VERSION ""

NS_ :

BS_:

BU_: DAS

BO_ 283 ASD_A2: 5 Vector__XXX
 SG_ CurrentLevel : 16|3@1+ (1,0) [0|7] ""  DAS

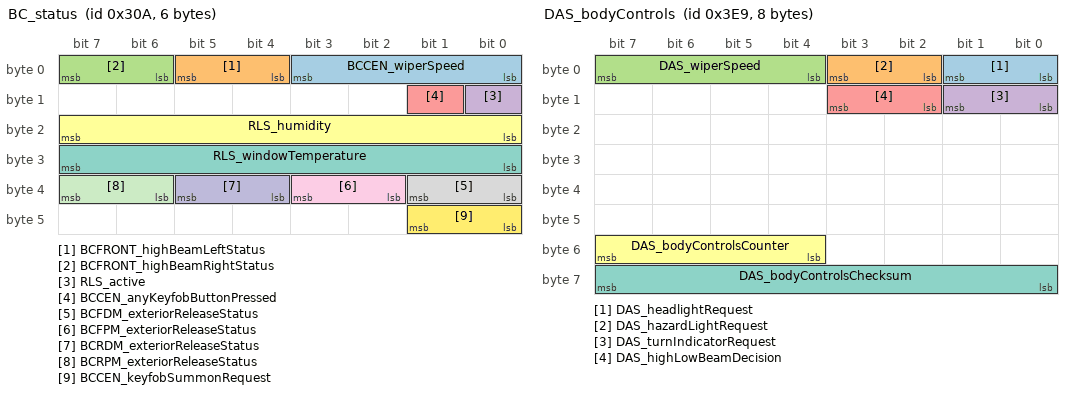
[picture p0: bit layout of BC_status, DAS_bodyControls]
BO_ 778 BC_status: 6 Vector__XXX
 SG_ BCCEN_wiperSpeed : 3|4@0+ (1,0) [0|15] ""  DAS
 SG_ BCFRONT_highBeamLeftStatus : 4|2@1+ (1,0) [0|3] ""  DAS
 SG_ BCFRONT_highBeamRightStatus : 6|2@1+ (1,0) [0|3] ""  DAS
 SG_ RLS_active : 8|1@0+ (1,0) [0|1] ""  DAS
 SG_ BCCEN_anyKeyfobButtonPressed : 9|1@0+ (1,0) [0|1] ""  DAS
 SG_ RLS_humidity : 23|8@0+ (0.5,0) [0|100] "%"  DAS
 SG_ RLS_windowTemperature : 31|8@0+ (0.5,-40) [-40|85] "C"  DAS
 SG_ BCFDM_exteriorReleaseStatus : 32|2@1+ (1,0) [0|3] ""  DAS
 SG_ BCFPM_exteriorReleaseStatus : 34|2@1+ (1,0) [0|3] ""  DAS
 SG_ BCRDM_exteriorReleaseStatus : 36|2@1+ (1,0) [0|3] ""  DAS
 SG_ BCRPM_exteriorReleaseStatus : 38|2@1+ (1,0) [0|3] ""  DAS
 SG_ BCCEN_keyfobSummonRequest : 40|2@1+ (1,0) [0|3] ""  DAS

BO_ 1465 DAS_alertLog: 8 DAS
 SG_ DAS_alertID M : 0|15@1+ (1,0) [0|0] "" Vector__XXX
 SG_ DAS_alertType : 15|1@1+ (1,0) [0|0] "" Vector__XXX
 SG_ DAS_alertDataW0 m0 : 16|16@1+ (1,0) [0|0] "" Vector__XXX
 SG_ DAS_alertDataW1 m0 : 32|16@1+ (1,0) [0|0] "" Vector__XXX
 SG_ DAS_alertDataW2 m0 : 48|16@1+ (1,0) [0|0] "" Vector__XXX
 SG_ DAS_sw004_radHWFailure m4 : 17|1@1+ (1,0) [0|0] "" Vector__XXX
 SG_ DAS_sw004_radSensorBlind m4 : 18|1@1+ (1,0) [0|0] "" Vector__XXX
 SG_ DAS_sw004_radSGUFailure m4 : 19|1@1+ (1,0) [0|0] "" Vector__XXX
 SG_ DAS_sw004_radMia m4 : 20|1@1+ (1,0) [0|0] "" Vector__XXX
 SG_ DAS_sw004_espMIA m4 : 23|1@1+ (1,0) [0|0] "" Vector__XXX
 SG_ DAS_sw004_accState m4 : 24|4@1+ (1,0) [0|0] "" Vector__XXX
 SG_ DAS_sw004_appMobileyeStatus m4 : 28|5@1+ (1,0) [0|0] "" Vector__XXX
 SG_ DAS_sw004_diCruiseStateFault m4 : 33|1@1+ (1,0) [0|0] "" Vector__XXX
 SG_ DAS_sw004_diMIA m4 : 34|1@1+ (1,0) [0|0] "" Vector__XXX
 SG_ DAS_sw004_accelPedalInvalid m4 : 35|1@1+ (1,0) [0|0] "" Vector__XXX
 SG_ DAS_sw004_stwAngleInvalid m4 : 36|1@1+ (1,0) [0|0] "" Vector__XXX
 SG_ DAS_sw004_accelerationInvalid m4 : 37|1@1+ (1,0) [0|0] "" Vector__XXX
 SG_ DAS_sw004_diSpeedInvalid m4 : 38|1@1+ (1,0) [0|0] "" Vector__XXX
 SG_ DAS_sw004_DASFeaturesDisabled m4 : 40|1@1+ (1,0) [0|0] "" Vector__XXX
 SG_ DAS_sw004_appMobileyeNotInVision m4 : 41|1@1+ (1,0) [0|0] "" Vector__XXX
 SG_ DAS_sw004_CamCommonMIA m4 : 42|1@1+ (1,0) [0|0] "" Vector__XXX
 SG_ DAS_sw004_CamObjectsMIA m4 : 43|1@1+ (1,0) [0|0] "" Vector__XXX
 SG_ DAS_sw004_CamWatchdog m4 : 44|1@1+ (1,0) [0|0] "" Vector__XXX
 SG_ DAS_sw004_RadarLowVisibility m4 : 45|1@1+ (1,0) [0|0] "" Vector__XXX
 SG_ DAS_sw004_RadarMisalignment m4 : 46|1@1+ (1,0) [0|0] "" Vector__XXX
 SG_ DAS_sw004_OutOfFocusImage m4 : 47|1@1+ (1,0) [0|0] "" Vector__XXX
 SG_ DAS_sw004_ImpairedVD m4 : 48|1@1+ (1,0) [0|0] "" Vector__XXX
 SG_ DAS_sw004_SunRay m4 : 49|1@1+ (1,0) [0|0] "" Vector__XXX
 SG_ DAS_sw004_Splashes m4 : 50|1@1+ (1,0) [0|0] "" Vector__XXX
 SG_ DAS_sw004_BlurredImage m4 : 51|1@1+ (1,0) [0|0] "" Vector__XXX
 SG_ DAS_sw004_LowSun m4 : 52|1@1+ (1,0) [0|0] "" Vector__XXX
 SG_ DAS_sw004_SmearedSpots m4 : 53|1@1+ (1,0) [0|0] "" Vector__XXX
 SG_ DAS_sw004_PartialBlockage m4 : 54|1@1+ (1,0) [0|0] "" Vector__XXX
 SG_ DAS_sw004_AutofixOutOfCalib m4 : 55|1@1+ (1,0) [0|0] "" Vector__XXX
 SG_ DAS_sw004_AutofixOutOfCalibHorzn m4 : 56|1@1+ (1,0) [0|0] "" Vector__XXX
 SG_ DAS_sw004_AutofixOutOfCalibYaw m4 : 57|1@1+ (1,0) [0|0] "" Vector__XXX
 SG_ DAS_sw004_FullBlockage m4 : 58|1@1+ (1,0) [0|0] "" Vector__XXX
 SG_ DAS_sw004_SmearedHalos m4 : 59|1@1+ (1,0) [0|0] "" Vector__XXX
 SG_ DAS_sw004_FoggyLights m4 : 60|1@1+ (1,0) [0|0] "" Vector__XXX
 SG_ DAS_sw004_SelfGlare m4 : 61|1@1+ (1,0) [0|0] "" Vector__XXX
 SG_ DAS_sw005_AutofixOutOfCalib m5 : 16|1@1+ (1,0) [0|0] "" Vector__XXX
 SG_ DAS_sw005_AutofixOutOfCalibYaw m5 : 17|1@1+ (1,0) [0|0] "" Vector__XXX
 SG_ DAS_sw005_RadarMisalignment m5 : 18|1@1+ (1,0) [0|0] "" Vector__XXX
 SG_ DAS_sw005_partialBlockage m5 : 20|1@1+ (1,0) [0|0] "" Vector__XXX
 SG_ DAS_sw005_fullBlockage m5 : 21|1@1+ (1,0) [0|0] "" Vector__XXX
 SG_ DAS_sw005_camObjHeader m5 : 22|1@1+ (1,0) [0|0] "" Vector__XXX
 SG_ DAS_sw005_camCommonMsg m5 : 23|1@1+ (1,0) [0|0] "" Vector__XXX
 SG_ DAS_sw005_camFcwPcwMsg m5 : 24|1@1+ (1,0) [0|0] "" Vector__XXX
 SG_ DAS_sw005_radHWFailure m5 : 25|1@1+ (1,0) [0|0] "" Vector__XXX
 SG_ DAS_sw005_radSensorBlind m5 : 26|1@1+ (1,0) [0|0] "" Vector__XXX
 SG_ DAS_sw005_radSGUFailure m5 : 27|1@1+ (1,0) [0|0] "" Vector__XXX
 SG_ DAS_sw005_radMia m5 : 28|1@1+ (1,0) [0|0] "" Vector__XXX
 SG_ DAS_sw005_brakePedal m5 : 29|1@1+ (1,0) [0|0] "" Vector__XXX
 SG_ DAS_sw005_steeringAngle m5 : 30|1@1+ (1,0) [0|0] "" Vector__XXX
 SG_ DAS_sw005_steeringAngleRate m5 : 31|1@1+ (1,0) [0|0] "" Vector__XXX
 SG_ DAS_sw005_speed m5 : 32|1@1+ (1,0) [0|0] "" Vector__XXX
 SG_ DAS_sw005_gear m5 : 33|1@1+ (1,0) [0|0] "" Vector__XXX
 SG_ DAS_sw005_espState m5 : 34|1@1+ (1,0) [0|0] "" Vector__XXX
 SG_ DAS_sw005_blinkers m5 : 35|1@1+ (1,0) [0|0] "" Vector__XXX
 SG_ DAS_sw005_yaw m5 : 36|1@1+ (1,0) [0|0] "" Vector__XXX
 SG_ DAS_sw005_longAccel m5 : 37|1@1+ (1,0) [0|0] "" Vector__XXX
 SG_ DAS_sw005_accelPedal m5 : 38|1@1+ (1,0) [0|0] "" Vector__XXX
 SG_ DAS_sw005_torqueDriver m5 : 40|1@1+ (1,0) [0|0] "" Vector__XXX
 SG_ DAS_sw005_fcmSensitivity m5 : 41|1@1+ (1,0) [0|0] "" Vector__XXX
 SG_ DAS_sw005_dasDisabled m5 : 42|1@1+ (1,0) [0|0] "" Vector__XXX
 SG_ DAS_sw005_speedDerivative m5 : 43|1@1+ (1,0) [0|0] "" Vector__XXX
 SG_ DAS_sw005_camWatchdog m5 : 44|1@1+ (1,0) [0|0] "" Vector__XXX
 SG_ DAS_sw005_AutofixOutOfCalibHorzn m5 : 45|1@1+ (1,0) [0|0] "" Vector__XXX
 SG_ DAS_sw005_RadarLowVisibility m5 : 46|1@1+ (1,0) [0|0] "" Vector__XXX
 SG_ DAS_sw006_RadarLowVisibility m6 : 16|1@1+ (1,0) [0|0] "" Vector__XXX
 SG_ DAS_sw006_RadarMisaligned m6 : 17|1@1+ (1,0) [0|0] "" Vector__XXX
 SG_ DAS_sw006_OutOfFocusImage m6 : 18|1@1+ (1,0) [0|0] "" Vector__XXX
 SG_ DAS_sw006_SunRay m6 : 19|1@1+ (1,0) [0|0] "" Vector__XXX
 SG_ DAS_sw006_Splashes m6 : 20|1@1+ (1,0) [0|0] "" Vector__XXX
 SG_ DAS_sw006_BlurredImage m6 : 21|1@1+ (1,0) [0|0] "" Vector__XXX
 SG_ DAS_sw006_LowSun m6 : 22|1@1+ (1,0) [0|0] "" Vector__XXX
 SG_ DAS_sw006_SmearedSpots m6 : 23|1@1+ (1,0) [0|0] "" Vector__XXX
 SG_ DAS_sw006_PartialBlockage m6 : 24|1@1+ (1,0) [0|0] "" Vector__XXX
 SG_ DAS_sw006_AutofixOutOfCalib m6 : 25|1@1+ (1,0) [0|0] "" Vector__XXX
 SG_ DAS_sw006_AutofixOutOfCalibHorzn m6 : 26|1@1+ (1,0) [0|0] "" Vector__XXX
 SG_ DAS_sw006_AutofixOutOfCalibYaw m6 : 27|1@1+ (1,0) [0|0] "" Vector__XXX
 SG_ DAS_sw006_FullBlockage m6 : 28|1@1+ (1,0) [0|0] "" Vector__XXX
 SG_ DAS_sw006_SmearedHalos m6 : 29|1@1+ (1,0) [0|0] "" Vector__XXX
 SG_ DAS_sw006_FoggyLights m6 : 30|1@1+ (1,0) [0|0] "" Vector__XXX
 SG_ DAS_sw006_SelfGlare m6 : 31|1@1+ (1,0) [0|0] "" Vector__XXX
 SG_ DAS_sw006_blinkers m6 : 32|1@1+ (1,0) [0|0] "" Vector__XXX
 SG_ DAS_sw006_seatbelt m6 : 33|1@1+ (1,0) [0|0] "" Vector__XXX
 SG_ DAS_sw006_accelPedal m6 : 34|1@1+ (1,0) [0|0] "" Vector__XXX
 SG_ DAS_sw006_radMia m6 : 35|1@1+ (1,0) [0|0] "" Vector__XXX
 SG_ DAS_sw006_radHWFailure m6 : 37|1@1+ (1,0) [0|0] "" Vector__XXX
 SG_ DAS_sw006_radSensorBlind m6 : 38|1@1+ (1,0) [0|0] "" Vector__XXX
 SG_ DAS_sw006_radSGUFailure m6 : 39|1@1+ (1,0) [0|0] "" Vector__XXX
 SG_ DAS_sw006_brakePedal m6 : 40|1@1+ (1,0) [0|0] "" Vector__XXX
 SG_ DAS_sw006_steeringAngle m6 : 41|1@1+ (1,0) [0|0] "" Vector__XXX
 SG_ DAS_sw006_steeringAngleRate m6 : 42|1@1+ (1,0) [0|0] "" Vector__XXX
 SG_ DAS_sw006_speed m6 : 43|1@1+ (1,0) [0|0] "" Vector__XXX
 SG_ DAS_sw006_gear m6 : 44|1@1+ (1,0) [0|0] "" Vector__XXX
 SG_ DAS_sw006_espState m6 : 45|1@1+ (1,0) [0|0] "" Vector__XXX
 SG_ DAS_sw006_torqueDriver m6 : 46|1@1+ (1,0) [0|0] "" Vector__XXX
 SG_ DAS_sw006_dasDisabled m6 : 47|1@1+ (1,0) [0|0] "" Vector__XXX
 SG_ DAS_sw006_speedDerivative m6 : 48|1@1+ (1,0) [0|0] "" Vector__XXX
 SG_ DAS_sw006_camWatchdog m6 : 49|1@1+ (1,0) [0|0] "" Vector__XXX
 SG_ DAS_sw006_camObjHeader m6 : 50|1@1+ (1,0) [0|0] "" Vector__XXX
 SG_ DAS_sw006_camCommonMsg m6 : 51|1@1+ (1,0) [0|0] "" Vector__XXX
 SG_ DAS_sw006_camFcwPcwMsg m6 : 52|1@1+ (1,0) [0|0] "" Vector__XXX
 SG_ DAS_sw006_longAccel m6 : 53|1@1+ (1,0) [0|0] "" Vector__XXX
 SG_ DAS_sw006_yawRate m6 : 54|1@1+ (1,0) [0|0] "" Vector__XXX
 SG_ DAS_sw006_DIaebState_SNA m6 : 55|1@1+ (1,0) [0|0] "" Vector__XXX
 SG_ DAS_sw006_DIaebStateUnavailable m6 : 56|1@1+ (1,0) [0|0] "" Vector__XXX
 SG_ DAS_sw006_brakeLights m6 : 57|1@1+ (1,0) [0|0] "" Vector__XXX
 SG_ DAS_sw006_trailerMode m6 : 58|1@1+ (1,0) [0|0] "" Vector__XXX
 SG_ DAS_sw006_timeOfDay m6 : 59|2@1+ (1,0) [0|0] "" Vector__XXX
 SG_ DAS_sw009_DIaebState_fault m9 : 16|1@1+ (1,0) [0|0] "" Vector__XXX
 SG_ DAS_sw009_DI_aeb_unresponsive m9 : 17|1@1+ (1,0) [0|0] "" Vector__XXX
 SG_ DAS_sw009_DI_MIA m9 : 18|1@1+ (1,0) [0|0] "" Vector__XXX
 SG_ DAS_sw010_a04calibNotDone m10 : 16|1@1+ (1,0) [0|0] "" Vector__XXX
 SG_ DAS_sw010_a05calibReqd m10 : 17|1@1+ (1,0) [0|0] "" Vector__XXX
 SG_ DAS_sw010_a06calibNotOK m10 : 18|1@1+ (1,0) [0|0] "" Vector__XXX
 SG_ DAS_sw010_a08PlantMode m10 : 19|1@1+ (1,0) [0|0] "" Vector__XXX
 SG_ DAS_sw010_HorizontalMisalignment m10 : 20|16@1+ (0.00137332,-45) [-45|45.0005262] "deg" Vector__XXX
 SG_ DAS_sw010_VerticalMisalignment m10 : 36|10@1+ (0.087977,-45) [-45|45.000471] "deg" Vector__XXX
 SG_ DAS_sw010_unusedBits m10 : 46|2@1+ (1,0) [0|0] "" Vector__XXX
 SG_ DAS_sw010_VmaPlausibility m10 : 48|16@1+ (1.52587890625005E-005,0) [0|0.99998474121097] "" Vector__XXX
 SG_ DAS_sw011_scaState m11 : 16|3@1+ (1,0) [0|7] "" Vector__XXX
 SG_ DAS_sw011_scaLeft m11 : 19|1@1+ (1,0) [0|1] "" Vector__XXX
 SG_ DAS_sw011_scaRight m11 : 20|1@1+ (1,0) [0|1] "" Vector__XXX
 SG_ DAS_sw011_scaBlinker m11 : 21|2@1+ (1,0) [0|3] "" Vector__XXX
 SG_ DAS_sw011_scaThreshold m11 : 23|1@1+ (1,0) [0|1] "" Vector__XXX
 SG_ DAS_sw011_scaSpeed m11 : 24|7@1+ (1,0) [0|127] "MPH" Vector__XXX
 SG_ DAS_sw011_scaSonicDist m11 : 31|5@1+ (0.05,0) [0|1.5] "m" Vector__XXX
 SG_ DAS_sw011_scaSteerAngle m11 : 38|10@1+ (0.1,-51.2) [-51.2|51.1] "deg" Vector__XXX
 SG_ DAS_sw011_egoRightOfCenter m11 : 48|1@1+ (1,0) [0|1] "" Vector__XXX
 SG_ DAS_sw011_egoMovingRight m11 : 49|1@1+ (1,0) [0|1] "" Vector__XXX
 SG_ DAS_sw011_egoLeftOfCenter m11 : 50|1@1+ (1,0) [0|1] "" Vector__XXX
 SG_ DAS_sw011_egoMovingLeft m11 : 51|1@1+ (1,0) [0|1] "" Vector__XXX
 SG_ DAS_sw011_polyValid m11 : 52|1@1+ (1,0) [0|1] "" Vector__XXX
 SG_ DAS_sw011_egoCentered m11 : 53|1@1+ (1,0) [0|1] "" Vector__XXX
 SG_ DAS_sw011_scaReasonEldw m11 : 54|1@1+ (1,0) [0|1] "" Vector__XXX
 SG_ DAS_sw011_laneWidth m11 : 56|8@1+ (0.025,0) [0|6.375] "m" Vector__XXX
 SG_ DAS_sw012_bootTestResults m12 : 16|16@1+ (1,0) [0|65535] "" Vector__XXX
 SG_ DAS_sw012_bootDDRTempStatus m12 : 32|2@1+ (1,0) [0|3] "" Vector__XXX
 SG_ DAS_sw012_mespFatalErrCode m12 : 34|8@1+ (1,0) [0|255] "" Vector__XXX
 SG_ DAS_sw012_mespFatalErrDetails m12 : 42|8@1+ (1,0) [0|255] "" Vector__XXX
 SG_ DAS_sw012_mespDDRTempStatus m12 : 50|3@1+ (1,0) [0|7] "" Vector__XXX
 SG_ DAS_sw012_freescaleTemp m12 : 56|8@1- (1,0) [-128|127] "degC" Vector__XXX
 SG_ DAS_sw013_stateBeforeWatchdog m13 : 16|5@1+ (1,0) [0|0] "" Vector__XXX
 SG_ DAS_sw013_numEyeqResets m13 : 21|3@1+ (1,0) [0|0] "" Vector__XXX
 SG_ DAS_sw013_numCrcErrors m13 : 24|8@1+ (1,0) [0|0] "" Vector__XXX
 SG_ DAS_sw013_numSeqErrors m13 : 32|8@1+ (1,0) [0|0] "" Vector__XXX
 SG_ DAS_sw013_numNaksReceived m13 : 40|8@1+ (1,0) [0|0] "" Vector__XXX
 SG_ DAS_sw013_highestSeqRecd m13 : 48|12@1+ (1,0) [0|0] "" Vector__XXX
 SG_ DAS_sw013_numTransportErrors m13 : 60|4@1+ (1,0) [0|0] "" Vector__XXX
 SG_ DAS_sw014_fileNameHash m14 : 16|16@1+ (1,0) [0|0] "" Vector__XXX
 SG_ DAS_sw014_lineNumberInCode m14 : 32|16@1+ (1,0) [0|0] "" Vector__XXX
 SG_ DAS_sw014_assertData m14 : 48|16@1+ (1,0) [0|0] "" Vector__XXX
 SG_ DAS_sw015_RadarLowVisibility m15 : 16|2@1+ (1,0) [0|1] "" Vector__XXX
 SG_ DAS_sw015_RadarMisalignment m15 : 18|2@1+ (1,0) [0|1] "" Vector__XXX
 SG_ DAS_sw015_LowSun m15 : 20|2@1+ (1,0) [0|1] "" Vector__XXX
 SG_ DAS_sw015_BlurredImage m15 : 22|2@1+ (1,0) [0|1] "" Vector__XXX
 SG_ DAS_sw015_FullBlockage m15 : 24|2@1+ (1,0) [0|1] "" Vector__XXX
 SG_ DAS_sw015_PartialBlockage m15 : 26|2@1+ (1,0) [0|1] "" Vector__XXX
 SG_ DAS_sw015_AutofixOutOfCalib m15 : 28|2@1+ (1,0) [0|1] "" Vector__XXX
 SG_ DAS_sw015_AutofixOutOfCalibYaw m15 : 30|2@1+ (1,0) [0|1] "" Vector__XXX
 SG_ DAS_sw015_AutofixOOfCalibHorizon m15 : 32|2@1+ (1,0) [0|1] "" Vector__XXX
 SG_ DAS_sw015_Splashes m15 : 34|2@1+ (1,0) [0|1] "" Vector__XXX
 SG_ DAS_sw015_SmearedSpots m15 : 36|2@1+ (1,0) [0|1] "" Vector__XXX
 SG_ DAS_sw015_SmearedHalos m15 : 38|2@1+ (1,0) [0|1] "" Vector__XXX
 SG_ DAS_sw015_FoggyLights m15 : 40|2@1+ (1,0) [0|1] "" Vector__XXX
 SG_ DAS_sw015_SunRay m15 : 42|2@1+ (1,0) [0|1] "" Vector__XXX
 SG_ DAS_sw015_ImpairedVD m15 : 44|2@1+ (1,0) [0|1] "" Vector__XXX
 SG_ DAS_sw015_SelfGlare m15 : 46|2@1+ (1,0) [0|1] "" Vector__XXX
 SG_ DAS_sw015_OutOfFocusImage m15 : 48|2@1+ (1,0) [0|1] "" Vector__XXX
 SG_ DAS_sw015_MainCameraLowLight m15 : 50|2@1+ (1,0) [0|1] "" Vector__XXX
 SG_ DAS_sw015_NarrowCameraLowLight m15 : 52|2@1+ (1,0) [0|1] "" Vector__XXX
 SG_ DAS_sw015_MainCameraBadAssoc m15 : 54|2@1+ (1,0) [0|1] "" Vector__XXX
 SG_ DAS_sw015_NarrowCameraBadAssoc m15 : 56|2@1+ (1,0) [0|1] "" Vector__XXX
 SG_ DAS_sw016_targetDist m16 : 16|9@1+ (0.2,0) [0|102.2] "m" Vector__XXX
 SG_ DAS_sw016_targetRelSpeed m16 : 25|9@1+ (0.0625,-31) [-31|0.9375] "m/s" Vector__XXX
 SG_ DAS_sw016_targetOverlap m16 : 34|6@1+ (0.1,0) [0|6.3] "m" Vector__XXX
 SG_ DAS_sw016_hostSpeed m16 : 40|8@1+ (1,0) [0|255] "kph" Vector__XXX
 SG_ DAS_sw016_hostLongAccel m16 : 48|7@1+ (0.15625,-10) [-10|10] "m/s^2" Vector__XXX
 SG_ DAS_sw016_driverPressedAccelPed m16 : 55|1@1+ (1,0) [0|1] "" Vector__XXX
 SG_ DAS_sw016_driverPressedBrakePed m16 : 56|1@1+ (1,0) [0|1] "" Vector__XXX
 SG_ DAS_sw016_aebEnable m16 : 57|1@1+ (1,0) [0|1] "" Vector__XXX
 SG_ DAS_sw016_overrideBlinker m16 : 58|1@1+ (1,0) [0|1] "" Vector__XXX
 SG_ DAS_sw016_overrideBrake m16 : 59|1@1+ (1,0) [0|1] "" Vector__XXX
 SG_ DAS_sw016_overrideSteer m16 : 60|1@1+ (1,0) [0|1] "" Vector__XXX
 SG_ DAS_sw016_fcmModeAtEvent m16 : 61|2@1+ (1,0) [0|3] "" Vector__XXX
 SG_ DAS_sw016_accActive m16 : 63|1@1+ (1,0) [0|1] "" Vector__XXX
 SG_ DAS_sw017_Camera_Msg_Lanes_MIA m17 : 16|1@1+ (1,0) [0|1] "" Vector__XXX
 SG_ DAS_sw017_Camera_Msg_Objects_MIA m17 : 17|1@1+ (1,0) [0|1] "" Vector__XXX
 SG_ DAS_sw017_Camera_Msg_Tsr_MIA m17 : 18|1@1+ (1,0) [0|1] "" Vector__XXX
 SG_ DAS_sw017_Camera_Msg_Hlb_MIA m17 : 19|1@1+ (1,0) [0|1] "" Vector__XXX
 SG_ DAS_sw017_Camera_Msg_Common_MIA m17 : 20|1@1+ (1,0) [0|1] "" Vector__XXX
 SG_ DAS_sw017_Camera_Msg_FCW_PCW_MIA m17 : 21|1@1+ (1,0) [0|1] "" Vector__XXX
 SG_ DAS_sw017_Camera_Msg_TFL_MIA m17 : 22|1@1+ (1,0) [0|1] "" Vector__XXX
 SG_ DAS_sw017_Any_Lanes_Msg_Recd m17 : 23|1@1+ (1,0) [0|1] "" Vector__XXX
 SG_ DAS_sw017_Any_Objects_Msg_Recd m17 : 24|1@1+ (1,0) [0|1] "" Vector__XXX
 SG_ DAS_sw017_Any_TFL_Msg_Recd m17 : 25|1@1+ (1,0) [0|1] "" Vector__XXX
 SG_ DAS_sw017_numCrcErrors m17 : 26|6@1+ (1,0) [0|63] "" Vector__XXX
 SG_ DAS_sw017_numSeqErrors m17 : 32|8@1+ (1,0) [0|255] "" Vector__XXX
 SG_ DAS_sw017_numTransportErrors m17 : 40|8@1+ (1,0) [0|0] "" Vector__XXX
 SG_ DAS_sw017_highestSeqRecd m17 : 48|12@1+ (1,0) [0|0] "" Vector__XXX
 SG_ DAS_sw017_Any_Tsr_Msg_Recd m17 : 60|1@1+ (1,0) [0|1] "" Vector__XXX
 SG_ DAS_sw017_Any_Hlb_Msg_Recd m17 : 61|1@1+ (1,0) [0|1] "" Vector__XXX
 SG_ DAS_sw017_Any_Common_Msg_Recd m17 : 62|1@1+ (1,0) [0|1] "" Vector__XXX
 SG_ DAS_sw017_Any_FCW_PCW_Msg_Recd m17 : 63|1@1+ (1,0) [0|1] "" Vector__XXX
 SG_ DAS_sw018_minThreshold m18 : 16|13@1+ (1,0) [0|4500] "mV" Vector__XXX
 SG_ DAS_sw018_railID m18 : 29|2@1+ (1,0) [0|3] "" Vector__XXX
 SG_ DAS_sw018_powerSequnceError m18 : 31|1@1+ (1,0) [0|3] "" Vector__XXX
 SG_ DAS_sw018_maxThreshold m18 : 32|15@1+ (1,0) [50|5500] "mV" Vector__XXX
 SG_ DAS_sw018_railControl m18 : 47|1@1+ (1,0) [0|1] "" Vector__XXX
 SG_ DAS_sw018_currentVoltage m18 : 48|16@1+ (1,0) [0|6600] "mV" Vector__XXX
 SG_ DAS_sw019_taskId m19 : 16|8@1+ (1,0) [0|0] "" Vector__XXX
 SG_ DAS_sw019_numFreeBytes m19 : 24|8@1+ (1,-191) [-191|64] "# of bytes" Vector__XXX
 SG_ DAS_sw019_timeStamp m19 : 32|32@1+ (1,0) [0|4294967295] "ms" Vector__XXX
 SG_ DAS_sw020_unusedW0 m20 : 16|16@1+ (1,0) [0|0] "" Vector__XXX
 SG_ DAS_sw020_unusedW1 m20 : 32|16@1+ (1,0) [0|0] "" Vector__XXX
 SG_ DAS_sw020_unusedW2 m20 : 48|16@1+ (1,0) [0|0] "" Vector__XXX
 SG_ DAS_sw021_tempSensorId m21 : 16|8@1+ (1,0) [0|4] "" Vector__XXX
 SG_ DAS_sw021_minThreshold m21 : 24|8@1- (1,0) [-128|127] "degC" Vector__XXX
 SG_ DAS_sw021_maxThreshold m21 : 32|8@1- (1,0) [-128|127] "degC" Vector__XXX
 SG_ DAS_sw021_currentTemperature m21 : 40|8@1- (1,0) [-128|127] "degC" Vector__XXX
 SG_ DAS_sw021_unusedWord m21 : 48|16@1+ (1,0) [0|0] "" Vector__XXX
 SG_ DAS_sw022_operation m22 : 16|4@1+ (1,0) [0|0] "" Vector__XXX
 SG_ DAS_sw022_recordId m22 : 20|12@1+ (1,0) [0|0] "" Vector__XXX
 SG_ DAS_sw022_errorCode m22 : 32|32@1+ (1,0) [0|0] "" Vector__XXX
 SG_ DAS_sw024_Task_ID m24 : 16|4@1+ (1,0) [0|0] "" Vector__XXX
 SG_ DAS_sw024_numVirtualLaneVeh m24 : 20|4@1+ (1,0) [0|0] "" Vector__XXX
 SG_ DAS_sw024_currentVehicleApp m24 : 24|8@1+ (1,0) [0|0] "" Vector__XXX
 SG_ DAS_sw024_taskProgramCounter m24 : 32|32@1+ (1,0) [0|0] "" Vector__XXX
 SG_ DAS_sw025_state_before_override m25 : 16|4@1+ (1,0) [0|15] "" Vector__XXX
 SG_ DAS_sw025_road_class m25 : 20|3@1+ (1,0) [0|0] "" Vector__XXX
 SG_ DAS_sw025_road_match m25 : 23|1@1+ (1,0) [0|0] "" Vector__XXX
 SG_ DAS_sw025_controlled_access m25 : 24|1@1+ (1,0) [0|0] "" Vector__XXX
 SG_ DAS_sw025_leftLaneUsage m25 : 25|2@1+ (1,0) [0|3] "" Vector__XXX
 SG_ DAS_sw025_rightLaneUsage m25 : 27|2@1+ (1,0) [0|3] "" Vector__XXX
 SG_ DAS_sw025_vehiclesUsage m25 : 29|2@1+ (1,0) [0|3] "" Vector__XXX
 SG_ DAS_sw025_hppUsage m25 : 31|2@1+ (1,0) [0|3] "" Vector__XXX
 SG_ DAS_sw025_navigationUsage m25 : 33|2@1+ (1,0) [0|3] "" Vector__XXX
 SG_ DAS_sw025_modelUsage m25 : 35|2@1+ (1,0) [0|3] "" Vector__XXX
 SG_ DAS_sw025_bottsDotsUsage m25 : 37|2@1+ (1,0) [0|3] "" Vector__XXX
 SG_ DAS_sw025_offsetSide m25 : 39|2@1+ (1,0) [0|3] "" Vector__XXX
 SG_ DAS_sw026_task_id m26 : 16|2@1+ (1,0) [0|3] "" Vector__XXX
 SG_ DAS_sw026_tardiness m26 : 18|9@1+ (0.25,0) [0|127.75] "ms" Vector__XXX
 SG_ DAS_sw026_execution_time m26 : 27|9@1+ (0.125,0) [0|65.411] "ms" Vector__XXX
 SG_ DAS_sw026_can_mean_utilization m26 : 36|7@1+ (1,0) [0|127] "percent" Vector__XXX
 SG_ DAS_sw026_uds_mean_utilization m26 : 43|7@1+ (1,0) [0|127] "percent" Vector__XXX
 SG_ DAS_sw026_mob_mean_utilization m26 : 50|7@1+ (1,0) [0|127] "percent" Vector__XXX
 SG_ DAS_sw026_veh_mean_utilization m26 : 57|7@1+ (1,0) [0|127] "percent" Vector__XXX
 SG_ DAS_sw027_JTAG_Reset m27 : 16|1@1+ (1,0) [0|0] "" Vector__XXX
 SG_ DAS_sw027_Core_Reset m27 : 17|1@1+ (1,0) [0|0] "" Vector__XXX
 SG_ DAS_sw027_Unused_Bit_0 m27 : 18|1@1+ (1,0) [0|0] "" Vector__XXX
 SG_ DAS_sw027_CPU_Checkstop_Error m27 : 19|1@1+ (1,0) [0|0] "" Vector__XXX
 SG_ DAS_sw027_PLL_0_Failure m27 : 20|1@1+ (1,0) [0|0] "" Vector__XXX
 SG_ DAS_sw027_Clock_Monitor_0_Low m27 : 21|1@1+ (1,0) [0|0] "" Vector__XXX
 SG_ DAS_sw027_Clock_Monitor_0_Off m27 : 22|1@1+ (1,0) [0|0] "" Vector__XXX
 SG_ DAS_sw027_LVD_4v5 m27 : 23|1@1+ (1,0) [0|0] "" Vector__XXX
 SG_ DAS_sw027_Flash_Fatal_Error m27 : 24|1@1+ (1,0) [0|0] "" Vector__XXX
 SG_ DAS_sw027_PLL_1_Failure m27 : 25|1@1+ (1,0) [0|0] "" Vector__XXX
 SG_ DAS_sw027_Unused_Bit_1 m27 : 26|1@1+ (1,0) [0|0] "" Vector__XXX
 SG_ DAS_sw027_f_PLL_1_Off m27 : 27|1@1+ (1,0) [0|0] "" Vector__XXX
 SG_ DAS_sw027_Unused_Nibble m27 : 28|4@1+ (1,0) [0|0] "" Vector__XXX
 SG_ DAS_sw027_LVD_1v2 m27 : 32|1@1+ (1,0) [0|0] "" Vector__XXX
 SG_ DAS_sw027_Unused_Bit_2 m27 : 33|1@1+ (1,0) [0|0] "" Vector__XXX
 SG_ DAS_sw027_Watchdog m27 : 34|1@1+ (1,0) [0|0] "" Vector__XXX
 SG_ DAS_sw027_Unused_Bit_3 m27 : 35|1@1+ (1,0) [0|0] "" Vector__XXX
 SG_ DAS_sw027_LVD_2v7_VREG m27 : 36|1@1+ (1,0) [0|0] "" Vector__XXX
 SG_ DAS_sw027_LVD_2v7_Flash m27 : 37|1@1+ (1,0) [0|0] "" Vector__XXX
 SG_ DAS_sw027_LVD_2v7_IO m27 : 38|1@1+ (1,0) [0|0] "" Vector__XXX
 SG_ DAS_sw027_Unused_Bit_4 m27 : 39|1@1+ (1,0) [0|0] "" Vector__XXX
 SG_ DAS_sw027_Unused_Byte m27 : 40|8@1+ (1,0) [0|0] "" Vector__XXX
 SG_ DAS_sw027_ESR0 m27 : 48|1@1+ (1,0) [0|0] "" Vector__XXX
 SG_ DAS_sw027_ESR1 m27 : 49|1@1+ (1,0) [0|0] "" Vector__XXX
 SG_ DAS_sw027_SW m27 : 50|1@1+ (1,0) [0|0] "" Vector__XXX
 SG_ DAS_sw027_STM0 m27 : 51|1@1+ (1,0) [0|0] "" Vector__XXX
 SG_ DAS_sw027_STM1 m27 : 52|1@1+ (1,0) [0|0] "" Vector__XXX
 SG_ DAS_sw027_STM2 m27 : 53|1@1+ (1,0) [0|0] "" Vector__XXX
 SG_ DAS_sw027_CBS_SYSTEM m27 : 54|1@1+ (1,0) [0|0] "" Vector__XXX
 SG_ DAS_sw027_CBS_DEBUG m27 : 55|1@1+ (1,0) [0|0] "" Vector__XXX
 SG_ DAS_sw027_CBS_APP m27 : 56|1@1+ (1,0) [0|0] "" Vector__XXX
 SG_ DAS_sw027_EVR13 m27 : 57|1@1+ (1,0) [0|0] "" Vector__XXX
 SG_ DAS_sw027_EVR33 m27 : 58|1@1+ (1,0) [0|0] "" Vector__XXX
 SG_ DAS_sw027_SWD m27 : 59|1@1+ (1,0) [0|0] "" Vector__XXX
 SG_ DAS_sw027_STDBY_WDG m27 : 60|1@1+ (1,0) [0|0] "" Vector__XXX
 SG_ DAS_sw027_PORST m27 : 61|1@1+ (1,0) [0|0] "" Vector__XXX
 SG_ DAS_sw027_Unused_word m27 : 62|2@1+ (1,0) [0|0] "" Vector__XXX
 SG_ DAS_sw028_rx_buffer_full m28 : 16|1@1+ (1,0) [0|0] "" Vector__XXX
 SG_ DAS_sw028_rx_inv_len m28 : 17|1@1+ (1,0) [0|0] "" Vector__XXX
 SG_ DAS_sw028_inv_multifrm_1st m28 : 18|1@1+ (1,0) [0|0] "" Vector__XXX
 SG_ DAS_sw028_inv_multifrm_id m28 : 19|1@1+ (1,0) [0|0] "" Vector__XXX
 SG_ DAS_sw028_inv_multifrm_next m28 : 20|1@1+ (1,0) [0|0] "" Vector__XXX
 SG_ DAS_sw028_unusedBits m28 : 21|11@1+ (1,0) [0|0] "" Vector__XXX
 SG_ DAS_sw028_highestSeqRcvd m28 : 32|16@1+ (1,0) [0|0] "" Vector__XXX
 SG_ DAS_sw028_multifrm_rx_len m28 : 48|16@1+ (1,0) [0|0] "" Vector__XXX
 SG_ DAS_sw029_tx_buffer_full m29 : 16|1@1+ (1,0) [0|0] "" Vector__XXX
 SG_ DAS_sw029_unusedBits m29 : 17|15@1+ (1,0) [0|0] "" Vector__XXX
 SG_ DAS_sw029_highestSeqRcvd m29 : 32|16@1+ (1,0) [0|0] "" Vector__XXX
 SG_ DAS_sw029_unusedW1 m29 : 48|16@1+ (1,0) [0|0] "" Vector__XXX
 SG_ DAS_sw030_heaterState m30 : 16|8@1+ (1,0) [0|0] "" Vector__XXX
 SG_ DAS_sw030_unusedByte m30 : 24|8@1+ (1,0) [0|0] "" Vector__XXX
 SG_ DAS_sw030_unusedW0 m30 : 32|16@1+ (1,0) [0|0] "" Vector__XXX
 SG_ DAS_sw030_unusedW1 m30 : 48|16@1+ (1,0) [0|0] "" Vector__XXX
 SG_ DAS_sw031_canBus m31 : 16|4@1+ (1,0) [0|0] "" Vector__XXX
 SG_ DAS_sw031_errorType m31 : 24|8@1+ (1,0) [0|0] "" Vector__XXX
 SG_ DAS_sw031_errorData1 m31 : 32|16@1+ (1,0) [0|0] "" Vector__XXX
 SG_ DAS_sw031_errorData2 m31 : 48|16@1+ (1,0) [0|0] "" Vector__XXX
 SG_ DAS_sw032_canBus m32 : 16|4@1+ (1,0) [0|0] "" Vector__XXX
 SG_ DAS_sw032_errorType m32 : 24|8@1+ (1,0) [0|0] "" Vector__XXX
 SG_ DAS_sw032_errorData1 m32 : 32|16@1+ (1,0) [0|0] "" Vector__XXX
 SG_ DAS_sw032_errorData2 m32 : 48|16@1+ (1,0) [0|0] "" Vector__XXX
 SG_ DAS_sw033_gtwMia m33 : 16|8@1+ (1,0) [0|0] "" Vector__XXX
 SG_ DAS_sw033_unusedByte m33 : 24|8@1+ (1,0) [0|0] "" Vector__XXX
 SG_ DAS_sw033_unusedW0 m33 : 32|16@1+ (1,0) [0|0] "" Vector__XXX
 SG_ DAS_sw033_unusedW1 m33 : 48|16@1+ (1,0) [0|0] "" Vector__XXX
 SG_ DAS_sw034_sccmMia m34 : 16|8@1+ (1,0) [0|0] "" Vector__XXX
 SG_ DAS_sw034_unusedByte m34 : 24|8@1+ (1,0) [0|0] "" Vector__XXX
 SG_ DAS_sw034_unusedW0 m34 : 32|16@1+ (1,0) [0|0] "" Vector__XXX
 SG_ DAS_sw034_unusedW1 m34 : 48|16@1+ (1,0) [0|0] "" Vector__XXX
 SG_ DAS_sw035_espMia m35 : 16|8@1+ (1,0) [0|0] "" Vector__XXX
 SG_ DAS_sw035_unusedByte m35 : 24|8@1+ (1,0) [0|0] "" Vector__XXX
 SG_ DAS_sw035_unusedW0 m35 : 32|16@1+ (1,0) [0|0] "" Vector__XXX
 SG_ DAS_sw035_unusedW1 m35 : 48|16@1+ (1,0) [0|0] "" Vector__XXX
 SG_ DAS_sw036_bdyMia m36 : 16|8@1+ (1,0) [0|0] "" Vector__XXX
 SG_ DAS_sw036_unusedByte m36 : 24|8@1+ (1,0) [0|0] "" Vector__XXX
 SG_ DAS_sw036_unusedW0 m36 : 32|16@1+ (1,0) [0|0] "" Vector__XXX
 SG_ DAS_sw036_unusedW1 m36 : 48|16@1+ (1,0) [0|0] "" Vector__XXX
 SG_ DAS_sw037_camera m37 : 16|8@1+ (1,0) [0|0] "" Vector__XXX
 SG_ DAS_sw037_issue m37 : 24|8@1+ (1,0) [0|0] "" Vector__XXX
 SG_ DAS_sw037_unusedW0 m37 : 32|16@1+ (1,0) [0|0] "" Vector__XXX
 SG_ DAS_sw037_unusedW1 m37 : 48|16@1+ (1,0) [0|0] "" Vector__XXX
 SG_ DAS_sw038_RadarMisalignment m38 : 17|1@1+ (1,0) [0|1] "" Vector__XXX
 SG_ DAS_sw038_OutOfFocusImage m38 : 18|1@1+ (1,0) [0|1] "" Vector__XXX
 SG_ DAS_sw038_AutofixOutOfCalib m38 : 19|1@1+ (1,0) [0|1] "" Vector__XXX
 SG_ DAS_sw038_AutofixOutOfCalibHorzn m38 : 20|1@1+ (1,0) [0|1] "" Vector__XXX
 SG_ DAS_sw038_AutofixOutOfCalibYaw m38 : 21|1@1+ (1,0) [0|1] "" Vector__XXX
 SG_ DAS_sw038_FullBlockage m38 : 22|1@1+ (1,0) [0|1] "" Vector__XXX
 SG_ DAS_sw038_TooManyResets m38 : 23|1@1+ (1,0) [0|1] "" Vector__XXX
 SG_ DAS_sw039_sdm_rcm_Mia m39 : 16|8@1+ (1,0) [0|0] "" Vector__XXX
 SG_ DAS_sw039_unusedByte m39 : 24|8@1+ (1,0) [0|0] "" Vector__XXX
 SG_ DAS_sw039_unusedW0 m39 : 32|16@1+ (1,0) [0|0] "" Vector__XXX
 SG_ DAS_sw039_unusedW1 m39 : 48|16@1+ (1,0) [0|0] "" Vector__XXX
 SG_ DAS_sw040_accel_pedal_pos m40 : 16|8@1+ (0.5,0) [0|127.5] "%" Vector__XXX
 SG_ DAS_sw040_ego_veh_speed m40 : 24|8@1+ (0.2,0) [0|51] "m/s" Vector__XXX
 SG_ DAS_sw040_das_steering_req m40 : 32|8@1+ (1,-128) [-128|127] "deg" Vector__XXX
 SG_ DAS_sw040_epas_internal_sas m40 : 40|8@1+ (1,-128) [-128|127] "deg" Vector__XXX
 SG_ DAS_sw040_torsion_bar_torque m40 : 48|8@1+ (0.1,-12.8) [-12.8|12.7] "Nm" Vector__XXX
 SG_ DAS_sw040_view_range m40 : 56|8@1+ (1,0) [0|255] "m" Vector__XXX
 SG_ DAS_sw041_rate m41 : 16|10@1- (1,0) [-512|511] "deg/s" Vector__XXX
 SG_ DAS_sw041_max_rate m41 : 26|10@1- (1,0) [-512|511] "deg/s" Vector__XXX
 SG_ DAS_sw041_ego_speed m41 : 36|10@1+ (0.05,0) [0|51.15] "m/s" Vector__XXX
 SG_ DAS_sw041_unusedW2 m41 : 46|18@1+ (1,0) [0|0] "" Vector__XXX
 SG_ DAS_sw042_health_state m42 : 16|3@1+ (1,0) [0|0] "" Vector__XXX
 SG_ DAS_sw042_abort_reason m42 : 19|5@1+ (1,0) [0|31] "" Vector__XXX
 SG_ DAS_sw042_view_range m42 : 24|8@1+ (1,0) [0|0] "" Vector__XXX
 SG_ DAS_sw042_state_before_abort m42 : 32|4@1+ (1,0) [0|15] "" Vector__XXX
 SG_ DAS_sw042_epas_error_code m42 : 36|4@1+ (1,0) [0|15] "" Vector__XXX
 SG_ DAS_sw042_cam_SunRay m42 : 40|1@1+ (1,0) [0|1] "" Vector__XXX
 SG_ DAS_sw042_cam_RoadSpray m42 : 41|1@1+ (1,0) [0|1] "" Vector__XXX
 SG_ DAS_sw042_cam_BlurredImage m42 : 42|1@1+ (1,0) [0|1] "" Vector__XXX
 SG_ DAS_sw042_cam_LowSun m42 : 43|1@1+ (1,0) [0|1] "" Vector__XXX
 SG_ DAS_sw042_cam_SmearedSpots m42 : 44|1@1+ (1,0) [0|1] "" Vector__XXX
 SG_ DAS_sw042_cam_PartialBlock m42 : 45|1@1+ (1,0) [0|1] "" Vector__XXX
 SG_ DAS_sw042_cam_Autofix m42 : 46|1@1+ (1,0) [0|1] "" Vector__XXX
 SG_ DAS_sw042_cam_AutofixHorizon m42 : 47|1@1+ (1,0) [0|1] "" Vector__XXX
 SG_ DAS_sw042_cam_AutofixYaw m42 : 48|1@1+ (1,0) [0|1] "" Vector__XXX
 SG_ DAS_sw042_cam_FullBlock m42 : 49|1@1+ (1,0) [0|1] "" Vector__XXX
 SG_ DAS_sw042_cam_SmearedHalos m42 : 50|1@1+ (1,0) [0|1] "" Vector__XXX
 SG_ DAS_sw042_cam_FoggySpots m42 : 51|1@1+ (1,0) [0|1] "" Vector__XXX
 SG_ DAS_sw042_cam_SelfGlare m42 : 52|1@1+ (1,0) [0|1] "" Vector__XXX
 SG_ DAS_sw042_cam_OutofFocus m42 : 53|1@1+ (1,0) [0|1] "" Vector__XXX
 SG_ DAS_sw042_road_match m42 : 54|1@1+ (1,0) [0|1] "" Vector__XXX
 SG_ DAS_sw042_controlled_access m42 : 55|1@1+ (1,0) [0|1] "" Vector__XXX
 SG_ DAS_sw042_road_class m42 : 56|3@1+ (1,0) [0|7] "" Vector__XXX
 SG_ DAS_sw043_mobileye_status m43 : 16|16@1+ (1,0) [0|0] "" Vector__XXX
 SG_ DAS_sw043_mesp_health_main_state m43 : 32|16@1+ (1,0) [0|0] "" Vector__XXX
 SG_ DAS_sw043_camLongRunTime_unused m43 : 48|16@1+ (1,0) [0|0] "" Vector__XXX
 SG_ DAS_sw044_countLSB m44 : 16|8@1+ (1,0) [0|0] "" Vector__XXX
 SG_ DAS_sw044_appStatus m44 : 24|4@1+ (1,0) [0|15] "" Vector__XXX
 SG_ DAS_sw044_meMainState m44 : 28|4@1+ (1,0) [0|15] "" Vector__XXX
 SG_ DAS_sw044_timestampms m44 : 32|32@1+ (1,0) [0|0] "ms" Vector__XXX
 SG_ DAS_sw045_radMia m45 : 16|8@1+ (1,0) [0|0] "" Vector__XXX
 SG_ DAS_sw045_unusedByte m45 : 24|8@1+ (1,0) [0|0] "" Vector__XXX
 SG_ DAS_sw045_unusedW0 m45 : 32|16@1+ (1,0) [0|0] "" Vector__XXX
 SG_ DAS_sw045_unusedW1 m45 : 48|16@1+ (1,0) [0|0] "" Vector__XXX
 SG_ DAS_sw046_recordId m46 : 16|16@1+ (1,0) [0|0] "" Vector__XXX
 SG_ DAS_sw046_errorCode m46 : 32|32@1+ (1,0) [0|0] "" Vector__XXX
 SG_ DAS_sw047_edrStatus m47 : 16|4@1+ (1,0) [0|0] "" Vector__XXX
 SG_ DAS_sw047_roadClass m47 : 20|3@1+ (1,0) [0|0] "" Vector__XXX
 SG_ DAS_sw047_controlledAccess m47 : 23|1@1+ (1,0) [0|0] "" Vector__XXX
 SG_ DAS_sw047_edrType m47 : 24|6@1+ (1,0) [0|0] "" Vector__XXX
 SG_ DAS_sw047_edrBlackBox m47 : 30|2@1+ (1,0) [0|0] "" Vector__XXX
 SG_ DAS_sw047_edrReturn m47 : 32|16@1+ (1,0) [0|0] "" Vector__XXX
 SG_ DAS_sw047_edrStateMachine m47 : 48|8@1+ (1,0) [0|0] "" Vector__XXX
 SG_ DAS_sw047_edrLoggerBuffer m47 : 56|2@1+ (1,0) [0|0] "" Vector__XXX
 SG_ DAS_sw047_unused m47 : 58|6@1+ (1,0) [0|0] "" Vector__XXX
 SG_ DAS_sw048_unusedW0 m48 : 16|16@1+ (1,0) [0|0] "" Vector__XXX
 SG_ DAS_sw048_unusedW1 m48 : 32|16@1+ (1,0) [0|0] "" Vector__XXX
 SG_ DAS_sw048_unusedW2 m48 : 48|16@1+ (1,0) [0|0] "" Vector__XXX
 SG_ DAS_sw049_boot_version_msw m49 : 16|16@1+ (1,0) [0|0] "" Vector__XXX
 SG_ DAS_sw049_app_version_msw m49 : 32|16@1+ (1,0) [0|0] "" Vector__XXX
 SG_ DAS_sw049_ffs_version_msw m49 : 48|16@1+ (1,0) [0|0] "" Vector__XXX
 SG_ DAS_sw050_targetDist m50 : 16|9@1+ (0.2,0) [0|102.2] "m" Vector__XXX
 SG_ DAS_sw050_targetRelSpeed m50 : 25|9@1+ (0.0625,-31) [-31|0.9375] "m/s" Vector__XXX
 SG_ DAS_sw050_targetOverlap m50 : 34|6@1+ (0.1,0) [0|6.3] "m" Vector__XXX
 SG_ DAS_sw050_hostSpeed m50 : 40|8@1+ (1,0) [0|255] "kph" Vector__XXX
 SG_ DAS_sw050_hostLongAccel m50 : 48|7@1+ (0.15625,-10) [-10|10] "m/s^2" Vector__XXX
 SG_ DAS_sw050_driverPressedAccelPed m50 : 55|1@1+ (1,0) [0|1] "" Vector__XXX
 SG_ DAS_sw050_driverPressedBrakePed m50 : 56|1@1+ (1,0) [0|1] "" Vector__XXX
 SG_ DAS_sw050_aebEnable m50 : 57|1@1+ (1,0) [0|1] "" Vector__XXX
 SG_ DAS_sw050_overrideBlinker m50 : 58|1@1+ (1,0) [0|1] "" Vector__XXX
 SG_ DAS_sw050_overrideBrake m50 : 59|1@1+ (1,0) [0|1] "" Vector__XXX
 SG_ DAS_sw050_overrideSteer m50 : 60|1@1+ (1,0) [0|1] "" Vector__XXX
 SG_ DAS_sw050_fcmModeAtEvent m50 : 61|2@1+ (1,0) [0|3] "" Vector__XXX
 SG_ DAS_sw050_accActive m50 : 63|1@1+ (1,0) [0|1] "" Vector__XXX
 SG_ DAS_sw051_a01ecuInternalPerf m51 : 16|1@1+ (1,0) [0|1] "" Vector__XXX
 SG_ DAS_sw051_a02flashPerformance m51 : 17|1@1+ (1,0) [0|1] "" Vector__XXX
 SG_ DAS_sw051_a03vBatHigh m51 : 18|1@1+ (1,0) [0|1] "" Vector__XXX
 SG_ DAS_sw051_a09configMismatch m51 : 19|1@1+ (1,0) [0|1] "" Vector__XXX
 SG_ DAS_sw051_a52radomeHtrInop m51 : 20|1@1+ (1,0) [0|1] "" Vector__XXX
 SG_ DAS_sw051_unused m51 : 21|3@1+ (1,0) [0|1] "" Vector__XXX
 SG_ DAS_sw051_SCUTemperature m51 : 24|8@1- (1,0) [-128|127] "" Vector__XXX
 SG_ DAS_sw051_HWFail m51 : 32|1@1+ (1,0) [0|1] "" Vector__XXX
 SG_ DAS_sw051_SGUFail m51 : 33|1@1+ (1,0) [0|1] "" Vector__XXX
 SG_ DAS_sw051_unusedBits m51 : 34|6@1+ (1,0) [0|1] "" Vector__XXX
 SG_ DAS_sw051_unusedB0 m51 : 40|8@1+ (1,0) [0|1] "" Vector__XXX
 SG_ DAS_sw051_unusedW1 m51 : 48|16@1+ (1,0) [0|1] "" Vector__XXX
 SG_ DAS_sw052_a07sensorBlinded m52 : 16|1@1+ (1,0) [0|1] "" Vector__XXX
 SG_ DAS_sw052_sensorDirty m52 : 17|1@1+ (1,0) [0|1] "" Vector__XXX
 SG_ DAS_sw052_HWFail m52 : 18|1@1+ (1,0) [0|1] "" Vector__XXX
 SG_ DAS_sw052_unused m52 : 19|5@1+ (1,0) [0|1] "" Vector__XXX
 SG_ DAS_sw052_unusedByte m52 : 24|8@1+ (1,0) [0|1] "" Vector__XXX
 SG_ DAS_sw052_unusedW0 m52 : 32|16@1+ (1,0) [0|1] "" Vector__XXX
 SG_ DAS_sw052_unusedW1 m52 : 48|16@1+ (1,0) [0|1] "" Vector__XXX
 SG_ DAS_sw053_a10canBusOff m53 : 16|1@1+ (1,0) [0|1] "" Vector__XXX
 SG_ DAS_sw053_a11bdyMIA m53 : 17|1@1+ (1,0) [0|1] "" Vector__XXX
 SG_ DAS_sw053_a12espMIA m53 : 18|1@1+ (1,0) [0|1] "" Vector__XXX
 SG_ DAS_sw053_a13gtwMIA m53 : 19|1@1+ (1,0) [0|1] "" Vector__XXX
 SG_ DAS_sw053_a14sccmMIA m53 : 20|1@1+ (1,0) [0|1] "" Vector__XXX
 SG_ DAS_sw053_a15adasMIA m53 : 21|1@1+ (1,0) [0|1] "" Vector__XXX
 SG_ DAS_sw053_a16bdyInvalidCount m53 : 22|1@1+ (1,0) [0|1] "" Vector__XXX
 SG_ DAS_sw053_a17adasInvalidCount m53 : 23|1@1+ (1,0) [0|1] "" Vector__XXX
 SG_ DAS_sw053_a18espInvalidCount m53 : 24|1@1+ (1,0) [0|1] "" Vector__XXX
 SG_ DAS_sw053_a19sccmInvalidCount m53 : 25|1@1+ (1,0) [0|1] "" Vector__XXX
 SG_ DAS_sw053_a20bdyInvalidChkSm m53 : 26|1@1+ (1,0) [0|1] "" Vector__XXX
 SG_ DAS_sw053_a21espInvalidChkSm m53 : 27|1@1+ (1,0) [0|1] "" Vector__XXX
 SG_ DAS_sw053_a22sccmInvalidChkSm m53 : 28|1@1+ (1,0) [0|1] "" Vector__XXX
 SG_ DAS_sw053_a23sccmInvalidChkSm m53 : 29|1@1+ (1,0) [0|1] "" Vector__XXX
 SG_ DAS_sw053_a24absValidity m53 : 30|1@1+ (1,0) [0|1] "" Vector__XXX
 SG_ DAS_sw053_a25ambTValidity m53 : 31|1@1+ (1,0) [0|1] "" Vector__XXX
 SG_ DAS_sw053_a26brakeValidity m53 : 32|1@1+ (1,0) [0|1] "" Vector__XXX
 SG_ DAS_sw053_a27CntryCdValidity m53 : 33|1@1+ (1,0) [0|1] "" Vector__XXX
 SG_ DAS_sw053_a28espValidity m53 : 34|1@1+ (1,0) [0|0] "" Vector__XXX
 SG_ DAS_sw053_a29longAccOffValidity m53 : 35|1@1+ (1,0) [0|1] "" Vector__XXX
 SG_ DAS_sw053_a30longAccValidity m53 : 36|1@1+ (1,0) [0|1] "" Vector__XXX
 SG_ DAS_sw053_a31odoValidity m53 : 37|1@1+ (1,0) [0|1] "" Vector__XXX
 SG_ DAS_sw053_a32gearValidity m53 : 38|1@1+ (1,0) [0|1] "" Vector__XXX
 SG_ DAS_sw053_a33steerAngValidity m53 : 39|1@1+ (1,0) [0|1] "" Vector__XXX
 SG_ DAS_sw053_a34steerAngSpdValidity m53 : 40|1@1+ (1,0) [0|1] "" Vector__XXX
 SG_ DAS_sw053_a35indctrValidity m53 : 41|1@1+ (1,0) [0|1] "" Vector__XXX
 SG_ DAS_sw053_a36vehStndStllValidty m53 : 42|1@1+ (1,0) [0|1] "" Vector__XXX
 SG_ DAS_sw053_a37vinValidity m53 : 43|1@1+ (1,0) [0|1] "" Vector__XXX
 SG_ DAS_sw053_a38whlRotValidity m53 : 44|1@1+ (1,0) [0|1] "" Vector__XXX
 SG_ DAS_sw053_a39whlSpdValidity m53 : 45|1@1+ (1,0) [0|1] "" Vector__XXX
 SG_ DAS_sw053_a40whlStndStllValidty m53 : 46|1@1+ (1,0) [0|1] "" Vector__XXX
 SG_ DAS_sw053_a41wiperValidity m53 : 47|1@1+ (1,0) [0|1] "" Vector__XXX
 SG_ DAS_sw053_a42xwdValidity m53 : 48|1@1+ (1,0) [0|1] "" Vector__XXX
 SG_ DAS_sw053_a43yawOffValidity m53 : 49|1@1+ (1,0) [0|1] "" Vector__XXX
 SG_ DAS_sw053_a44yawValidity m53 : 50|1@1+ (1,0) [0|1] "" Vector__XXX
 SG_ DAS_sw053_a48steerAngOffSanity m53 : 51|1@1+ (1,0) [0|1] "" Vector__XXX
 SG_ DAS_sw053_a49tireSizeSanity m53 : 52|1@1+ (1,0) [0|1] "" Vector__XXX
 SG_ DAS_sw053_a50velocitySanity m53 : 53|1@1+ (1,0) [0|1] "" Vector__XXX
 SG_ DAS_sw053_a51yawSanity m53 : 54|1@1+ (1,0) [0|1] "" Vector__XXX
 SG_ DAS_sw053_a53espmodValidity m53 : 55|1@1+ (1,0) [0|1] "" Vector__XXX
 SG_ DAS_sw053_a54gtwmodValidity m53 : 56|1@1+ (1,0) [0|1] "" Vector__XXX
 SG_ DAS_sw053_a55stwmodValidity m53 : 57|1@1+ (1,0) [0|1] "" Vector__XXX
 SG_ DAS_sw053_a56bcmodValidity m53 : 58|1@1+ (1,0) [0|1] "" Vector__XXX
 SG_ DAS_sw053_a57dimodValidity m53 : 59|1@1+ (1,0) [0|1] "" Vector__XXX
 SG_ DAS_sw053_a59drmiInvalidChkSm m53 : 60|1@1+ (1,0) [0|1] "" Vector__XXX
 SG_ DAS_sw053_a60drmiInvalidCount m53 : 61|1@1+ (1,0) [0|1] "" Vector__XXX
 SG_ DAS_sw053_a61radPositionMismatch m53 : 62|1@1+ (1,0) [0|1] "" Vector__XXX
 SG_ DAS_sw053_a62strRackMismatch m53 : 63|1@1+ (1,0) [0|1] "" Vector__XXX
 SG_ DAS_sw054_Autofix_cnvrgnceStatus m54 : 16|8@1+ (1,0) [0|0] "" Vector__XXX
 SG_ DAS_sw054_Autofix_horizon m54 : 24|8@1+ (1,0) [0|0] "" Vector__XXX
 SG_ DAS_sw054_Autofix_yaw m54 : 32|8@1+ (1,0) [0|0] "" Vector__XXX
 SG_ DAS_sw054_unusedByte m54 : 40|8@1+ (1,0) [0|0] "" Vector__XXX
 SG_ DAS_sw054_unusedW0 m54 : 48|16@1+ (1,0) [0|0] "" Vector__XXX
 SG_ DAS_sw055_detectedRadcVersion m55 : 16|32@1+ (1,0) [0|0] "" Vector__XXX
 SG_ DAS_sw055_expectedCrcLsw m55 : 48|16@1+ (1,0) [0|0] "" Vector__XXX
 SG_ DAS_sw056_diMia m56 : 16|8@1+ (1,0) [0|1] "" Vector__XXX
 SG_ DAS_sw056_unusedByte m56 : 24|8@1+ (1,0) [0|0] "" Vector__XXX
 SG_ DAS_sw056_unusedW0 m56 : 32|16@1+ (1,0) [0|0] "" Vector__XXX
 SG_ DAS_sw056_unusedW1 m56 : 48|16@1+ (1,0) [0|0] "" Vector__XXX
 SG_ DAS_sw057_chCtrlMia m57 : 16|1@1+ (1,0) [0|1] "" Vector__XXX
 SG_ DAS_sw057_dasMapDataMia m57 : 17|1@1+ (1,0) [0|1] "" Vector__XXX
 SG_ DAS_sw057_locStatusMia m57 : 18|1@1+ (1,0) [0|1] "" Vector__XXX
 SG_ DAS_sw057_gpsVehSpeedMia m57 : 19|1@1+ (1,0) [0|1] "" Vector__XXX
 SG_ DAS_sw057_dasRoadSignMia m57 : 20|1@1+ (1,0) [0|1] "" Vector__XXX
 SG_ DAS_sw057_radarMapDataMia m57 : 21|1@1+ (1,0) [0|1] "" Vector__XXX
 SG_ DAS_sw057_csaRoadCurvMia m57 : 22|1@1+ (1,0) [0|1] "" Vector__XXX
 SG_ DAS_sw057_csaOfframpCurvMia m57 : 23|1@1+ (1,0) [0|1] "" Vector__XXX
 SG_ DAS_sw057_unusedByte m57 : 24|8@1+ (1,0) [0|0] "" Vector__XXX
 SG_ DAS_sw057_unusedW0 m57 : 32|16@1+ (1,0) [0|0] "" Vector__XXX
 SG_ DAS_sw057_unusedW1 m57 : 48|16@1+ (1,0) [0|0] "" Vector__XXX
 SG_ DAS_sw058_epbMia m58 : 16|8@1+ (1,0) [0|1] "" Vector__XXX
 SG_ DAS_sw058_unusedByte m58 : 24|8@1+ (1,0) [0|0] "" Vector__XXX
 SG_ DAS_sw058_unusedW0 m58 : 32|16@1+ (1,0) [0|0] "" Vector__XXX
 SG_ DAS_sw058_unusedW1 m58 : 48|16@1+ (1,0) [0|0] "" Vector__XXX
 SG_ DAS_sw059_parkMia m59 : 16|8@1+ (1,0) [0|1] "" Vector__XXX
 SG_ DAS_sw059_unusedByte m59 : 24|8@1+ (1,0) [0|0] "" Vector__XXX
 SG_ DAS_sw059_unusedW0 m59 : 32|16@1+ (1,0) [0|0] "" Vector__XXX
 SG_ DAS_sw059_unusedW1 m59 : 48|16@1+ (1,0) [0|0] "" Vector__XXX
 SG_ DAS_sw060_targetDist m60 : 16|9@1+ (0.2,0) [0|102.2] "m" Vector__XXX
 SG_ DAS_sw060_targetRelSpeed m60 : 25|9@1+ (0.0625,-31) [-31|0.9375] "m/s" Vector__XXX
 SG_ DAS_sw060_targetOverlap m60 : 34|6@1+ (0.1,0) [0|6.3] "m" Vector__XXX
 SG_ DAS_sw060_hostSpeed m60 : 40|7@1+ (2,0) [0|254] "kph" Vector__XXX
 SG_ DAS_sw060_hostLongAccel m60 : 47|4@1+ (1,-7.5) [-7.5|7.5] "m/s^2" Vector__XXX
 SG_ DAS_sw060_RadarAssociationAge m60 : 51|4@1+ (100,0) [0|1500] "ms" Vector__XXX
 SG_ DAS_sw060_driverPressedBrakePed m60 : 55|1@1+ (1,0) [0|1] "" Vector__XXX
 SG_ DAS_sw060_overrideAccelPed m60 : 56|1@1+ (1,0) [0|1] "" Vector__XXX
 SG_ DAS_sw060_overrideBlinker m60 : 57|1@1+ (1,0) [0|1] "" Vector__XXX
 SG_ DAS_sw060_overrideBrake m60 : 58|1@1+ (1,0) [0|1] "" Vector__XXX
 SG_ DAS_sw060_overrideSteer m60 : 59|1@1+ (1,0) [0|1] "" Vector__XXX
 SG_ DAS_sw060_collisionWarningSource m60 : 60|3@1+ (1,0) [0|7] "" Vector__XXX
 SG_ DAS_sw060_accActive m60 : 63|1@1+ (1,0) [0|1] "" Vector__XXX
 SG_ DAS_sw061_airSuspensionMia m61 : 16|8@1+ (1,0) [0|1] "" Vector__XXX
 SG_ DAS_sw061_unusedByte m61 : 24|8@1+ (1,0) [0|0] "" Vector__XXX
 SG_ DAS_sw061_unusedW0 m61 : 32|16@1+ (1,0) [0|0] "" Vector__XXX
 SG_ DAS_sw061_unusedW1 m61 : 48|16@1+ (1,0) [0|0] "" Vector__XXX
 SG_ DAS_sw062_HorizontalMisalignment m62 : 16|16@1+ (0.00137332,-45) [-45|45.0005262] "deg" Vector__XXX
 SG_ DAS_sw062_VerticalMisalignment m62 : 32|10@1+ (0.087977,-45) [-45|45.000471] "deg" Vector__XXX
 SG_ DAS_sw062_unusedBits m62 : 42|6@1+ (1,0) [0|1] "" Vector__XXX
 SG_ DAS_sw062_VmaPlausibility m62 : 48|16@1+ (1.52587890625005E-005,0) [0|0.99998474121097] "" Vector__XXX
 SG_ DAS_sw063_expectedMajorVer m63 : 16|8@1+ (1,0) [0|255] "" Vector__XXX
 SG_ DAS_sw063_detectedMajorVer m63 : 24|8@1+ (1,0) [0|255] "" Vector__XXX
 SG_ DAS_sw063_expectedMinorVer m63 : 32|8@1+ (1,0) [0|255] "" Vector__XXX
 SG_ DAS_sw063_detectedMinorVer m63 : 40|8@1+ (1,0) [0|255] "" Vector__XXX
 SG_ DAS_sw063_expectedSubMinorVer m63 : 48|8@1+ (1,0) [0|255] "" Vector__XXX
 SG_ DAS_sw063_detectedSubMinorVer m63 : 56|8@1+ (1,0) [0|255] "" Vector__XXX
 SG_ DAS_sw064_epasMia m64 : 16|8@1+ (1,0) [0|1] "" Vector__XXX
 SG_ DAS_sw064_unusedByte m64 : 24|8@1+ (1,0) [0|0] "" Vector__XXX
 SG_ DAS_sw064_unusedW0 m64 : 32|16@1+ (1,0) [0|0] "" Vector__XXX
 SG_ DAS_sw064_unusedW1 m64 : 48|16@1+ (1,0) [0|0] "" Vector__XXX
 SG_ DAS_sw065_app_mobileye_status m65 : 16|8@1+ (1,0) [0|21] "" Vector__XXX
 SG_ DAS_sw065_mobileye_main_state m65 : 24|8@1+ (1,0) [0|255] "" Vector__XXX
 SG_ DAS_sw065_unusedW0 m65 : 32|16@1+ (1,0) [0|0] "" Vector__XXX
 SG_ DAS_sw065_unusedW1 m65 : 48|16@1+ (1,0) [0|0] "" Vector__XXX
 SG_ DAS_sw066_app_mobileye_status m66 : 16|8@1+ (1,0) [0|21] "" Vector__XXX
 SG_ DAS_sw066_mobileye_main_state m66 : 24|8@1+ (1,0) [0|255] "" Vector__XXX
 SG_ DAS_sw066_unusedW0 m66 : 32|16@1+ (1,0) [0|0] "" Vector__XXX
 SG_ DAS_sw066_unusedW1 m66 : 48|16@1+ (1,0) [0|0] "" Vector__XXX
 SG_ DAS_sw067_sccmSTW m67 : 16|14@1+ (0.1,-819.2) [-819.2|819] "deg" Vector__XXX
 SG_ DAS_sw067_epasSTW m67 : 30|14@1+ (0.1,-819.2) [-819.2|819] "deg" Vector__XXX
 SG_ DAS_sw067_vehSpeed m67 : 44|12@1+ (0.1,-50) [-50|359.6] "kph" Vector__XXX
 SG_ DAS_sw067_offsetEstimator m67 : 56|8@1+ (0.1,-12.8) [-12.8|12.8] "deg" Vector__XXX
 SG_ DAS_sw068_percentConsistency m68 : 16|10@1+ (0.1,0) [0|100] "%" Vector__XXX
 SG_ DAS_sw068_virtualLaneSTW m68 : 32|14@1+ (0.1,-819.2) [-819.2|819.2] "deg" Vector__XXX
 SG_ DAS_sw068_navigationSTW m68 : 48|14@1+ (0.1,-819.2) [-819.2|819.2] "deg" Vector__XXX
 SG_ DAS_sw069_epasMia m69 : 16|1@1+ (1,0) [0|1] "" Vector__XXX
 SG_ DAS_sw069_espMia m69 : 17|1@1+ (1,0) [0|1] "" Vector__XXX
 SG_ DAS_sw069_parkMia m69 : 18|1@1+ (1,0) [0|1] "" Vector__XXX
 SG_ DAS_sw069_sccmMia m69 : 19|1@1+ (1,0) [0|1] "" Vector__XXX
 SG_ DAS_sw069_parkMismatch m69 : 20|1@1+ (1,0) [0|1] "" Vector__XXX
 SG_ DAS_sw069_eacStatus m69 : 21|4@1+ (1,0) [0|1] "" Vector__XXX
 SG_ DAS_sw069_diAPState m69 : 25|4@1+ (1,0) [0|1] "" Vector__XXX
 SG_ DAS_sw069_parkCal m69 : 29|1@1+ (1,0) [0|1] "" Vector__XXX
 SG_ DAS_sw069_torsionBar m69 : 32|12@1+ (0.01,-20.5) [-20.5|20.45] "Nm" Vector__XXX
 SG_ DAS_sw069_roadClass m69 : 44|4@1+ (1,0) [0|15] "" Vector__XXX
 SG_ DAS_sw069_drivingLaneLeft m69 : 48|8@1+ (1,0) [0|255] "" Vector__XXX
 SG_ DAS_sw069_drivingLaneRight m69 : 56|8@1+ (1,0) [0|255] "" Vector__XXX
 SG_ DAS_sw070_currTireFitment m70 : 16|3@1+ (1,0) [0|7] "" Vector__XXX
 SG_ DAS_sw070_lastTireFitment m70 : 19|3@1+ (1,0) [0|7] "" Vector__XXX
 SG_ DAS_sw070_diGear m70 : 22|3@1+ (1,0) [0|7] "" Vector__XXX
 SG_ DAS_sw070_driveRail m70 : 25|1@1+ (1,0) [0|1] "" Vector__XXX
 SG_ DAS_sw070_accRail m70 : 26|1@1+ (1,0) [0|1] "" Vector__XXX
 SG_ DAS_sw070_temperature m70 : 32|8@1+ (0.5,-40) [-40|87.5] "C" Vector__XXX
 SG_ DAS_sw070_currentSpeed m70 : 40|12@1+ (0.1,-204.7) [-204.7|204.8] "mph" Vector__XXX
 SG_ DAS_sw071_selfParkType m71 : 16|4@1+ (1,0) [0|15] "" Vector__XXX
 SG_ DAS_sw071_endPosX m71 : 20|10@1+ (0.05,-25.6) [-25.6|25.5] "m" Vector__XXX
 SG_ DAS_sw071_endPosY m71 : 30|10@1+ (0.05,-25.6) [-25.6|25.5] "m" Vector__XXX
 SG_ DAS_sw071_roadClass m71 : 40|3@1+ (1,0) [0|7] "" Vector__XXX
 SG_ DAS_sw071_driverPresent m71 : 43|1@1+ (1,0) [0|1] "" Vector__XXX
 SG_ DAS_sw071_airSuspension m71 : 44|3@1+ (1,0) [0|7] "" Vector__XXX
 SG_ DAS_sw071_temperature m71 : 47|8@1+ (0.5,-40) [-40|87.5] "C" Vector__XXX
 SG_ DAS_sw071_activationType m71 : 55|2@1+ (1,0) [0|3] "" Vector__XXX
 SG_ DAS_sw072_vehicleX m72 : 16|10@1+ (0.05,-25.6) [-25.6|25.5] "m" Vector__XXX
 SG_ DAS_sw072_vehicleY m72 : 26|10@1+ (0.05,-25.6) [-25.6|25.5] "m" Vector__XXX
 SG_ DAS_sw072_vehicleHeading m72 : 36|10@1+ (0.005,-2.56) [-2.56|2.55] "rad" Vector__XXX
 SG_ DAS_sw072_endDistance m72 : 46|8@1+ (1,0) [0|255] "cm" Vector__XXX
 SG_ DAS_sw072_guidanceComplete m72 : 54|1@1+ (1,0) [0|1] "" Vector__XXX
 SG_ DAS_sw072_guidanceRunaway m72 : 55|1@1+ (1,0) [0|1] "" Vector__XXX
 SG_ DAS_sw072_guidanceTimer m72 : 56|1@1+ (1,0) [0|1] "" Vector__XXX
 SG_ DAS_sw072_handlePress m72 : 57|1@1+ (1,0) [0|1] "" Vector__XXX
 SG_ DAS_sw072_keyfobPress m72 : 58|1@1+ (1,0) [0|1] "" Vector__XXX
 SG_ DAS_sw072_garageOpened m72 : 59|1@1+ (1,0) [0|1] "" Vector__XXX
 SG_ DAS_sw072_userTimeout m72 : 60|1@1+ (1,0) [0|1] "" Vector__XXX
 SG_ DAS_sw073_escalateLDWs m73 : 16|1@1+ (1,0) [0|1] "" Vector__XXX
 SG_ DAS_sw073_silentEscalatedLDW m73 : 17|1@1+ (1,0) [0|1] "" Vector__XXX
 SG_ DAS_sw073_escalateLDWreason m73 : 18|2@1+ (1,0) [0|3] "" Vector__XXX
 SG_ DAS_sw073_rawMobileyeLDW m73 : 20|2@1+ (1,0) [0|3] "" Vector__XXX
 SG_ DAS_sw073_freespaceLDW m73 : 22|2@1+ (1,0) [0|3] "" Vector__XXX
 SG_ DAS_sw073_freespaceLeftC0 m73 : 24|8@1+ (0.1,-12.8) [-12.8|12.7] "m" Vector__XXX
 SG_ DAS_sw073_freespaceRightC0 m73 : 32|8@1+ (0.1,-12.8) [-12.8|12.7] "m" Vector__XXX
 SG_ DAS_sw073_freespaceLeftC1 m73 : 40|8@1+ (0.0016,-0.2) [-0.2|0.2] "rad" Vector__XXX
 SG_ DAS_sw073_freespaceRightC1 m73 : 48|8@1+ (0.0016,-0.2) [-0.2|0.2] "rad" Vector__XXX
 SG_ DAS_sw073_freespaceLeftFarZ m73 : 56|4@1+ (4,0) [0|60] "m" Vector__XXX
 SG_ DAS_sw073_freespaceRightFarZ m73 : 60|4@1+ (4,0) [0|60] "m" Vector__XXX
 SG_ DAS_sw074_ipsoDx m74 : 16|6@1+ (2,0) [0|126] "m" Vector__XXX
 SG_ DAS_sw074_ipsoDy m74 : 22|6@1+ (0.1,-3.2) [-3.2|3.1] "m" Vector__XXX
 SG_ DAS_sw074_ipsoDz m74 : 28|6@1+ (0.2,-6.4) [-6.4|6.2] "m" Vector__XXX
 SG_ DAS_sw074_ipsoRCS m74 : 34|8@1+ (1,0) [0|255] "db" Vector__XXX
 SG_ DAS_sw074_ipsoConfidence m74 : 42|6@1+ (2,0) [0|126] "percent" Vector__XXX
 SG_ DAS_sw074_ipsowExist m74 : 48|5@1+ (1,0) [0|31] "" Vector__XXX
 SG_ DAS_sw074_roadClass m74 : 54|3@1+ (1,0) [0|7] "" Vector__XXX
 SG_ DAS_sw074_cruiseActive m74 : 57|1@1+ (1,0) [0|1] "" Vector__XXX
 SG_ DAS_sw074_autopilotActive m74 : 58|1@1+ (1,0) [0|1] "" Vector__XXX
 SG_ DAS_sw075_scMia m75 : 16|8@1+ (1,0) [0|255] "" Vector__XXX
 SG_ DAS_sw075_unusedByte m75 : 24|8@1+ (1,0) [0|0] "" Vector__XXX
 SG_ DAS_sw075_unusedW0 m75 : 32|16@1+ (1,0) [0|0] "" Vector__XXX
 SG_ DAS_sw075_unusedW1 m75 : 48|16@1+ (1,0) [0|0] "" Vector__XXX
 SG_ DAS_sw076_targetDist m76 : 16|9@1+ (0.2,0) [0|102.2] "m" Vector__XXX
 SG_ DAS_sw076_targetRelSpeed m76 : 25|9@1+ (0.0625,-31) [-31|0.9375] "m/s" Vector__XXX
 SG_ DAS_sw076_targetOverlap m76 : 34|6@1+ (0.1,0) [0|6.3] "m" Vector__XXX
 SG_ DAS_sw076_hostSpeed m76 : 40|8@1+ (1,0) [0|255] "kph" Vector__XXX
 SG_ DAS_sw076_hostLongAccel m76 : 48|7@1+ (0.15625,-10) [-10|10] "m/s^2" Vector__XXX
 SG_ DAS_sw076_driverPressedAccelPed m76 : 55|1@1+ (1,0) [0|1] "" Vector__XXX
 SG_ DAS_sw076_driverPressedBrakePed m76 : 56|1@1+ (1,0) [0|1] "" Vector__XXX
 SG_ DAS_sw076_overrideAccelPed m76 : 57|1@1+ (1,0) [0|1] "" Vector__XXX
 SG_ DAS_sw076_overrideBlinker m76 : 58|1@1+ (1,0) [0|1] "" Vector__XXX
 SG_ DAS_sw076_overrideBrake m76 : 59|1@1+ (1,0) [0|1] "" Vector__XXX
 SG_ DAS_sw076_overrideSteer m76 : 60|1@1+ (1,0) [0|1] "" Vector__XXX
 SG_ DAS_sw076_fcmModeAtEvent m76 : 61|2@1+ (1,0) [0|3] "" Vector__XXX
 SG_ DAS_sw076_accActive m76 : 63|1@1+ (1,0) [0|1] "" Vector__XXX
 SG_ DAS_sw077_oocDistance m77 : 16|9@1+ (1,0) [0|512] "cm" Vector__XXX
 SG_ DAS_sw077_oocConfidence m77 : 25|7@1+ (1,0) [0|100] "%" Vector__XXX
 SG_ DAS_sw077_oocCollisionSide m77 : 32|3@1+ (1,0) [0|7] "" Vector__XXX
 SG_ DAS_sw077_oocHeight m77 : 35|2@1+ (1,0) [0|4] "" Vector__XXX
 SG_ DAS_sw077_vehicleSpeed m77 : 37|10@1+ (0.05,-25) [-25|26.15] "MPH" Vector__XXX
 SG_ DAS_sw077_oocUntrackedTime m77 : 48|6@1+ (0.1,0) [0|6.3] "s" Vector__XXX
 SG_ DAS_sw077_oocOffCourseDist_cm m77 : 54|10@1- (1,0) [-512|511] "" Vector__XXX
 SG_ DAS_sw078_camCipv_dx m78 : 16|8@1+ (0.2,0) [0|51] "m" Vector__XXX
 SG_ DAS_sw078_ttc m78 : 24|8@1+ (0.02,0) [0|5.11] "seconds" Vector__XXX
 SG_ DAS_sw078_radarTarg5_dx m78 : 32|8@1+ (0.0625,0) [0|15.9375] "m" Vector__XXX
 SG_ DAS_sw078_radarTarg5_VxRel m78 : 40|8@1+ (0.2,-25.6) [-25.6|25.4] "m/s" Vector__XXX
 SG_ DAS_sw078_radarTarg1_dx m78 : 48|8@1+ (0.0625,0) [0|15.9375] "m" Vector__XXX
 SG_ DAS_sw078_radarTarg1_VxRel m78 : 56|8@1+ (0.2,-25.6) [-25.6|25.4] "m/s" Vector__XXX
 SG_ DAS_sw080_sensors_healty_check m80 : 16|1@1+ (1,0) [0|1] "" Vector__XXX
 SG_ DAS_sw080_dist_travelled_check m80 : 17|1@1+ (1,0) [0|1] "" Vector__XXX
 SG_ DAS_sw080_road_class_check m80 : 18|1@1+ (1,0) [0|1] "" Vector__XXX
 SG_ DAS_sw080_stw_angle_check m80 : 19|1@1+ (1,0) [0|1] "" Vector__XXX
 SG_ DAS_sw080_rad_tar_5_check m80 : 20|1@1+ (1,0) [0|1] "" Vector__XXX
 SG_ DAS_sw080_ultrasonic_obs_check m80 : 21|1@1+ (1,0) [0|1] "" Vector__XXX
 SG_ DAS_sw080_freespace_check m80 : 22|1@1+ (1,0) [0|1] "" Vector__XXX
 SG_ DAS_sw080_pedestrian_check m80 : 23|1@1+ (1,0) [0|1] "" Vector__XXX
 SG_ DAS_sw080_rad_tar_5_dist m80 : 24|6@1+ (1,0) [0|63] "m" Vector__XXX
 SG_ DAS_sw080_stw_angle_deg m80 : 32|8@1+ (1,0) [0|255] "deg" Vector__XXX
 SG_ DAS_sw080_road_class m80 : 40|3@1+ (1,0) [0|7] "" Vector__XXX
 SG_ DAS_sw080_ego_speed m80 : 43|5@1+ (1,0) [0|31] "mph" Vector__XXX
 SG_ DAS_sw080_cipv_valid m80 : 48|1@1+ (1,0) [0|1] "" Vector__XXX
 SG_ DAS_sw080_min_speed_check m80 : 49|1@1+ (1,0) [0|1] "" Vector__XXX
 SG_ DAS_sw080_cruise_lever_state m80 : 50|3@1+ (1,0) [0|7] "" Vector__XXX
 SG_ DAS_sw080_cruise_speed_check m80 : 53|1@1+ (1,0) [0|1] "" Vector__XXX
 SG_ DAS_sw081_radarDistance m81 : 16|8@1+ (0.0625,0) [0|15.9375] "m" Vector__XXX
 SG_ DAS_sw081_radarTTC m81 : 24|8@1+ (0.02,0) [0|5.11] "seconds" Vector__XXX
 SG_ DAS_sw081_cameraDistance m81 : 32|8@1+ (0.0625,0) [0|15.9375] "m" Vector__XXX
 SG_ DAS_sw081_cameraTTC m81 : 40|8@1+ (0.02,0) [0|5.11] "seconds" Vector__XXX
 SG_ DAS_sw081_pedalPosition m81 : 48|7@1+ (1,0) [0|127] "%" Vector__XXX
 SG_ DAS_sw082_L_VL m82 : 16|8@1+ (0.05,-6.4) [-6.4|6.35] "m" Vector__XXX
 SG_ DAS_sw082_R_VL m82 : 24|8@1+ (0.05,-6.4) [-6.4|6.35] "m" Vector__XXX
 SG_ DAS_sw082_L_Lane m82 : 32|8@1+ (0.05,-6.4) [-6.4|6.35] "m" Vector__XXX
 SG_ DAS_sw082_R_Lane m82 : 40|8@1+ (0.05,-6.4) [-6.4|6.35] "m" Vector__XXX
 SG_ DAS_sw082_road_class m82 : 48|3@1+ (1,0) [0|7] "" Vector__XXX
 SG_ DAS_sw083_Targ5_RCS m83 : 16|16@1+ (0.0039063096,0) [0|256] "dB" Vector__XXX
 SG_ DAS_sw083_Targ5_dx m83 : 32|12@1+ (0.0625,0) [0|255.9375] "m" Vector__XXX
 SG_ DAS_sw083_Targ5_dz m83 : 44|6@1+ (0.25,-5) [-5|10.75] "m" Vector__XXX
 SG_ DAS_sw083_Targ5_wObj m83 : 50|5@1+ (0.03125,0) [0|0.96875] "%" Vector__XXX
 SG_ DAS_sw083_Targ5_wNonObj m83 : 55|5@1+ (0.03125,0) [0|0.96875] "%" Vector__XXX
 SG_ DAS_sw084_ipsoTTC m84 : 16|8@1+ (0.02,0) [0|5.11] "seconds" Vector__XXX
 SG_ DAS_sw084_ipsoRCS m84 : 24|8@1+ (1,0) [0|255] "db" Vector__XXX
 SG_ DAS_sw084_ipsoConfidence m84 : 36|6@1+ (2,0) [0|126] "percent" Vector__XXX
 SG_ DAS_sw084_ipsoWObstacle m84 : 42|5@1+ (0.03125,0) [0|0.96875] "1" Vector__XXX
 SG_ DAS_sw085_radarDistance m85 : 16|8@1+ (0.0625,0) [0|15.9375] "m" Vector__XXX
 SG_ DAS_sw085_radarTTC m85 : 24|8@1+ (0.02,0) [0|5.11] "seconds" Vector__XXX
 SG_ DAS_sw085_roadClass m85 : 32|3@1+ (1,0) [0|7] "" Vector__XXX
 SG_ DAS_sw085_leftLaneExist m85 : 36|6@1+ (2,0) [0|128] "%" Vector__XXX
 SG_ DAS_sw085_rightLaneExist m85 : 42|6@1+ (2,0) [0|128] "%" Vector__XXX
 SG_ DAS_sw085_averageSpeedHist m85 : 48|6@1+ (0.25,0) [0|16] "mps" Vector__XXX
 SG_ DAS_sw085_freeSpaceC0Left m85 : 54|5@1+ (1,-15) [-15|16] "m" Vector__XXX
 SG_ DAS_sw085_freeSpaceC0Right m85 : 59|5@1+ (1,-15) [-15|16] "m" Vector__XXX
 SG_ DAS_sw086_distanceException m86 : 16|8@1+ (1,-90) [90|165] "m" Vector__XXX
 SG_ DAS_sw086_distanceEllipse m86 : 24|8@1+ (0.5,0) [0|127.5] "m" Vector__XXX
 SG_ DAS_sw086_ellipseWidth m86 : 32|8@1+ (0.1,0) [0|25.5] "m" Vector__XXX
 SG_ DAS_sw086_ellipseOverlap m86 : 40|8@1+ (0.1,-12.5) [-12.5|12.5] "m" Vector__XXX
 SG_ DAS_sw086_ellipseAge m86 : 48|3@1+ (1,0) [0|7] "" Vector__XXX
 SG_ DAS_sw086_activeBraking m86 : 51|1@1+ (1,0) [0|1] "" Vector__XXX
 SG_ DAS_sw086_cipvValid m86 : 52|1@1+ (1,0) [0|1] "" Vector__XXX
 SG_ DAS_sw086_mcvlValid m86 : 53|1@1+ (1,0) [0|1] "" Vector__XXX
 SG_ DAS_sw086_mcvrValid m86 : 54|1@1+ (1,0) [0|1] "" Vector__XXX
 SG_ DAS_sw086_roadClass m86 : 55|3@1+ (1,0) [0|7] "" Vector__XXX
 SG_ DAS_sw086_ipsoApproved m86 : 58|1@1+ (1,0) [0|1] "" Vector__XXX
 SG_ DAS_sw086_controlledAccess m86 : 59|1@1+ (1,0) [0|1] "" Vector__XXX
 SG_ DAS_sw086_driverHandsOn m86 : 60|1@1+ (1,0) [0|1] "" Vector__XXX
 SG_ DAS_sw103_objectDx m103 : 16|8@1+ (0.5,0) [0|127.5] "m" Vector__XXX
 SG_ DAS_sw103_objectRCS m103 : 24|8@1+ (1,0) [0|255] "" Vector__XXX
 SG_ DAS_sw103_objectDy m103 : 32|8@1+ (0.5,-15.5) [-15.5|16] "m" Vector__XXX
 SG_ DAS_sw103_objectDz m103 : 40|8@1+ (0.25,-5) [-5|10.75] "m" Vector__XXX
 SG_ DAS_sw103_distanceEllipse m103 : 48|8@1+ (0.5,0) [0|127.5] "m" Vector__XXX
 SG_ DAS_sw103_ipsoApproved m103 : 56|1@1+ (1,0) [0|1] "" Vector__XXX
 SG_ DAS_sw103_constArea m103 : 57|2@1+ (1,0) [0|3] "" Vector__XXX
 SG_ DAS_sw103_radAlignment m103 : 59|5@1+ (0.015625,-0.2343) [-0.2343|0.25] "rad" Vector__XXX
 SG_ DAS_sw106_torsionBarOffset m106 : 16|8@1+ (0.005,-0.64) [-0.64|0.63] "Nm" Vector__XXX
 SG_ DAS_sw193_outOfFocusImage m193 : 16|1@1+ (1,0) [0|1] "" Vector__XXX
 SG_ DAS_sw193_impairedVD m193 : 17|1@1+ (1,0) [0|1] "" Vector__XXX
 SG_ DAS_sw193_blurredImage m193 : 18|1@1+ (1,0) [0|1] "" Vector__XXX
 SG_ DAS_sw193_smearedSpots m193 : 19|1@1+ (1,0) [0|1] "" Vector__XXX
 SG_ DAS_sw193_partialBlockage m193 : 20|1@1+ (1,0) [0|1] "" Vector__XXX
 SG_ DAS_sw193_fullBlockage m193 : 21|1@1+ (1,0) [0|1] "" Vector__XXX
 SG_ DAS_sw193_smearedHalos m193 : 22|1@1+ (1,0) [0|1] "" Vector__XXX
 SG_ DAS_sw194_numObstacles m194 : 16|4@1+ (1,0) [0|7] "" Vector__XXX
 SG_ DAS_sw194_numPedstrian m194 : 20|4@1+ (1,0) [0|7] "" Vector__XXX
 SG_ DAS_sw194_timeInHold m194 : 31|16@0+ (1,0) [0|1] "" Vector__XXX
 SG_ DAS_sw194_leadDx m194 : 40|8@1+ (0.1,0) [0|25] "m" Vector__XXX
 SG_ DAS_sw194_leadVx m194 : 48|6@1- (0.2,0) [-6|6] "m/s" Vector__XXX
 SG_ DAS_sw194_leadAx m194 : 54|6@1- (0.2,0) [-6|6] "m/s^2" Vector__XXX
 SG_ DAS_sw194_reasonForHold m194 : 60|4@1+ (1,0) [0|15] "" Vector__XXX
 SG_ DAS_sw195_sdiSystemStatus m195 : 16|1@1+ (1,0) [0|1] "" Vector__XXX
 SG_ DAS_sw195_sdiSystemNoise m195 : 17|2@1+ (1,0) [0|3] "" Vector__XXX
 SG_ DAS_sw195_sdiFrontCC m195 : 24|5@1+ (1,0) [0|31] "" Vector__XXX
 SG_ DAS_sw195_s1Blocked m195 : 29|1@1+ (1,0) [0|1] "" Vector__XXX
 SG_ DAS_sw195_s6Blocked m195 : 30|1@1+ (1,0) [0|1] "" Vector__XXX
 SG_ DAS_sw195_s7Blocked m195 : 31|1@1+ (1,0) [0|1] "" Vector__XXX
 SG_ DAS_sw195_sdiRearCC m195 : 32|5@1+ (1,0) [0|31] "" Vector__XXX
 SG_ DAS_sw195_s11Blocked m195 : 37|1@1+ (1,0) [0|1] "" Vector__XXX
 SG_ DAS_sw195_s12Blocked m195 : 38|1@1+ (1,0) [0|1] "" Vector__XXX
 SG_ DAS_sw195_s8Blocked m195 : 39|1@1+ (1,0) [0|1] "" Vector__XXX
 SG_ DAS_sw195_vehicleSpeed m195 : 40|12@1+ (0.1,0) [0|409.6] "kph" Vector__XXX
 SG_ DAS_sw198_tsrMsgInvalid m198 : 16|1@1+ (1,0) [0|1] "" Vector__XXX
 SG_ DAS_sw198_tflMsgInvalid m198 : 17|1@1+ (1,0) [0|1] "" Vector__XXX
 SG_ DAS_sw198_partialBlockage m198 : 18|1@1+ (1,0) [0|1] "" Vector__XXX
 SG_ DAS_sw198_fullBlockage m198 : 19|1@1+ (1,0) [0|1] "" Vector__XXX
 SG_ DAS_sw199_numShifts m199 : 16|4@1+ (1,0) [0|15] "" Vector__XXX
 SG_ DAS_sw199_internalState m199 : 20|4@1+ (1,0) [0|15] "" Vector__XXX
 SG_ DAS_sw199_abortCodePARK m199 : 24|5@1+ (1,0) [0|15] "" Vector__XXX
 SG_ DAS_sw199_currentSTW m199 : 29|14@1+ (0.1,-819.2) [-819.2|819] "deg" Vector__XXX
 SG_ DAS_sw199_abortCodeDAS m199 : 43|5@1+ (1,0) [0|31] "" Vector__XXX
 SG_ DAS_sw199_maxSpeed m199 : 48|8@1+ (0.1,-12.2) [-12.2|12.2] "mph" Vector__XXX
 SG_ DAS_sw199_currentSpeed m199 : 56|8@1+ (0.1,-12.2) [-12.2|12.2] "mph" Vector__XXX
 SG_ DAS_sw200_startSpeed m200 : 16|10@1+ (0.1,-50) [-10|92.3] "m/s" Vector__XXX
 SG_ DAS_sw200_endSpeed m200 : 26|10@1+ (0.1,-50) [-10|92.3] "m/s" Vector__XXX
 SG_ DAS_sw200_epasHandsOnDetected m200 : 36|1@1+ (1,0) [0|1] "" Vector__XXX
 SG_ DAS_sw200_autopilotRestricted m200 : 37|1@1+ (1,0) [0|1] "" Vector__XXX
 SG_ DAS_sw200_autopilotIntState m200 : 40|4@1+ (1,0) [0|1] "" Vector__XXX
 SG_ DAS_sw201_timeHorizon m201 : 16|8@1+ (0.1,0) [0|25.5] "s" Vector__XXX
 SG_ DAS_sw201_vehSpeed m201 : 24|8@1+ (1,0) [0|255] "kph" Vector__XXX
 SG_ DAS_sw201_stwAngleReq m201 : 32|8@1- (1,0) [-128|127] "deg" Vector__XXX
 SG_ DAS_sw201_viewRangeOAL m201 : 43|3@1+ (1,0) [0|5] "" Vector__XXX
 SG_ DAS_sw201_steeringErrorOAL m201 : 55|3@1+ (1,0) [0|5] "" Vector__XXX
 SG_ DAS_sw201_virtualLaneInputOAL m201 : 61|3@1+ (1,0) [0|5] "" Vector__XXX
 SG_ DAS_sw202_sdiSystemStatus m202 : 16|1@1+ (1,0) [0|1] "" Vector__XXX
 SG_ DAS_sw202_sdiSystemNoise m202 : 17|2@1+ (1,0) [0|3] "" Vector__XXX
 SG_ DAS_sw202_sdiFrontCC m202 : 24|5@1+ (1,0) [0|31] "" Vector__XXX
 SG_ DAS_sw202_s1Blocked m202 : 29|1@1+ (1,0) [0|1] "" Vector__XXX
 SG_ DAS_sw202_s6Blocked m202 : 30|1@1+ (1,0) [0|1] "" Vector__XXX
 SG_ DAS_sw202_s7Blocked m202 : 31|1@1+ (1,0) [0|1] "" Vector__XXX
 SG_ DAS_sw202_sdiRearCC m202 : 32|5@1+ (1,0) [0|31] "" Vector__XXX
 SG_ DAS_sw202_s8Blocked m202 : 37|1@1+ (1,0) [0|1] "" Vector__XXX
 SG_ DAS_sw202_s11Blocked m202 : 38|1@1+ (1,0) [0|1] "" Vector__XXX
 SG_ DAS_sw202_s12Blocked m202 : 39|1@1+ (1,0) [0|1] "" Vector__XXX
 SG_ DAS_sw202_vehicleSpeed m202 : 40|12@1+ (0.1,0) [0|409.6] "kph" Vector__XXX
 SG_ DAS_sw203_slotSizeX m203 : 16|8@1+ (4,0) [0|1020] "cm" Vector__XXX
 SG_ DAS_sw203_slotSizeY m203 : 24|8@1+ (4,0) [0|1020] "cm" Vector__XXX
 SG_ DAS_sw203_startDistance m203 : 32|11@1+ (1,0) [0|2047] "cm" Vector__XXX
 SG_ DAS_sw203_roadClass m203 : 43|3@1+ (1,0) [0|7] "" Vector__XXX
 SG_ DAS_sw203_curbType m203 : 46|2@1+ (1,0) [0|3] "" Vector__XXX
 SG_ DAS_sw203_controlType m203 : 48|4@1+ (1,0) [0|15] "" Vector__XXX
 SG_ DAS_sw203_vehicleSkew m203 : 52|12@1+ (0.002,0) [0|8.19] "radians" Vector__XXX
 SG_ DAS_sw204_frLeftMiddle m204 : 16|8@1+ (1,0) [0|255] "cm" Vector__XXX
 SG_ DAS_sw204_frRightMiddle m204 : 24|8@1+ (1,0) [0|255] "cm" Vector__XXX
 SG_ DAS_sw204_frRight m204 : 32|8@1+ (1,0) [0|255] "cm" Vector__XXX
 SG_ DAS_sw204_frLeft m204 : 40|8@1+ (1,0) [0|255] "cm" Vector__XXX
 SG_ DAS_sw204_frMiddle m204 : 48|8@1+ (1,0) [0|255] "cm" Vector__XXX
 SG_ DAS_sw204_maxSpeed m204 : 56|8@1+ (0.1,-12.2) [-12.2|12.2] "mph" Vector__XXX
 SG_ DAS_sw205_rrRightMiddle m205 : 16|8@1+ (1,0) [0|255] "cm" Vector__XXX
 SG_ DAS_sw205_rrLeftMiddle m205 : 24|8@1+ (1,0) [0|255] "cm" Vector__XXX
 SG_ DAS_sw205_rrRight m205 : 32|8@1+ (1,0) [0|255] "cm" Vector__XXX
 SG_ DAS_sw205_rrLeft m205 : 40|8@1+ (1,0) [0|255] "cm" Vector__XXX
 SG_ DAS_sw205_rrMiddle m205 : 48|8@1+ (1,0) [0|255] "cm" Vector__XXX
 SG_ DAS_sw205_oocDistance m205 : 56|8@1+ (1,0) [0|255] "cm" Vector__XXX
 SG_ DAS_sw207_lcUnavailableReason m207 : 16|8@1+ (1,0) [0|255] "" Vector__XXX
 SG_ DAS_sw207_appMobileyeStatus m207 : 24|8@1+ (1,0) [0|255] "" Vector__XXX
 SG_ DAS_sw207_eyeq3MainState m207 : 32|8@1+ (1,0) [0|255] "" Vector__XXX
 SG_ DAS_sw213_startSpeed m213 : 16|10@1+ (0.1,-50) [-10|92.3] "m/s" Vector__XXX
 SG_ DAS_sw213_endSpeed m213 : 26|10@1+ (0.1,-50) [-10|92.3] "m/s" Vector__XXX
 SG_ DAS_sw213_epasHandsOnDetected m213 : 36|1@1+ (1,0) [0|1] "" Vector__XXX
 SG_ DAS_sw213_autopilotRestricted m213 : 37|1@1+ (1,0) [0|1] "" Vector__XXX
 SG_ DAS_sw213_autopilotIntState m213 : 40|4@1+ (1,0) [0|1] "" Vector__XXX
 SG_ DAS_sw218_pedalPosition m218 : 16|7@1+ (1,0) [0|127] "%" Vector__XXX
 SG_ DAS_sw218_cipvDist m218 : 24|8@1+ (0.2,0) [0|51] "m" Vector__XXX
 SG_ DAS_sw218_handsOnState m218 : 32|4@1+ (1,0) [0|0] "" Vector__XXX
 SG_ DAS_sw218_mcuAutosteerRestricted m218 : 36|1@1+ (1,0) [0|0] "" Vector__XXX
 SG_ DAS_sw218_drivingOnHighway m218 : 37|1@1+ (1,0) [0|0] "" Vector__XXX
 SG_ DAS_sw219_vehicleSpeed m219 : 16|12@1+ (0.05,-25) [-25|179.75] "mph" Vector__XXX
 SG_ DAS_sw219_controlledAccess m219 : 28|1@1+ (1,0) [0|0] "" Vector__XXX
 SG_ DAS_sw219_roadClass m219 : 29|3@1+ (1,0) [0|0] "" Vector__XXX
 SG_ DAS_sw220_vehicleSpeed m220 : 16|12@1+ (0.05,-25) [-25|179.75] "mph" Vector__XXX
 SG_ DAS_sw220_controlledAccess m220 : 28|1@1+ (1,0) [0|0] "" Vector__XXX
 SG_ DAS_sw220_roadClass m220 : 29|3@1+ (1,0) [0|0] "" Vector__XXX

BO_ 1001 DAS_bodyControls: 8 DAS
 SG_ DAS_headlightRequest : 0|2@1+ (1,0) [0|3] "" Vector__XXX
 SG_ DAS_hazardLightRequest : 2|2@1+ (1,0) [0|3] "" Vector__XXX
 SG_ DAS_wiperSpeed : 4|4@1+ (1,0) [0|15] "" Vector__XXX
 SG_ DAS_turnIndicatorRequest : 8|2@1+ (1,0) [0|3] "" Vector__XXX
 SG_ DAS_highLowBeamDecision : 10|2@1+ (1,0) [0|3] "" Vector__XXX
 SG_ DAS_bodyControlsCounter : 52|4@1+ (1,0) [0|15] "" Vector__XXX
 SG_ DAS_bodyControlsChecksum : 56|8@1+ (1,0) [0|255] "" Vector__XXX

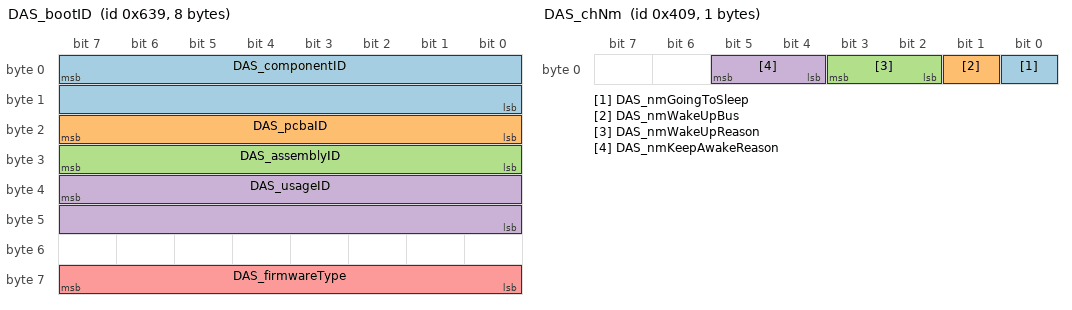
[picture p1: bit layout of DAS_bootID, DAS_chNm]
BO_ 1593 DAS_bootID: 8 DAS
 SG_ DAS_componentID : 7|16@0+ (1,0) [0|65535] "" Vector__XXX
 SG_ DAS_pcbaID : 23|8@0+ (1,0) [0|255] "" Vector__XXX
 SG_ DAS_assemblyID : 31|8@0+ (1,0) [0|255] "" Vector__XXX
 SG_ DAS_usageID : 39|16@0+ (1,0) [0|65535] "" Vector__XXX
 SG_ DAS_firmwareType : 63|8@0+ (1,0) [0|255] "" Vector__XXX

BO_ 1497 DAS_carLog: 8 DAS
 SG_ DAS_carLogMultiplexer M : 0|4@1+ (1,0) [0|15] "" Vector__XXX
 SG_ DAS_radarTarget5_dx m1 : 4|12@1+ (0.0625,0) [0|255.9375] "m" Vector__XXX
 SG_ DAS_radarTarget1_dx m1 : 16|12@1+ (0.0625,0) [0|255.9375] "m" Vector__XXX
 SG_ DAS_radarTarget1_VxRel m1 : 28|8@1+ (0.2,-25.6) [-25.6|25.4] "m/s" Vector__XXX
 SG_ DAS_mobileyeVehAebFlag m2 : 4|1@1+ (1,0) [0|1] "" Vector__XXX
 SG_ DAS_mobileyePedAebFlag m2 : 5|1@1+ (1,0) [0|1] "" Vector__XXX
 SG_ DAS_mobileyeIPSOapproved m2 : 6|1@1+ (1,0) [0|1] "" Vector__XXX
 SG_ DAS_fcmSteeringOverride m2 : 7|1@1+ (1,0) [0|1] "" Vector__XXX
 SG_ DAS_fcmCollisionStage3Checks m2 : 8|8@1+ (1,0) [0|255] "" Vector__XXX
 SG_ DAS_fcmThreatAssesmentMode m2 : 16|3@1+ (1,0) [0|7] "" Vector__XXX
 SG_ DAS_constructionArea m2 : 19|2@1+ (1,0) [0|3] "" Vector__XXX
 SG_ DAS_associated_rad_object m2 : 22|2@1+ (1,0) [0|3] "" Vector__XXX
 SG_ DAS_LC_handsOnReason m2 : 24|6@1+ (1,0) [0|31] "" Vector__XXX
 SG_ DAS_ACC_camStatus m2 : 30|2@1+ (1,0) [0|3] "" Vector__XXX
 SG_ DAS_virtualLaneMaxPeriod m3 : 8|8@1+ (1,0) [0|255] "ms" Vector__XXX
 SG_ DAS_virtualLaneMaxDuration m3 : 16|8@1+ (1,0) [0|255] "ms" Vector__XXX
 SG_ DAS_radarTarget2_dx m3 : 24|12@1+ (0.0625,0) [0|255.9375] "m" Vector__XXX
 SG_ DAS_radarTarget3_dx m3 : 36|12@1+ (0.0625,0) [0|255.9375] "m" Vector__XXX
 SG_ DAS_radarTarget4_dx m3 : 48|12@1+ (0.0625,0) [0|255.9375] "m" Vector__XXX

BO_ 1033 DAS_chNm: 1 DAS
 SG_ DAS_nmGoingToSleep : 0|1@1+ (1,0) [0|0] "" Vector__XXX
 SG_ DAS_nmWakeUpBus : 1|1@1+ (1,0) [0|0] "" Vector__XXX
 SG_ DAS_nmWakeUpReason : 2|2@1+ (1,0) [0|0] "" Vector__XXX
 SG_ DAS_nmKeepAwakeReason : 4|2@1+ (1,0) [0|0] "" Vector__XXX

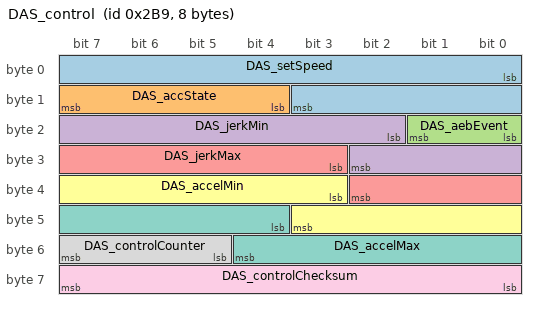
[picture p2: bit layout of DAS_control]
BO_ 697 DAS_control: 8 DAS
 SG_ DAS_setSpeed : 0|12@1+ (0.1,0) [0|409.4] "kph" Vector__XXX
 SG_ DAS_accState : 12|4@1+ (1,0) [0|0] "" Vector__XXX
 SG_ DAS_aebEvent : 16|2@1+ (1,0) [0|3] "" Vector__XXX
 SG_ DAS_jerkMin : 18|9@1+ (0.018,-9.1) [-9.1|0.097999999999999] "m/s^3" Vector__XXX
 SG_ DAS_jerkMax : 27|8@1+ (0.034,0) [0|8.67] "m/s^3" Vector__XXX
 SG_ DAS_accelMin : 35|9@1+ (0.04,-15) [-15|5.44] "m/s^2" Vector__XXX
 SG_ DAS_accelMax : 44|9@1+ (0.04,-15) [-15|5.44] "m/s^2" Vector__XXX
 SG_ DAS_controlCounter : 53|3@1+ (1,0) [0|0] "" Vector__XXX
 SG_ DAS_controlChecksum : 56|8@1+ (1,0) [0|0] "" Vector__XXX

BO_ 1529 DAS_dataLog: 8 DAS
 SG_ DAS_logMltplxr M : 0|8@1+ (1,0) [0|0] "" Vector__XXX
 SG_ DAS_fcmTargetDist1 m1 : 8|9@1+ (0.2,0) [0|102.2] "m" Vector__XXX
 SG_ DAS_fcmTargetRelSpeed1 m1 : 17|9@1+ (0.0625,-31) [-31|0.9375] "m/s" Vector__XXX
 SG_ DAS_fcmTargetOverlap1 m1 : 26|6@1+ (0.1,0) [0|6.3] "m" Vector__XXX
 SG_ DAS_fcmDriverOverrideAccelPed1 m1 : 32|1@1+ (1,0) [0|1] "" Vector__XXX
 SG_ DAS_fcmDriverOverrideBlinker1 m1 : 33|1@1+ (1,0) [0|1] "" Vector__XXX
 SG_ DAS_fcmDriverOverrideSteering1 m1 : 34|1@1+ (1,0) [0|1] "" Vector__XXX
 SG_ DAS_fcmDriverOverrideBrakePedal1 m1 : 35|1@1+ (1,0) [0|1] "" Vector__XXX
 SG_ DAS_fcmTargetAgeAtEvent1 m1 : 36|5@1+ (0.2,0) [0|6.2] "s" Vector__XXX
 SG_ DAS_fcwRequiredAcceleration1 m1 : 41|7@1+ (0.1,-12.7) [-12.7|0] "m/s^2" Vector__XXX
 SG_ DAS_fcmRequiredAcceleration1 m1 : 48|7@1+ (0.1,-12.7) [-12.7|0] "m/s^2" Vector__XXX
 SG_ DAS_fcwCamPedestrianFcwFlag1 m1 : 55|1@1+ (1,0) [0|1] "" Vector__XXX
 SG_ DAS_fcwCamVehicleFcwFlag1 m1 : 56|1@1+ (1,0) [0|1] "" Vector__XXX
 SG_ DAS_fcwDriverReactionTime1 m1 : 57|4@1+ (0.2,0) [0|3] "s" Vector__XXX
 SG_ DAS_fcwUserSensitivity1 m1 : 61|2@1+ (1,0) [0|3] "" Vector__XXX
 SG_ DAS_fcmTargetDist2 m2 : 8|9@1+ (0.2,0) [0|102.2] "m" Vector__XXX
 SG_ DAS_fcmTargetRelSpeed2 m2 : 17|9@1+ (0.0625,-31) [-31|0.9375] "m/s" Vector__XXX
 SG_ DAS_fcmTargetOverlap2 m2 : 26|6@1+ (0.1,0) [0|6.3] "m" Vector__XXX
 SG_ DAS_fcmDriverOverrideAccelPed2 m2 : 32|1@1+ (1,0) [0|1] "" Vector__XXX
 SG_ DAS_fcmDriverOverrideBlinker2 m2 : 33|1@1+ (1,0) [0|1] "" Vector__XXX
 SG_ DAS_fcmDriverOverrideSteering2 m2 : 34|1@1+ (1,0) [0|1] "" Vector__XXX
 SG_ DAS_fcmDriverOverrideBrakePedal2 m2 : 35|1@1+ (1,0) [0|1] "" Vector__XXX
 SG_ DAS_fcmTargetAgeAtEvent2 m2 : 36|5@1+ (0.2,0) [0|6.2] "s" Vector__XXX
 SG_ DAS_aebRequiredAcceleration2 m2 : 41|7@1+ (0.1,-12.7) [-12.7|0] "m/s^2" Vector__XXX
 SG_ DAS_fcmRequiredAcceleration2 m2 : 48|7@1+ (0.1,-12.7) [-12.7|0] "m/s^2" Vector__XXX
 SG_ DAS_aebCamPedestrianAebFlag2 m2 : 55|1@1+ (1,0) [0|1] "" Vector__XXX
 SG_ DAS_aebCamVehicleAebFlag2 m2 : 56|1@1+ (1,0) [0|1] "" Vector__XXX
 SG_ DAS_fcmDtAeb2 m2 : 57|5@1+ (0.2,0) [0|6.2] "s" Vector__XXX
 SG_ DAS_fcmTargetDist3 m3 : 8|9@1+ (0.2,0) [0|102.2] "m" Vector__XXX
 SG_ DAS_fcmTargetRelSpeed3 m3 : 17|9@1+ (0.0625,-31) [-31|0.9375] "m/s" Vector__XXX
 SG_ DAS_fcmTargetOverlap3 m3 : 26|6@1+ (0.1,0) [0|6.3] "m" Vector__XXX
 SG_ DAS_fcmDriverOverrideAccelPed3 m3 : 32|1@1+ (1,0) [0|1] "" Vector__XXX
 SG_ DAS_fcmDriverOverrideBlinker3 m3 : 33|1@1+ (1,0) [0|1] "" Vector__XXX
 SG_ DAS_fcmDriverOverrideSteering3 m3 : 34|1@1+ (1,0) [0|1] "" Vector__XXX
 SG_ DAS_fcmDriverOverrideBrakePedal3 m3 : 35|1@1+ (1,0) [0|1] "" Vector__XXX
 SG_ DAS_fcmTargetAgeAtEvent3 m3 : 36|5@1+ (0.2,0) [0|6.2] "s" Vector__XXX
 SG_ DAS_aebRequiredAcceleration3 m3 : 41|7@1+ (0.1,-12.7) [-12.7|0] "m/s^2" Vector__XXX
 SG_ DAS_fcwRequiredAcceleration3 m3 : 48|7@1+ (0.1,-12.7) [-12.7|0] "m/s^2" Vector__XXX
 SG_ DAS_aebCamPedestrianAebFlag3 m3 : 55|1@1+ (1,0) [0|1] "" Vector__XXX
 SG_ DAS_aebCamVehicleAebFlag3 m3 : 56|1@1+ (1,0) [0|1] "" Vector__XXX
 SG_ DAS_fcwCamPedestrianFcwFlag3 m3 : 57|1@1+ (1,0) [0|1] "" Vector__XXX
 SG_ DAS_fcwCamVehicleFcwFlag3 m3 : 58|1@1+ (1,0) [0|1] "" Vector__XXX
 SG_ DAS_sender4 m4 : 8|2@1+ (1,0) [0|3] "" Vector__XXX
 SG_ DAS_hostSpeed m4 : 10|7@1+ (2,0) [0|254] "kph" Vector__XXX
 SG_ DAS_target_confidence m4 : 17|9@1+ (1,0) [0|511] "" Vector__XXX
 SG_ DAS_hostSteeringWheelAngle m4 : 26|8@1+ (1,-127) [-127|128] "deg" Vector__XXX
 SG_ DAS_hostLongAcceleration m4 : 34|7@1+ (0.15625,-10) [-10|10] "m/s^2" Vector__XXX
 SG_ DAS_accTarget1Present m4 : 41|1@1+ (1,0) [0|1] "" Vector__XXX
 SG_ DAS_radarCipvLateralPos m4 : 42|6@1+ (0.2,-6.3) [-6.3|6.3] "m" Vector__XXX
 SG_ DAS_camCipvValid m4 : 48|1@1+ (1,0) [0|1] "" Vector__XXX
 SG_ DAS_camCipvLateralPos m4 : 49|6@1+ (0.2,-6.3) [-6.3|6.3] "m" Vector__XXX
 SG_ DAS_camRadarMatchConf m4 : 55|3@1+ (1,0) [0|7] "" Vector__XXX
 SG_ DAS_accActive m4 : 58|1@1+ (1,0) [0|1] "" Vector__XXX
 SG_ DAS_fcwUserSwitch m4 : 59|1@1+ (1,0) [0|1] "" Vector__XXX
 SG_ DAS_fcmTargetValid m4 : 60|1@1+ (1,0) [0|1] "" Vector__XXX
 SG_ DAS_fcmMode m4 : 61|3@1+ (1,0) [0|7] "" Vector__XXX
 SG_ DAS_sender5 m5 : 8|2@1+ (1,0) [0|3] "" Vector__XXX
 SG_ DAS_accUserSetting m5 : 10|3@1+ (1,0) [0|7] "" Vector__XXX
 SG_ DAS_radarCipvDist m5 : 14|9@1+ (0.2,0) [0|102.2] "m" Vector__XXX
 SG_ DAS_radarCipvRelSpeed m5 : 23|9@1+ (0.0625,-31) [-31|0.9375] "m/s" Vector__XXX
 SG_ DAS_radarCipvRelAccel m5 : 32|7@1+ (0.15625,-10) [-10|10] "m/s^2" Vector__XXX
 SG_ DAS_camCipvDist m5 : 39|9@1+ (0.2,0) [0|102.2] "m" Vector__XXX
 SG_ DAS_camCipvRelSpeed m5 : 48|9@1+ (0.0625,-31) [-31|0.9375] "m/s" Vector__XXX
 SG_ DAS_camCipvAbsAccel m5 : 57|7@1+ (0.15625,-10) [-10|10] "m/s^2" Vector__XXX
 SG_ DAS_fcmDtDriverBrake m6 : 8|5@1+ (0.2,0) [0|6.2] "s" Vector__XXX
 SG_ DAS_fcmDtDriverSteer m6 : 13|5@1+ (0.2,0) [0|6.2] "s" Vector__XXX
 SG_ DAS_fcmDtDriverFootOffAccelPedal m6 : 18|5@1+ (0.2,0) [0|6.2] "s" Vector__XXX
 SG_ DAS_fcmMinHostLongAcceleration m6 : 23|7@1+ (0.15625,-10) [-10|10] "m/s^2" Vector__XXX
 SG_ DAS_fcmMaxSteeringWheelAngleRate m6 : 30|7@1+ (1,0) [0|127] "deg/s" Vector__XXX
 SG_ DAS_fcmReasonToCancelFcmEvent m6 : 37|8@1+ (1,0) [0|255] "" Vector__XXX
 SG_ DAS_fcmReasonToOverride m6 : 45|4@1+ (1,0) [0|15] "" Vector__XXX
 SG_ DAS_fcmDtOverride m6 : 49|5@1+ (0.2,0) [0|6.2] "s" Vector__XXX
 SG_ DAS_fcmTargetAgeAfterEvent m6 : 54|5@1+ (0.2,0) [0|6.2] "s" Vector__XXX
 SG_ DAS_fcwDtCamFlag m6 : 59|5@1+ (0.2,0) [0|6.2] "s" Vector__XXX
 SG_ DAS_fcmSteeringWheelAngleAfterE m7 : 8|8@1+ (1,-127) [-127|128] "deg" Vector__XXX
 SG_ DAS_fcmHostSpeedAfterEvent m7 : 16|8@1+ (1,0) [0|255] "kph" Vector__XXX
 SG_ DAS_fcmHostSpeedAfterSelfEval m7 : 24|8@1+ (1,0) [0|255] "kph" Vector__XXX
 SG_ DAS_fcmHostYawRateAfterEvent m7 : 32|9@1+ (0.2,-51) [-51|51.2] "deg/s" Vector__XXX
 SG_ DAS_aebDtCamFlag m7 : 41|5@1+ (0.2,0) [0|6.2] "s" Vector__XXX
 SG_ DAS_fcmModeChangedDuringEvent m7 : 47|1@1+ (1,0) [0|1] "" Vector__XXX
 SG_ DAS_aebDtSuppressToFire m7 : 48|5@1+ (0.2,0) [0|6.2] "s" Vector__XXX
 SG_ DAS_fcwDtSuppressToFire m7 : 53|5@1+ (0.2,0) [0|6.2] "s" Vector__XXX
 SG_ DAS_aebMaxTargetProbability m7 : 58|5@1+ (4,0) [0|124] "%" Vector__XXX
 SG_ DAS_sender8 m8 : 8|2@1+ (1,0) [0|3] "" Vector__XXX
 SG_ DAS_fcmLogProtocolVersion m8 : 10|4@1+ (1,0) [0|1] "" Vector__XXX
 SG_ DAS_driverPressedAcceleratorPed m8 : 14|1@1+ (1,0) [0|1] "" Vector__XXX
 SG_ DAS_driverHandsOnSteeringWheel m8 : 16|1@1+ (1,0) [0|1] "" Vector__XXX
 SG_ DAS_espActive m8 : 17|1@1+ (1,0) [0|1] "" Vector__XXX
 SG_ DAS_camCipvWidth m8 : 18|6@1+ (0.1,0) [0|6.3] "m" Vector__XXX
 SG_ DAS_fcmHostLongAcceleration m8 : 24|7@1+ (0.15625,-10) [-10|10] "m/s^2" Vector__XXX
 SG_ DAS_fcmGradeAcceleration m8 : 31|7@1+ (0.1,-12.7) [-12.7|0] "m/s^2" Vector__XXX
 SG_ DAS_fcmTargetProbability m8 : 38|7@1+ (1,0) [0|127] "%" Vector__XXX
 SG_ DAS_fcmTargetLateralRelSpeed m8 : 45|6@1+ (0.1,-3.1) [-3.1|3.2] "m/s" Vector__XXX
 SG_ DAS_fcmTargetPredLateralPos m8 : 51|6@1+ (0.2,-6.3) [-6.3|6.3] "m" Vector__XXX
 SG_ DAS_fcmTargetRelAccel m8 : 57|7@1+ (0.15625,-10) [-10|10] "m/s^2" Vector__XXX
 SG_ DAS_sender9 m9 : 8|2@1+ (1,0) [0|3] "" Vector__XXX
 SG_ DAS_camCipvMatchesAccTarget1 m9 : 10|1@1+ (1,0) [0|1] "" Vector__XXX
 SG_ DAS_camCipvMatchesAccTarget5 m9 : 11|1@1+ (1,0) [0|1] "" Vector__XXX
 SG_ DAS_accTarget5Present m9 : 12|1@1+ (1,0) [0|1] "" Vector__XXX
 SG_ DAS_fcwCancelled m9 : 13|1@1+ (1,0) [0|1] "" Vector__XXX
 SG_ DAS_aebCancelled m9 : 14|1@1+ (1,0) [0|1] "" Vector__XXX
 SG_ DAS_aebFaulted m9 : 15|1@1+ (1,0) [0|1] "" Vector__XXX
 SG_ DAS_accBrakeCapacityWarning m9 : 16|1@1+ (1,0) [0|1] "" Vector__XXX
 SG_ DAS_driverSeatbeltAttached m9 : 17|1@1+ (1,0) [0|1] "" Vector__XXX
 SG_ DAS_driverPressedBrakePedal m9 : 18|1@1+ (1,0) [0|1] "" Vector__XXX
 SG_ DAS_init_version m10 : 8|8@1+ (1,0) [0|255] "" Vector__XXX
 SG_ DAS_leftWheel m10 : 16|8@1+ (0.01,0) [0|100] "m" Vector__XXX
 SG_ DAS_RightWheel m10 : 24|8@1+ (0.01,0) [0|100] "m" Vector__XXX
 SG_ DAS_cameraHeight m10 : 32|8@1+ (0.01,0) [0|150] "m" Vector__XXX
 SG_ DAS_focalLength m10 : 40|16@1+ (1,0) [0|500] "" Vector__XXX
 SG_ DAS_horizonFull m10 : 56|8@1+ (1,0) [0|255] "" Vector__XXX
 SG_ DAS_yawFull m11 : 8|8@1- (1,0) [-128|127] "" Vector__XXX
 SG_ DAS_init_autofixHorizon m11 : 16|8@1- (1,0) [-128|127] "" Vector__XXX
 SG_ DAS_init_autofixYaw m11 : 24|8@1- (1,0) [-128|127] "" Vector__XXX
 SG_ DAS_bottom m11 : 32|8@1- (1,0) [-128|127] "" Vector__XXX
 SG_ DAS_top m11 : 40|8@1+ (1,0) [0|255] "" Vector__XXX
 SG_ DAS_minHorizon m11 : 48|8@1- (1,0) [-128|127] "" Vector__XXX
 SG_ DAS_maxHorizon m11 : 56|8@1- (1,0) [-128|127] "" Vector__XXX
 SG_ DAS_maxYaw m12 : 8|8@1+ (1,0) [0|255] "" Vector__XXX
 SG_ DAS_rollAngle m12 : 16|16@1- (0.001,0) [-1500|1500] "rads" Vector__XXX
 SG_ DAS_regionCode m12 : 32|8@1+ (1,0) [0|11] "" Vector__XXX
 SG_ DAS_drivingSide m12 : 40|2@1+ (1,0) [0|3] "" Vector__XXX
 SG_ DAS_refPointX m12 : 48|8@1+ (0.1,0) [0|0] "m" Vector__XXX
 SG_ DAS_refPointY m12 : 56|8@1+ (0.1,0) [0|255] "m" Vector__XXX
 SG_ DAS_roadEdgeWarningEnabled m13 : 8|8@1+ (1,0) [0|255] "" Vector__XXX
 SG_ DAS_detectConstructionArea m13 : 16|8@1+ (1,0) [0|255] "" Vector__XXX
 SG_ DAS_corridor_outer_boundary m13 : 24|8@1+ (0.01,0) [0|255] "m" Vector__XXX
 SG_ DAS_pos_warn_dist_thresh m13 : 32|8@1+ (0.01,0) [0|255] "m" Vector__XXX
 SG_ DAS_outer_dist_term_warn m13 : 40|8@1+ (0.01,0) [0|255] "m" Vector__XXX
 SG_ DAS_narrow_lane_width m13 : 48|8@1+ (0.1,0) [0|255] "m" Vector__XXX
 SG_ DAS_min_lane_width m13 : 56|8@1+ (0.1,0) [0|255] "m" Vector__XXX
 SG_ DAS_speed_turn_off m14 : 8|8@1+ (0.1,0) [0|255] "m/s" Vector__XXX
 SG_ DAS_speed_turn_on m14 : 16|8@1+ (0.1,0) [0|255] "m/s" Vector__XXX
 SG_ DAS_t_max_wrn m14 : 24|8@1+ (1,0) [0|255] "" Vector__XXX
 SG_ DAS_t_min_wrn m14 : 32|8@1+ (1,0) [0|255] "" Vector__XXX
 SG_ DAS_enableLaneCenterPred m14 : 40|8@1+ (1,0) [0|255] "" Vector__XXX
 SG_ DAS_OC_REDUCED_SENSITIVITY m14 : 48|8@1+ (0.1,0) [0|255] "smth" Vector__XXX
 SG_ DAS_Reserved_1 m14 : 56|8@1+ (1,0) [0|255] "" Vector__XXX
 SG_ DAS_HilMode m15 : 8|8@1+ (1,0) [0|255] "" Vector__XXX
 SG_ DAS_StartupFrameIndex m15 : 16|8@1+ (1,0) [0|255] "" Vector__XXX
 SG_ DAS_forcedNonParallel m15 : 24|8@1+ (1,0) [0|255] "" Vector__XXX
 SG_ DAS_disableRectangular m15 : 32|8@1+ (1,0) [0|255] "" Vector__XXX
 SG_ DAS_Reserved_2 m15 : 40|8@1+ (1,0) [0|255] "" Vector__XXX
 SG_ DAS_calib_reply_ret m16 : 8|8@1+ (1,0) [0|255] "" Vector__XXX
 SG_ DAS_calib_reply_ct_type m16 : 16|8@1+ (1,0) [0|255] "" Vector__XXX
 SG_ DAS_calib_reply_ct_ver m16 : 24|8@1+ (1,0) [0|255] "" Vector__XXX
 SG_ DAS_mesp_health_error_code m16 : 32|8@1+ (1,0) [0|255] "" Vector__XXX
 SG_ DAS_mesp_health_error_details m16 : 40|8@1+ (1,0) [0|255] "" Vector__XXX
 SG_ DAS_mesp_health_main_state m16 : 48|8@1+ (1,0) [0|255] "" Vector__XXX
 SG_ DAS_mesp_health_sub_state m16 : 56|8@1+ (1,0) [0|255] "" Vector__XXX
 SG_ DAS_mesp_health_diag_flag_0 m17 : 8|16@1+ (1,0) [0|255] "" Vector__XXX
 SG_ DAS_mesp_health_diag_flag_1 m17 : 24|16@1+ (1,0) [0|255] "" Vector__XXX
 SG_ DAS_mesp_health_state_data_1 m17 : 40|8@1+ (1,0) [0|255] "" Vector__XXX
 SG_ DAS_mesp_health_state_data_2 m17 : 48|8@1+ (1,0) [0|255] "" Vector__XXX
 SG_ DAS_bootmsg_testResults m18 : 8|16@1+ (1,0) [0|255] "" Vector__XXX
 SG_ DAS_bootmsg_EyeQST_Test m18 : 24|32@1+ (1,0) [0|255] "" Vector__XXX
 SG_ DAS_bootmsg_EyeQ_Temp_CPU m18 : 56|8@1- (1,0) [-128|127] "" Vector__XXX
 SG_ DAS_bootmsg_EyeQ_Temp_VMP m19 : 8|8@1+ (1,0) [0|255] "" Vector__XXX
 SG_ DAS_bootmsg_LPDDR2_temp_status m19 : 16|8@1+ (1,0) [0|255] "" Vector__XXX
 SG_ DAS_bootmsg_BootVersion m19 : 24|32@1+ (1,0) [0|255] "" Vector__XXX
 SG_ DAS_bootmsg_BoardRevision m19 : 56|8@1+ (1,0) [0|255] "" Vector__XXX
 SG_ DAS_bootmsg_ApplicationtVersion m20 : 8|32@1+ (1,0) [0|255] "" Vector__XXX
 SG_ DAS_bootmsg_EyeQ_LotNumber m20 : 40|24@1+ (1,0) [0|255] "" Vector__XXX
 SG_ DAS_bootmsg_DDR_MfgCode m21 : 8|8@1+ (1,0) [0|255] "" Vector__XXX
 SG_ DAS_bootmsg_Flash_MfgCode m21 : 16|8@1+ (1,0) [0|255] "" Vector__XXX
 SG_ DAS_bootmsg_BoardProjectCode m21 : 24|8@1+ (1,0) [0|255] "" Vector__XXX
 SG_ DAS_bootmsg_Flash_2_MfgCode m21 : 32|8@1+ (1,0) [0|255] "" Vector__XXX
 SG_ DAS_bootmsg_DDR_Size m21 : 40|8@1+ (1,0) [0|255] "" Vector__XXX
 SG_ DAS_bootmsg_FlashSize m21 : 48|8@1+ (1,0) [0|255] "" Vector__XXX
 SG_ DAS_bootmsg_Flash_2_Size m21 : 56|8@1+ (1,0) [0|255] "" Vector__XXX
 SG_ DAS_scaLogVersion m22 : 8|3@1+ (1,0) [0|15] "" Vector__XXX
 SG_ DAS_scaLogType m22 : 11|3@1+ (1,0) [0|3] "" Vector__XXX
 SG_ DAS_scaLDWstatus m22 : 14|2@1+ (1,0) [0|3] "" Vector__XXX
 SG_ DAS_scaLeftLaneChange m22 : 16|1@1+ (1,0) [0|1] "" Vector__XXX
 SG_ DAS_scaRightLaneChange m22 : 17|1@1+ (1,0) [0|1] "" Vector__XXX
 SG_ DAS_scaMinLeftUltraDist m22 : 18|9@1+ (0.01,0) [0|5.11] "m" Vector__XXX
 SG_ DAS_scaMinRightUltraDist m22 : 27|9@1+ (0.01,0) [0|5.11] "m" Vector__XXX
 SG_ DAS_scaMaxTorsionBarTorque m22 : 36|12@1+ (0.01,-20.5) [-20.5|20.45] "Nm" Vector__XXX
 SG_ DAS_scaMinTTC m22 : 48|4@1+ (0.1,0) [0|1.6] "s" Vector__XXX
 SG_ DAS_scaMaxSteeringWheelAngleRate m22 : 52|7@1+ (1,-63) [-64|63] "deg/s" Vector__XXX
 SG_ DAS_scaOnHighway m22 : 59|1@1+ (1,0) [0|1] "" Vector__XXX
 SG_ DAS_scaTTCDuration m22 : 60|4@1+ (0.1,0) [0|1.6] "s" Vector__XXX
 SG_ DAS_radarTarg5_dx m23 : 8|8@1+ (0.0625,0) [0|15.9375] "m" Vector__XXX
 SG_ DAS_radarTarg1_dx m23 : 16|8@1+ (0.0625,0) [0|15.9375] "m" Vector__XXX
 SG_ DAS_camGenObj_dx m23 : 24|8@1+ (0.05,0) [0|10] "m" Vector__XXX
 SG_ DAS_camCipv_dx m23 : 32|8@1+ (0.2,0) [0|51] "m" Vector__XXX
 SG_ DAS_camPed_dx m23 : 40|8@1+ (0.2,0) [0|51] "m" Vector__XXX
 SG_ DAS_stwAngle m23 : 48|8@1- (1,0) [-128|127] "deg" Vector__XXX
 SG_ DAS_yawRate m23 : 56|8@1+ (0.015625,-2) [-2|2] "rad/s" Vector__XXX

BO_ 1824 DAS_debug: 8 DAS
 SG_ DAS_debugMultiplexer M : 0|8@1+ (1,0) [0|0] "" Vector__XXX
 SG_ DAS_eyeQMode m0 : 8|8@1+ (1,0) [0|0] "" Vector__XXX
 SG_ DAS_absoluteFrame m0 : 16|32@1+ (1,0) [0|0] "" Vector__XXX
 SG_ DAS_pp_offset_desired m0 : 48|8@1- (0.01,0) [-1.28|1.27] "m" Vector__XXX
 SG_ DAS_appMobileyeStatus m0 : 56|8@1+ (1,0) [0|255] "" Vector__XXX
 SG_ DAS_autofixStatus m1 : 8|2@1+ (1,0) [0|0] "" Vector__XXX
 SG_ DAS_calType m1 : 12|4@1+ (1,0) [0|0] "" Vector__XXX
 SG_ DAS_autofixHorizon m1 : 16|8@1- (1,0) [-30|30] "" Vector__XXX
 SG_ DAS_autofixYaw m1 : 24|8@1- (1,0) [-40|40] "" Vector__XXX
 SG_ DAS_freespaceLeftC0 m2 : 8|8@1+ (0.1,-12.8) [-12.8|12.7] "m" Vector__XXX
 SG_ DAS_freespaceLeftC1 m2 : 16|8@1+ (0.0016,-0.2) [-0.2|0.2] "rad" Vector__XXX
 SG_ DAS_freespaceRightC0 m2 : 24|8@1+ (0.1,-12.8) [-12.8|12.7] "m" Vector__XXX
 SG_ DAS_freespaceRightC1 m2 : 32|8@1+ (0.0016,-0.2) [-0.2|0.2] "rad" Vector__XXX
 SG_ DAS_freespaceLeftFarZ m2 : 40|4@1+ (4,0) [0|60] "m" Vector__XXX
 SG_ DAS_freespaceRightFarZ m2 : 44|4@1+ (4,0) [0|60] "m" Vector__XXX
 SG_ DAS_rawLDW m2 : 48|2@1+ (1,0) [0|2] "" Vector__XXX
 SG_ DAS_freespaceLDW m2 : 50|2@1+ (1,0) [0|2] "" Vector__XXX
 SG_ DAS_lanesValid m2 : 52|1@1+ (1,0) [0|1] "" Vector__XXX
 SG_ DAS_eldw m2 : 53|1@1+ (1,0) [0|1] "" Vector__XXX
 SG_ DAS_laneMerge m2 : 54|2@1+ (1,0) [0|4] "" Vector__XXX
 SG_ DAS_freespaceLeftNearZ m2 : 56|4@1+ (4,0) [0|60] "m" Vector__XXX
 SG_ DAS_freespaceRightNearZ m2 : 60|4@1+ (4,0) [0|60] "m" Vector__XXX
 SG_ DAS_highestSeqRcvd m3 : 8|12@1+ (1,0) [0|0] "" Vector__XXX
 SG_ DAS_errorFrameNum m3 : 20|12@1+ (1,0) [0|0] "" Vector__XXX
 SG_ DAS_numOfOldPktErrs m3 : 32|8@1+ (1,0) [0|0] "" Vector__XXX
 SG_ DAS_numOfSeqErrs m3 : 40|8@1+ (1,0) [0|0] "" Vector__XXX
 SG_ DAS_numOfCrcErrs m3 : 48|8@1+ (1,0) [0|0] "" Vector__XXX
 SG_ DAS_unusedW0 m3 : 56|8@1+ (1,0) [0|0] "" Vector__XXX
 SG_ DAS_Stop_Sign_dist m4 : 8|11@1+ (0.1,-50) [-50|102.3] "m" Vector__XXX
 SG_ DAS_Stop_Sign_detected m4 : 19|1@1+ (1,0) [0|1] "" Vector__XXX
 SG_ DAS_Stop_Sign_warning m4 : 20|1@1+ (1,0) [0|1] "" Vector__XXX
 SG_ DAS_TFL_jnc_status m4 : 21|3@1+ (1,0) [0|1] "" Vector__XXX
 SG_ DAS_TFL_jnc_dist m4 : 24|10@1+ (0.25,-50) [-50|205.75] "m" Vector__XXX
 SG_ DAS_TFL_stop_line_dist m4 : 34|11@1+ (0.1,-50) [-50|102.3] "m" Vector__XXX
 SG_ DAS_TFL_ttc m4 : 45|9@1+ (0.01,0) [0|5.11] "seconds" Vector__XXX
 SG_ DAS_TFL_warning m4 : 54|1@1+ (1,0) [0|1] "" Vector__XXX
 SG_ DAS_TFL_mainID m4 : 56|8@1+ (1,0) [0|255] "" Vector__XXX
 SG_ DAS_tbt_filtered m5 : 8|12@1+ (0.01,-20.5) [-20.5|20.45] "Nm" Vector__XXX
 SG_ DAS_apcIntState m6 : 8|4@1+ (1,0) [0|15] "" Vector__XXX
 SG_ DAS_SP_distance m6 : 12|12@1+ (1,0) [0|4095] "cm" Vector__XXX
 SG_ DAS_SP_instruction m6 : 24|4@1+ (1,0) [0|15] "" Vector__XXX
 SG_ DAS_SP_status m6 : 28|4@1+ (1,0) [0|15] "" Vector__XXX
 SG_ DAS_SP_autoSummonRequest m6 : 32|1@1+ (1,0) [0|1] "" Vector__XXX
 SG_ DAS_estimatedSpeedLimitType m6 : 33|3@1+ (1,0) [0|7] "" Vector__XXX
 SG_ DAS_rampType m6 : 39|2@1+ (1,0) [0|3] "" Vector__XXX
 SG_ DAS_estimatedSpeedLimit m6 : 41|10@1+ (0.2,0) [0|102.2] "mph" Vector__XXX
 SG_ DAS_resumeSpeed m6 : 51|10@1+ (0.2,0) [0|102.2] "mph" Vector__XXX
 SG_ DAS_accTimeGap m6 : 61|3@1+ (0.2,0.8) [0.8|2.2] "s" Vector__XXX
 SG_ DAS_SP_cMin m7 : 8|8@1+ (0.0025,-0.32) [-0.32|0.31] "1/m" Vector__XXX
 SG_ DAS_SP_cMax m7 : 16|8@1+ (0.0025,-0.32) [-0.32|0.31] "1/m" Vector__XXX
 SG_ DAS_SP_interCMin m7 : 24|8@1+ (0.0025,-0.32) [-0.32|0.31] "1/m" Vector__XXX
 SG_ DAS_SP_interCMax m7 : 32|8@1+ (0.0025,-0.32) [-0.32|0.31] "1/m" Vector__XXX
 SG_ DAS_SP_cDesired m7 : 40|8@1+ (0.0025,-0.32) [-0.32|0.31] "1/m" Vector__XXX
 SG_ DAS_SP_vehPosX m8 : 8|12@1+ (0.01,-20.48) [-20.48|20.48] "m" Vector__XXX
 SG_ DAS_SP_vehPosY m8 : 20|12@1+ (0.01,-20.48) [-20.48|20.48] "m" Vector__XXX
 SG_ DAS_SP_endPosX m8 : 32|12@1+ (0.01,-20.48) [-20.48|20.48] "m" Vector__XXX
 SG_ DAS_SP_endPosY m8 : 44|12@1+ (0.01,-20.48) [-20.48|20.48] "m" Vector__XXX
 SG_ DAS_SP_sprecordX m9 : 8|12@1+ (0.01,-20.48) [-20.48|20.48] "m" Vector__XXX
 SG_ DAS_SP_sprecordY m9 : 20|12@1+ (0.01,-20.48) [-20.48|20.48] "m" Vector__XXX
 SG_ DAS_SP_collisionDist m9 : 32|12@1+ (0.01,-20.48) [-20.48|20.48] "m" Vector__XXX
 SG_ DAS_PMM_radar1Distance m9 : 44|10@1+ (0.0625,0) [0|63.9375] "m" Vector__XXX
 SG_ DAS_PMM_radar5Distance m9 : 54|10@1+ (0.0625,0) [0|63.9375] "m" Vector__XXX
 SG_ DAS_dbg_msg_count m10 : 8|8@1+ (1,0) [0|0] "" Vector__XXX
 SG_ DAS_dbg_image_data m10 : 16|48@1+ (1,0) [0|0] "" Vector__XXX
 SG_ DAS_PMM_ttc m11 : 8|8@1+ (0.02,0) [0|5.11] "seconds" Vector__XXX
 SG_ DAS_PMM_obstacleDistance m11 : 16|8@1+ (0.05,0) [0|10] "m" Vector__XXX
 SG_ DAS_PMM_PED_centerPresent m11 : 24|1@1+ (1,0) [0|1] "" Vector__XXX
 SG_ DAS_PMM_PED_leftPresent m11 : 25|1@1+ (1,0) [0|1] "" Vector__XXX
 SG_ DAS_PMM_PED_rightPresent m11 : 26|1@1+ (1,0) [0|1] "" Vector__XXX
 SG_ DAS_PMM_genObj_centerPresent m11 : 27|1@1+ (1,0) [0|1] "" Vector__XXX
 SG_ DAS_PMM_genObj_leftPresent m11 : 28|1@1+ (1,0) [0|1] "" Vector__XXX
 SG_ DAS_PMM_genObj_rightPresent m11 : 29|1@1+ (1,0) [0|1] "" Vector__XXX
 SG_ DAS_PMM_VEH_present m11 : 30|1@1+ (1,0) [0|1] "" Vector__XXX
 SG_ DAS_PMM_genObj_distance m11 : 31|8@1+ (0.05,0) [0|10] "m" Vector__XXX
 SG_ DAS_PMM_ultrasonicsFaultReason m11 : 42|3@1+ (1,0) [0|4] "" Vector__XXX
 SG_ DAS_PMM_radarFaultReason m11 : 45|2@1+ (1,0) [0|3] "" Vector__XXX
 SG_ DAS_PMM_cameraFaultReason m11 : 47|2@1+ (1,0) [0|3] "" Vector__XXX
 SG_ DAS_PMM_collisionConfidence m11 : 49|7@1+ (1,0) [0|100] "%" Vector__XXX
 SG_ DAS_PMM_radarDistance m11 : 56|8@1+ (0.0625,0) [0|15.9375] "m" Vector__XXX
 SG_ DAS_i2c_dev_reg m12 : 8|8@1+ (1,0) [0|255] "" Vector__XXX
 SG_ DAS_i2c_dev_data m12 : 16|8@1+ (1,0) [0|255] "" Vector__XXX
 SG_ DAS_i2c_cmd_idx m12 : 24|16@1+ (1,0) [0|255] "" Vector__XXX
 SG_ DAS_i2c_bytes_written m12 : 40|8@1+ (1,0) [0|255] "" Vector__XXX
 SG_ DAS_i2c_sensor_cmd m12 : 48|16@1+ (1,0) [0|255] "" Vector__XXX
 SG_ DAS_ACC_intState m20 : 8|4@1+ (1,0) [0|0] "" Vector__XXX
 SG_ DAS_ACC_camCIPVStatus m20 : 12|3@1+ (1,0) [0|0] "" Vector__XXX
 SG_ DAS_ACC_radCIPVStatus m20 : 15|3@1+ (1,0) [0|0] "" Vector__XXX
 SG_ DAS_ACC_radObstacleRelevant m20 : 18|1@1+ (1,0) [0|0] "" Vector__XXX
 SG_ DAS_ACC_pedestrianStatus m20 : 19|2@1+ (1,0) [0|0] "" Vector__XXX
 SG_ DAS_ACC_drivingOnHighway m20 : 21|1@1+ (1,0) [0|0] "" Vector__XXX
 SG_ DAS_ACC_Ego_speed m20 : 26|10@1+ (0.05,0) [0|51.15] "m/s" Vector__XXX
 SG_ DAS_ACC_Ego_accel m20 : 36|8@1+ (0.06,-10) [-10|5.3] "m/s^2" Vector__XXX
 SG_ DAS_ACC_deadbandMultiplier m20 : 44|7@1+ (0.008,0) [0|1.016] "1" Vector__XXX
 SG_ DAS_ACC_leftLaneExists m20 : 51|1@1+ (1,0) [0|0] "" Vector__XXX
 SG_ DAS_ACC_rightLaneExists m20 : 52|1@1+ (1,0) [0|0] "" Vector__XXX
 SG_ DAS_ACC_camInFrontOfCIPVRel m20 : 53|1@1+ (1,0) [0|0] "" Vector__XXX
 SG_ DAS_ACC_radInFrontOfCIPVRel m20 : 54|1@1+ (1,0) [0|0] "" Vector__XXX
 SG_ DAS_ACC_controlType m20 : 56|3@1+ (1,0) [0|4] "" Vector__XXX
 SG_ DAS_ACC_overtakeMode m20 : 59|2@1+ (1,0) [0|3] "" Vector__XXX
 SG_ DAS_ACC_BCW_decelCheck m20 : 62|1@1+ (1,0) [0|0] "" Vector__XXX
 SG_ DAS_ACC_BCW m20 : 63|1@1+ (1,0) [0|0] "" Vector__XXX
 SG_ DAS_ACC_camCIPVRadObjID m21 : 8|8@1+ (1,0) [0|0] "" Vector__XXX
 SG_ DAS_ACC_camCIPVRadMatchConf m21 : 16|4@1+ (1,0) [0|0] "" Vector__XXX
 SG_ DAS_ACC_camCIPVClass m21 : 20|4@1+ (1,0) [0|0] "" Vector__XXX
 SG_ DAS_ACC_camCIPVRelevancy m21 : 24|4@1+ (1,0) [0|0] "" Vector__XXX
 SG_ DAS_ACC_camCIPVLane m21 : 28|4@1+ (1,0) [0|0] "" Vector__XXX
 SG_ DAS_ACC_camCIPVLaneStatus m21 : 32|4@1+ (1,0) [0|0] "" Vector__XXX
 SG_ DAS_ACC_camCIPVBrakeLight m21 : 36|4@1+ (1,0) [0|0] "" Vector__XXX
 SG_ DAS_ACC_camCIPVMotionStatus m21 : 40|4@1+ (1,0) [0|0] "" Vector__XXX
 SG_ DAS_ACC_camCIPVLost m21 : 44|2@1+ (1,0) [0|0] "" Vector__XXX
 SG_ DAS_ACC_camCIPVFreeSpace m21 : 46|2@1+ (1,0) [0|0] "" Vector__XXX
 SG_ DAS_ACC_camStopAndGoStatus m21 : 48|2@1+ (1,0) [0|0] "" Vector__XXX
 SG_ DAS_ACC_camLeftCloseCutin m21 : 50|1@1+ (1,0) [0|0] "" Vector__XXX
 SG_ DAS_ACC_camRightCloseCutin m21 : 51|1@1+ (1,0) [0|0] "" Vector__XXX
 SG_ DAS_ACC_camPedestriansPresent m21 : 52|1@1+ (1,0) [0|0] "" Vector__XXX
 SG_ DAS_ACC_pathOverlapWTarget m21 : 53|5@1+ (0.2,-2) [-2|4.2] "m" Vector__XXX
 SG_ DAS_ACC_tgt_cipv_dist m22 : 8|10@1+ (0.2,0) [0|204.6] "m" Vector__XXX
 SG_ DAS_ACC_tgt_cipv_camID m22 : 18|6@1+ (1,0) [0|0] "" Vector__XXX
 SG_ DAS_ACC_tgt_cipv_speed m22 : 24|8@1+ (0.2,-5) [-5|46] "m/s" Vector__XXX
 SG_ DAS_ACC_tgt_cipv_radID m22 : 32|6@1+ (1,0) [0|0] "" Vector__XXX
 SG_ DAS_ACC_tgt_cipv_accel m22 : 38|8@1+ (0.06,-10) [-10|5.3] "m/s^2" Vector__XXX
 SG_ DAS_ACC_tgt_cipv_controlState m22 : 46|4@1+ (1,0) [0|0] "" Vector__XXX
 SG_ DAS_ACC_tgt_cipv_type m22 : 50|4@1+ (1,0) [0|0] "" Vector__XXX
 SG_ DAS_ACC_tgt_cipv_valid m22 : 54|1@1+ (1,0) [0|0] "" Vector__XXX
 SG_ DAS_ACC_tgt_cipv_new m22 : 55|1@1+ (1,0) [0|0] "" Vector__XXX
 SG_ DAS_ACC_tgt_cipv_copied m22 : 56|1@1+ (1,0) [0|0] "" Vector__XXX
 SG_ DAS_ACC_tgt_cipv_brakeLights m22 : 57|1@1+ (1,0) [0|0] "" Vector__XXX
 SG_ DAS_ACC_tgt_cipv_blinkerLeft m22 : 58|1@1+ (1,0) [0|0] "" Vector__XXX
 SG_ DAS_ACC_tgt_cipv_blinkerRight m22 : 59|1@1+ (1,0) [0|0] "" Vector__XXX
 SG_ DAS_ACC_tgt_cipv_delay m22 : 60|4@1+ (20,0) [0|300] "ms" Vector__XXX
 SG_ DAS_ACC_tgt_cipv2_dist m23 : 8|10@1+ (0.2,0) [0|204.6] "m" Vector__XXX
 SG_ DAS_ACC_tgt_cipv2_camID m23 : 18|6@1+ (1,0) [0|0] "" Vector__XXX
 SG_ DAS_ACC_tgt_cipv2_speed m23 : 24|8@1+ (0.2,-5) [-5|46] "m/s" Vector__XXX
 SG_ DAS_ACC_tgt_cipv2_radID m23 : 32|6@1+ (1,0) [0|0] "" Vector__XXX
 SG_ DAS_ACC_tgt_cipv2_accel m23 : 38|8@1+ (0.06,-10) [-10|5.3] "m/s^2" Vector__XXX
 SG_ DAS_ACC_tgt_cipv2_controlState m23 : 46|4@1+ (1,0) [0|0] "" Vector__XXX
 SG_ DAS_ACC_tgt_cipv2_type m23 : 50|4@1+ (1,0) [0|0] "" Vector__XXX
 SG_ DAS_ACC_tgt_cipv2_valid m23 : 54|1@1+ (1,0) [0|0] "" Vector__XXX
 SG_ DAS_ACC_tgt_cipv2_new m23 : 55|1@1+ (1,0) [0|0] "" Vector__XXX
 SG_ DAS_ACC_tgt_cipv2_copied m23 : 56|1@1+ (1,0) [0|0] "" Vector__XXX
 SG_ DAS_ACC_tgt_cipv2_brakeLights m23 : 57|1@1+ (1,0) [0|0] "" Vector__XXX
 SG_ DAS_ACC_tgt_cipv2_blinkerLeft m23 : 58|1@1+ (1,0) [0|0] "" Vector__XXX
 SG_ DAS_ACC_tgt_cipv2_blinkerRight m23 : 59|1@1+ (1,0) [0|0] "" Vector__XXX
 SG_ DAS_ACC_tgt_cipv2_delay m23 : 60|4@1+ (20,0) [0|300] "ms" Vector__XXX
 SG_ DAS_ACC_tgt_mcvl_dist m24 : 8|10@1+ (0.2,0) [0|204.6] "m" Vector__XXX
 SG_ DAS_ACC_tgt_mcvl_camID m24 : 18|6@1+ (1,0) [0|0] "" Vector__XXX
 SG_ DAS_ACC_tgt_mcvl_speed m24 : 24|8@1+ (0.2,-5) [-5|46] "m/s" Vector__XXX
 SG_ DAS_ACC_tgt_mcvl_radID m24 : 32|6@1+ (1,0) [0|0] "" Vector__XXX
 SG_ DAS_ACC_tgt_mcvl_accel m24 : 38|8@1+ (0.06,-10) [-10|5.3] "m/s^2" Vector__XXX
 SG_ DAS_ACC_tgt_mcvl_controlState m24 : 46|4@1+ (1,0) [0|0] "" Vector__XXX
 SG_ DAS_ACC_tgt_mcvl_type m24 : 50|4@1+ (1,0) [0|0] "" Vector__XXX
 SG_ DAS_ACC_tgt_mcvl_valid m24 : 54|1@1+ (1,0) [0|0] "" Vector__XXX
 SG_ DAS_ACC_tgt_mcvl_new m24 : 55|1@1+ (1,0) [0|0] "" Vector__XXX
 SG_ DAS_ACC_tgt_mcvl_copied m24 : 56|1@1+ (1,0) [0|0] "" Vector__XXX
 SG_ DAS_ACC_tgt_mcvl_brakeLights m24 : 57|1@1+ (1,0) [0|0] "" Vector__XXX
 SG_ DAS_ACC_tgt_mcvl_blinkerLeft m24 : 58|1@1+ (1,0) [0|0] "" Vector__XXX
 SG_ DAS_ACC_tgt_mcvl_blinkerRight m24 : 59|1@1+ (1,0) [0|0] "" Vector__XXX
 SG_ DAS_ACC_tgt_mcvl_delay m24 : 60|4@1+ (20,0) [0|300] "ms" Vector__XXX
 SG_ DAS_ACC_tgt_mcvr_dist m25 : 8|10@1+ (0.2,0) [0|204.6] "m" Vector__XXX
 SG_ DAS_ACC_tgt_mcvr_camID m25 : 18|6@1+ (1,0) [0|0] "" Vector__XXX
 SG_ DAS_ACC_tgt_mcvr_speed m25 : 24|8@1+ (0.2,-5) [-5|46] "m/s" Vector__XXX
 SG_ DAS_ACC_tgt_mcvr_radID m25 : 32|6@1+ (1,0) [0|0] "" Vector__XXX
 SG_ DAS_ACC_tgt_mcvr_accel m25 : 38|8@1+ (0.06,-10) [-10|5.3] "m/s^2" Vector__XXX
 SG_ DAS_ACC_tgt_mcvr_controlState m25 : 46|4@1+ (1,0) [0|0] "" Vector__XXX
 SG_ DAS_ACC_tgt_mcvr_type m25 : 50|4@1+ (1,0) [0|0] "" Vector__XXX
 SG_ DAS_ACC_tgt_mcvr_valid m25 : 54|1@1+ (1,0) [0|0] "" Vector__XXX
 SG_ DAS_ACC_tgt_mcvr_new m25 : 55|1@1+ (1,0) [0|0] "" Vector__XXX
 SG_ DAS_ACC_tgt_mcvr_copied m25 : 56|1@1+ (1,0) [0|0] "" Vector__XXX
 SG_ DAS_ACC_tgt_mcvr_brakeLights m25 : 57|1@1+ (1,0) [0|0] "" Vector__XXX
 SG_ DAS_ACC_tgt_mcvr_blinkerLeft m25 : 58|1@1+ (1,0) [0|0] "" Vector__XXX
 SG_ DAS_ACC_tgt_mcvr_blinkerRight m25 : 59|1@1+ (1,0) [0|0] "" Vector__XXX
 SG_ DAS_ACC_tgt_mcvr_delay m25 : 60|4@1+ (20,0) [0|300] "ms" Vector__XXX
 SG_ DAS_ACC_tgt_cutin_dist m26 : 8|10@1+ (0.2,0) [0|204.6] "m" Vector__XXX
 SG_ DAS_ACC_tgt_cutin_camID m26 : 18|6@1+ (1,0) [0|0] "" Vector__XXX
 SG_ DAS_ACC_tgt_cutin_speed m26 : 24|8@1+ (0.2,-5) [-5|46] "m/s" Vector__XXX
 SG_ DAS_ACC_tgt_cutin_radID m26 : 32|6@1+ (1,0) [0|0] "" Vector__XXX
 SG_ DAS_ACC_tgt_cutin_accel m26 : 38|8@1+ (0.06,-10) [-10|5.3] "m/s^2" Vector__XXX
 SG_ DAS_ACC_tgt_cutin_controlState m26 : 46|4@1+ (1,0) [0|0] "" Vector__XXX
 SG_ DAS_ACC_tgt_cutin_type m26 : 50|4@1+ (1,0) [0|0] "" Vector__XXX
 SG_ DAS_ACC_tgt_cutin_valid m26 : 54|1@1+ (1,0) [0|0] "" Vector__XXX
 SG_ DAS_ACC_tgt_cutin_new m26 : 55|1@1+ (1,0) [0|0] "" Vector__XXX
 SG_ DAS_ACC_tgt_cutin_copied m26 : 56|1@1+ (1,0) [0|0] "" Vector__XXX
 SG_ DAS_ACC_tgt_cutin_brakeLights m26 : 57|1@1+ (1,0) [0|0] "" Vector__XXX
 SG_ DAS_ACC_tgt_cutin_blinkerLeft m26 : 58|1@1+ (1,0) [0|0] "" Vector__XXX
 SG_ DAS_ACC_tgt_cutin_blinkerRight m26 : 59|1@1+ (1,0) [0|0] "" Vector__XXX
 SG_ DAS_ACC_tgt_cutin_delay m26 : 60|4@1+ (20,0) [0|300] "ms" Vector__XXX
 SG_ DAS_ACC_Target6_dist m27 : 8|10@1+ (0.2,0) [0|204.6] "m" Vector__XXX
 SG_ DAS_ACC_Target6_camID m27 : 18|6@1+ (1,0) [0|0] "" Vector__XXX
 SG_ DAS_ACC_Target6_speed m27 : 24|8@1+ (0.2,-5) [-5|46] "m/s" Vector__XXX
 SG_ DAS_ACC_Target6_radID m27 : 34|6@1+ (1,0) [0|0] "" Vector__XXX
 SG_ DAS_ACC_Target6_accel m27 : 40|8@1+ (0.06,-10) [-10|5.3] "m/s^2" Vector__XXX
 SG_ DAS_ACC_Target6_controlState m27 : 48|4@1+ (1,0) [0|0] "" Vector__XXX
 SG_ DAS_ACC_Target6_type m27 : 52|4@1+ (1,0) [0|0] "" Vector__XXX
 SG_ DAS_ACC_Target6_valid m27 : 56|1@1+ (1,0) [0|0] "" Vector__XXX
 SG_ DAS_ACC_Target6_new m27 : 57|1@1+ (1,0) [0|0] "" Vector__XXX
 SG_ DAS_ACC_Target6_stop_line_raw m27 : 58|1@1+ (1,0) [0|0] "" Vector__XXX
 SG_ DAS_ACC_Target6_delay m27 : 59|4@1+ (20,0) [0|300] "ms" Vector__XXX
 SG_ DAS_ACC_Control_targetID m28 : 8|4@1+ (1,0) [0|0] "" Vector__XXX
 SG_ DAS_ACC_Control_sl_d m28 : 12|10@1+ (0.2,0) [0|204.6] "m" Vector__XXX
 SG_ DAS_ACC_Control_ve_d m28 : 22|10@1+ (0.05,0) [0|51.15] "m/s" Vector__XXX
 SG_ DAS_ACC_Control_severity m28 : 32|10@1+ (0.005,-2.56) [-2.56|2.555] "1" Vector__XXX
 SG_ DAS_ACC_Control_deltaV_deriv m28 : 42|10@1+ (0.01,-5) [-5|5.23] "m/s^2" Vector__XXX
 SG_ DAS_ACC_Activate_healthy m28 : 52|1@1+ (1,0) [0|0] "" Vector__XXX
 SG_ DAS_ACC_Activate_travel_dist m28 : 53|1@1+ (1,0) [0|0] "" Vector__XXX
 SG_ DAS_ACC_Activate_road_class m28 : 54|1@1+ (1,0) [0|0] "" Vector__XXX
 SG_ DAS_ACC_Activate_stw_angle m28 : 55|1@1+ (1,0) [0|0] "" Vector__XXX
 SG_ DAS_ACC_Activate_rad_tar_5 m28 : 56|1@1+ (1,0) [0|0] "" Vector__XXX
 SG_ DAS_ACC_Activate_ultra_obs m28 : 57|1@1+ (1,0) [0|0] "" Vector__XXX
 SG_ DAS_ACC_Activate_freespace m28 : 58|1@1+ (1,0) [0|0] "" Vector__XXX
 SG_ DAS_ACC_Activate_pedestrian m28 : 59|1@1+ (1,0) [0|0] "" Vector__XXX
 SG_ DAS_ACC_Restrict_targetID m29 : 8|4@1+ (1,0) [0|0] "" Vector__XXX
 SG_ DAS_ACC_Restrict_sl_d m29 : 12|10@1+ (0.2,0) [0|204.6] "m" Vector__XXX
 SG_ DAS_ACC_Restrict_ve_d m29 : 22|10@1+ (0.05,0) [0|51.15] "m/s" Vector__XXX
 SG_ DAS_ACC_Restrict_severity m29 : 32|10@1+ (0.005,-2.56) [-2.56|2.555] "1" Vector__XXX
 SG_ DAS_ACC_Restrict_deltaV_deriv m29 : 42|10@1+ (0.01,-5) [-5|5.23] "m/s^2" Vector__XXX
 SG_ DAS_LC_EgoPitchMotionRate m29 : 52|10@1+ (0.05,-25) [-25|25] "deg/s" Vector__XXX
 SG_ DAS_FCM_CIPV_distance m30 : 8|12@1+ (0.0625,0) [0|255.9375] "m" Vector__XXX
 SG_ DAS_FCM_CIPV_latDistance m30 : 20|12@1- (0.05,0) [-102.4|102.35] "m" Vector__XXX
 SG_ DAS_FCM_CIPV_width m30 : 32|7@1+ (0.05,0) [0|6.35] "m" Vector__XXX
 SG_ DAS_FCM_CIPV_relSpeed m30 : 39|12@1+ (0.0625,-128) [-128|127.9375] "m/s" Vector__XXX
 SG_ DAS_FCM_CIPV_relAccel m30 : 51|10@1+ (0.03125,-16) [-16|15.96875] "m/s^2" Vector__XXX
 SG_ DAS_FCM_CIPV_valid m30 : 61|1@1+ (1,0) [0|0] "" Vector__XXX
 SG_ DAS_FCM_CIPV_radarMatchConfOK m30 : 62|1@1+ (1,0) [0|0] "" Vector__XXX
 SG_ DAS_FCM_MCP_distance m31 : 8|12@1+ (0.0625,0) [0|255.9375] "m" Vector__XXX
 SG_ DAS_FCM_MCP_latDistance m31 : 20|12@1- (0.05,0) [-102.4|102.35] "m" Vector__XXX
 SG_ DAS_FCM_MCP_width m31 : 32|7@1+ (0.05,0) [0|6.35] "m" Vector__XXX
 SG_ DAS_FCM_MCP_relSpeed m31 : 39|12@1+ (0.0625,-128) [-128|127.9375] "m/s" Vector__XXX
 SG_ DAS_FCM_MCP_relAccel m31 : 51|10@1+ (0.03125,-16) [-16|15.96875] "m/s^2" Vector__XXX
 SG_ DAS_FCM_MCP_valid m31 : 61|1@1+ (1,0) [0|0] "" Vector__XXX
 SG_ DAS_FCM_MCP_radarMatchConfOK m31 : 62|1@1+ (1,0) [0|0] "" Vector__XXX
 SG_ DAS_FCM_SL_distance m32 : 8|12@1+ (0.0625,0) [0|255.9375] "m" Vector__XXX
 SG_ DAS_FCM_SL_latDistance m32 : 20|12@1- (0.05,0) [-102.4|102.35] "m" Vector__XXX
 SG_ DAS_FCM_SL_width m32 : 32|7@1+ (0.05,0) [0|6.35] "m" Vector__XXX
 SG_ DAS_FCM_SL_relSpeed m32 : 39|12@1+ (0.0625,-128) [-128|127.9375] "m/s" Vector__XXX
 SG_ DAS_FCM_SL_relAccel m32 : 51|10@1+ (0.03125,-16) [-16|15.96875] "m/s^2" Vector__XXX
 SG_ DAS_FCM_SL_valid m32 : 61|1@1+ (1,0) [0|0] "" Vector__XXX
 SG_ DAS_FCM_SL_radarMatchConfOK m32 : 62|1@1+ (1,0) [0|0] "" Vector__XXX
 SG_ DAS_FCM_TA_collisionStage m33 : 8|2@1+ (1,0) [0|0] "" Vector__XXX
 SG_ DAS_FCM_TA_collisionOverlap m33 : 10|6@1+ (0.1,0) [0|6.3] "m" Vector__XXX
 SG_ DAS_FCM_state m33 : 16|8@1+ (1,0) [0|0] "" Vector__XXX
 SG_ DAS_FCM_TA_rstCollStRsn m33 : 24|8@1+ (1,0) [0|255] "" Vector__XXX
 SG_ DAS_FCM_TA_reqAccelDrvr m33 : 32|7@1+ (0.1,-12.7) [-12.7|0] "m/s^2" Vector__XXX
 SG_ DAS_FCM_TA_reqAccelAeb m33 : 39|7@1+ (0.1,-12.7) [-12.7|0] "m/s^2" Vector__XXX
 SG_ DAS_FCM_TA_distDiffSteerDrvr m33 : 46|8@1+ (0.1,0) [0|25.5] "m" Vector__XXX
 SG_ DAS_FCM_TA_distDiffSteerAeb m33 : 54|8@1+ (0.1,0) [0|25.5] "m" Vector__XXX
 SG_ DAS_FCM_TA_mode m33 : 62|2@1+ (1,0) [0|3] "" Vector__XXX
 SG_ DAS_FCM_TA_stage2Checks m34 : 24|8@1+ (1,0) [0|255] "" Vector__XXX
 SG_ DAS_FCM_TA_stage3Checks m34 : 32|8@1+ (1,0) [0|255] "" Vector__XXX
 SG_ DAS_FCM_DBG_suppressed m34 : 40|1@1+ (1,0) [0|1] "" Vector__XXX
 SG_ DAS_FCM_DBG_me_flag m34 : 41|1@1+ (1,0) [0|1] "" Vector__XXX
 SG_ DAS_FCM_DBG_aeb_cancel m34 : 43|1@1+ (1,0) [0|1] "" Vector__XXX
 SG_ DAS_FCM_DBG_aeb_fault m34 : 44|1@1+ (1,0) [0|1] "" Vector__XXX
 SG_ DAS_FCM_DBG_ACC1_fused m34 : 45|1@1+ (1,0) [0|1] "" Vector__XXX
 SG_ DAS_FCM_DBG_ACC5_fused m34 : 46|1@1+ (1,0) [0|1] "" Vector__XXX
 SG_ DAS_FCM_DBG_ID m34 : 47|16@1+ (1,0) [0|65534] "" Vector__XXX
 SG_ DAS_FCM_DBG_cam_dist m35 : 8|12@1+ (0.0625,0) [0|255.9375] "m" Vector__XXX
 SG_ DAS_FCM_DBG_cam_relvel m35 : 20|12@1+ (0.0625,-128) [-128|127.9375] "m/s" Vector__XXX
 SG_ DAS_FCM_DBG_probability m35 : 32|6@1+ (0.05,0) [0|3.15] "prob" Vector__XXX
 SG_ DAS_FCM_DBG_trust m35 : 38|6@1+ (0.05,0) [0|3.15] "prob" Vector__XXX
 SG_ DAS_FCM_DBG_rvl_check m35 : 44|6@1+ (0.05,0) [0|3.15] "prob" Vector__XXX
 SG_ DAS_FCM_DBG_dist_check m35 : 50|6@1+ (0.05,0) [0|3.15] "prob" Vector__XXX
 SG_ DAS_FCM_DBG_ass_age m35 : 56|6@1+ (100,0) [0|6300] "" Vector__XXX
 SG_ DAS_IDF_checkSensors m36 : 8|1@1+ (1,0) [0|1] "" Vector__XXX
 SG_ DAS_IDF_checkClass m36 : 9|1@1+ (1,0) [0|1] "" Vector__XXX
 SG_ DAS_IDF_checkOverlap m36 : 10|1@1+ (1,0) [0|1] "" Vector__XXX
 SG_ DAS_IDF_checkTimeToCollision m36 : 11|1@1+ (1,0) [0|1] "" Vector__XXX
 SG_ DAS_IDF_checkTargetProbability m36 : 12|1@1+ (1,0) [0|1] "" Vector__XXX
 SG_ DAS_IDF_checkSteeringAvoidance m36 : 13|1@1+ (1,0) [0|1] "" Vector__XXX
 SG_ DAS_IDF_checkBrakingAvoidance m36 : 14|1@1+ (1,0) [0|1] "" Vector__XXX
 SG_ DAS_IDF_checkEgoSpeed m36 : 15|1@1+ (1,0) [0|1] "" Vector__XXX
 SG_ DAS_IDF_timeToCollision m36 : 16|8@1+ (10,0) [0|2550] "ms" Vector__XXX
 SG_ DAS_IDF_objectClass m36 : 24|3@1+ (1,0) [0|7] "" Vector__XXX
 SG_ DAS_IDF_predictedImpactVelocity m36 : 27|7@1+ (0.5,-63.5) [-63.5|0] "m/s" Vector__XXX
 SG_ DAS_IDF_predictedOverlap m36 : 34|8@1+ (0.5,0) [0|127.5] "%" Vector__XXX
 SG_ DAS_LC_VirtualLaneViewRange m40 : 8|10@1+ (0.5,0) [0|511.5] "m" Vector__XXX
 SG_ DAS_LC_VirtualLaneWidth m40 : 18|8@1+ (0.025,0) [0|6.375] "m" Vector__XXX
 SG_ DAS_LC_AutopilotInternalState m40 : 26|4@1+ (1,0) [0|15] "" Vector__XXX
 SG_ DAS_LC_Speed_Ctrl_Active m40 : 30|1@1+ (1,0) [0|1] "" Vector__XXX
 SG_ DAS_LC_Crit_Left_Lane m40 : 31|8@1+ (0.2,-25.5) [-25.5|25.5] "m" Vector__XXX
 SG_ DAS_LC_Crit_Right_Lane m40 : 47|8@1+ (0.2,-25.5) [-25.5|25.5] "m" Vector__XXX
 SG_ DAS_LC_Hands_On_Caused_By_Curve m40 : 63|1@1+ (1,0) [0|1] "" Vector__XXX
 SG_ DAS_HmViewRangeActivationCtr m41 : 8|7@1+ (1,0) [0|127] "" Vector__XXX
 SG_ DAS_HmGeneralActivationCtr m41 : 16|7@1+ (1,0) [0|127] "" Vector__XXX
 SG_ DAS_HmSecondaryVlInput m41 : 23|1@1+ (1,0) [0|1] "" Vector__XXX
 SG_ DAS_PF_Navigation_STW m41 : 24|13@1+ (0.1,-409.6) [-409.6|409.5] "deg" Vector__XXX
 SG_ DAS_PF_VirtualLane_STW m41 : 37|13@1+ (0.1,-409.6) [-409.6|409.5] "deg" Vector__XXX
 SG_ DAS_PF_PercentConsistency m41 : 50|14@1+ (0.01,0) [0|163.83] "%" Vector__XXX
 SG_ DAS_LC_SteeringOffsetEstimate m42 : 8|8@1- (0.1,0) [-12.8|12.7] "deg" Vector__XXX
 SG_ DAS_LC_PathFollowerAngle m42 : 24|13@1- (0.1,0) [-409.6|409.5] "deg" Vector__XXX
 SG_ DAS_HmLaneViewRangeOAL m42 : 40|3@1+ (1,0) [0|5] "" Vector__XXX
 SG_ DAS_HmVlNoInputsOAL m42 : 61|3@1+ (1,0) [0|5] "" Vector__XXX
 SG_ DAS_VWall_Left_ultra_dist m43 : 8|9@1+ (0.01,0) [0|5.11] "m" Vector__XXX
 SG_ DAS_VWall_Right_type m44 : 8|3@1+ (1,0) [0|7] "" Vector__XXX
 SG_ DAS_VWall_Right_ultra_dist m44 : 16|9@1+ (0.01,0) [0|5.11] "m" Vector__XXX
 SG_ DAS_VWall_Right_c0 m44 : 32|8@1+ (0.035,0) [0|7] "m" Vector__XXX
 SG_ DAS_VWall_Right_c1 m44 : 40|8@1+ (0.0016,-0.2) [-0.2|0.2] "rad" Vector__XXX
 SG_ DAS_VWall_Right_c2 m44 : 48|8@1+ (2E-005,-0.0025) [-0.0025|0.0025] "m-1" Vector__XXX
 SG_ DAS_VWall_Right_c3 m44 : 56|8@1+ (2.4E-007,-3E-005) [-3E-005|3E-005] "m-2" Vector__XXX
 SG_ DAS_SCA_state m45 : 8|4@1+ (1,0) [0|15] "" Vector__XXX
 SG_ DAS_SCA_angleActive m45 : 12|1@1+ (1,0) [0|1] "" Vector__XXX
 SG_ DAS_SCA_egoRightOfCenter m45 : 13|1@1+ (1,0) [0|1] "" Vector__XXX
 SG_ DAS_SCA_egoLeftOfCenter m45 : 14|1@1+ (1,0) [0|1] "" Vector__XXX
 SG_ DAS_SCA_egoMovingLeft m45 : 15|1@1+ (1,0) [0|1] "" Vector__XXX
 SG_ DAS_SCA_TWC_Left m45 : 16|8@1+ (0.01,0) [0|2.55] "s" Vector__XXX
 SG_ DAS_SCA_TWC_Right m45 : 24|8@1+ (0.01,0) [0|2.55] "s" Vector__XXX
 SG_ DAS_torque_filt_0p5Hz m45 : 32|12@1+ (0.01,-20.5) [-20.5|20.45] "Nm" Vector__XXX
 SG_ DAS_hands_on_detected m45 : 44|1@1+ (1,0) [0|1] "" Vector__XXX
 SG_ DAS_TBT_offset m45 : 45|11@1+ (0.001,-1) [-1|1] "Nm" Vector__XXX
 SG_ DAS_hands_on_warning_cipv_valid m45 : 59|1@1+ (1,0) [0|1] "" Vector__XXX
 SG_ DAS_SCA_egoMovingRight m45 : 60|1@1+ (1,0) [0|1] "" Vector__XXX
 SG_ DAS_SCA_polyValid m45 : 61|1@1+ (1,0) [0|1] "" Vector__XXX
 SG_ DAS_SCA_egoCentered m45 : 62|1@1+ (1,0) [0|1] "" Vector__XXX
 SG_ DAS_driver_interaction_detected m45 : 63|1@1+ (1,0) [0|1] "" Vector__XXX
 SG_ DAS_Planner_viewRange m46 : 8|9@1+ (0.5,0) [0|255.5] "m" Vector__XXX
 SG_ DAS_Planner_internalstate m46 : 17|4@1+ (1,0) [0|12] "" Vector__XXX
 SG_ DAS_Planner_externalstate m46 : 21|4@1+ (1,0) [0|15] "" Vector__XXX
 SG_ DAS_Planner_c0 m46 : 32|8@1- (0.1,0) [-12.8|12.7] "m" Vector__XXX
 SG_ DAS_Planner_c1 m46 : 40|8@1+ (0.0016,-0.2) [-0.2|0.2] "rad" Vector__XXX
 SG_ DAS_Planner_c2 m46 : 48|8@1+ (2E-005,-0.0025) [-0.0025|0.0025] "m-1" Vector__XXX
 SG_ DAS_Planner_c3 m46 : 56|8@1+ (2.4E-007,-3E-005) [-3E-005|3E-005] "m-2" Vector__XXX
 SG_ DAS_csa_accel_max m47 : 8|8@1+ (0.08,-10.24) [-10.24|10] "m/s^2" Vector__XXX
 SG_ DAS_csa_predictedLatAccel m47 : 16|8@1+ (0.08,-10.24) [-10.24|10] "m/s^2" Vector__XXX
 SG_ DAS_csa_filteredCurvature m47 : 24|16@1- (1E-006,0) [-0.032768|0.032767] "1/m" Vector__XXX
 SG_ DAS_csa_desiredVelPred m47 : 40|8@1+ (0.29,15) [15|88.95] "MPH" Vector__XXX
 SG_ DAS_csa_measuredLatAccel m47 : 48|8@1+ (0.08,-10.24) [-10.24|10] "m/s^2" Vector__XXX
 SG_ DAS_csa_desiredVelMeas m47 : 56|8@1+ (0.29,15) [15|88.95] "MPH" Vector__XXX
 SG_ DAS_csa_internal_state m48 : 8|4@1+ (1,0) [0|7] "" Vector__XXX
 SG_ DAS_pp_lanechange_fwdObst m48 : 12|1@1+ (1,0) [0|1] "" Vector__XXX
 SG_ DAS_pp_lanechange_inputsValid m48 : 13|1@1+ (1,0) [0|1] "" Vector__XXX
 SG_ DAS_pp_lanechange_side m48 : 14|2@1+ (1,0) [0|1] "" Vector__XXX
 SG_ DAS_pp_laneChange_destLanesValid m48 : 16|1@1+ (1,0) [0|1] "" Vector__XXX
 SG_ DAS_pp_laneChange_egoLaneValid m48 : 17|1@1+ (1,0) [0|1] "" Vector__XXX
 SG_ DAS_pp_laneChange_anyObstacle m48 : 18|1@1+ (1,0) [0|1] "" Vector__XXX
 SG_ DAS_pp_laneChange_closeObstacle m48 : 19|1@1+ (1,0) [0|1] "" Vector__XXX
 SG_ DAS_pp_laneChange_LC_healthy m48 : 20|1@1+ (1,0) [0|1] "" Vector__XXX
 SG_ DAS_pp_laneChange_blinkerCheck m48 : 21|1@1+ (1,0) [0|1] "" Vector__XXX
 SG_ DAS_torque_filt_0p05Hz m48 : 22|12@1+ (0.01,-20.5) [-20.5|20.45] "Nm" Vector__XXX
 SG_ DAS_csa_using_offramp m48 : 34|1@1+ (1,0) [0|1] "" Vector__XXX
 SG_ DAS_csa_using_frozen_offramp m48 : 35|1@1+ (1,0) [0|1] "" Vector__XXX
 SG_ DAS_csa_mpp_jumped_up m48 : 36|1@1+ (1,0) [0|1] "" Vector__XXX
 SG_ DAS_csa_mpp_jump_up_distance m48 : 37|8@1+ (10,0) [0|2550] "m" Vector__XXX
 SG_ DAS_csa_offramp_usage_duration m48 : 45|8@1+ (256,0) [0|65535] "" Vector__XXX
 SG_ DAS_pp_laneChange_freesp_avail_l m48 : 61|1@1+ (1,0) [0|1] "" Vector__XXX
 SG_ DAS_pp_laneChange_freesp_avail_r m48 : 62|1@1+ (1,0) [0|1] "" Vector__XXX
 SG_ DAS_pp_offset_objectStateLeft m49 : 16|3@1+ (1,0) [0|7] "" Vector__XXX
 SG_ DAS_pp_offset_objectStateRight m49 : 19|3@1+ (1,0) [0|7] "" Vector__XXX
 SG_ DAS_pp_offset_activeLeft m49 : 22|1@1+ (1,0) [0|1] "" Vector__XXX
 SG_ DAS_pp_offset_activeRight m49 : 23|1@1+ (1,0) [0|1] "" Vector__XXX
 SG_ DAS_pp_offset_offsetObjectLeft m49 : 24|8@1- (0.01,0) [-1.28|1.27] "m" Vector__XXX
 SG_ DAS_pp_offset_offsetObjectRight m49 : 32|8@1- (0.01,0) [-1.28|1.27] "m" Vector__XXX
 SG_ DAS_pp_offset_objDurationLeft m49 : 40|8@1+ (4,0) [0|1000] "s" Vector__XXX
 SG_ DAS_pp_offset_objDurationRight m49 : 48|8@1+ (4,0) [0|1000] "s" Vector__XXX
 SG_ DAS_VL_HPP_rejectCounter m50 : 8|1@1+ (1,0) [0|1] "" Vector__XXX
 SG_ DAS_VL_leftFsParallelLeftLane m50 : 13|1@1+ (1,0) [0|1] "" Vector__XXX
 SG_ DAS_VL_leftFsParallelRightLane m50 : 14|1@1+ (1,0) [0|1] "" Vector__XXX
 SG_ DAS_VL_rightFsParallelLeftLane m50 : 15|1@1+ (1,0) [0|1] "" Vector__XXX
 SG_ DAS_VL_rightFsParallelRightLane m50 : 16|1@1+ (1,0) [0|1] "" Vector__XXX
 SG_ DAS_VL_LL_quality m50 : 17|1@1+ (1,0) [0|1] "" Vector__XXX
 SG_ DAS_VL_RL_quality m50 : 18|1@1+ (1,0) [0|1] "" Vector__XXX
 SG_ DAS_VL_HPP_quality m50 : 19|1@1+ (1,0) [0|1] "" Vector__XXX
 SG_ DAS_VL_NAV_quality m50 : 20|1@1+ (1,0) [0|1] "" Vector__XXX
 SG_ DAS_VL_V1_quality m50 : 21|1@1+ (1,0) [0|1] "" Vector__XXX
 SG_ DAS_VL_WidthMeasType m50 : 22|3@1+ (1,0) [0|1] "" Vector__XXX
 SG_ DAS_VL_Reinitialized m50 : 25|1@1+ (1,0) [0|1] "" Vector__XXX
 SG_ DAS_VL_LL_rejectQuality m50 : 26|1@1+ (1,0) [0|1] "" Vector__XXX
 SG_ DAS_VL_LL_rejectType m50 : 27|1@1+ (1,0) [0|1] "" Vector__XXX
 SG_ DAS_VL_LL_rejectRange m50 : 28|1@1+ (1,0) [0|1] "" Vector__XXX
 SG_ DAS_VL_LL_rejectFreespace m50 : 29|1@1+ (1,0) [0|1] "" Vector__XXX
 SG_ DAS_VL_LL_rejectDyingLine m50 : 30|1@1+ (1,0) [0|1] "" Vector__XXX
 SG_ DAS_VL_LL_rejectLatDiffAtCP m50 : 31|1@1+ (1,0) [0|1] "" Vector__XXX
 SG_ DAS_VL_LL_rejectPrediction m50 : 32|1@1+ (1,0) [0|1] "" Vector__XXX
 SG_ DAS_VL_LL_rejectHWExit m50 : 33|1@1+ (1,0) [0|1] "" Vector__XXX
 SG_ DAS_VL_LL_rejectCounter m50 : 34|1@1+ (1,0) [0|1] "" Vector__XXX
 SG_ DAS_VL_RL_rejectQuality m50 : 35|1@1+ (1,0) [0|1] "" Vector__XXX
 SG_ DAS_VL_RL_rejectType m50 : 36|1@1+ (1,0) [0|1] "" Vector__XXX
 SG_ DAS_VL_RL_rejectRange m50 : 37|1@1+ (1,0) [0|1] "" Vector__XXX
 SG_ DAS_VL_RL_rejectFreespace m50 : 38|1@1+ (1,0) [0|1] "" Vector__XXX
 SG_ DAS_VL_RL_rejectDyingLine m50 : 39|1@1+ (1,0) [0|1] "" Vector__XXX
 SG_ DAS_VL_RL_rejectLatDiffAtCP m50 : 40|1@1+ (1,0) [0|1] "" Vector__XXX
 SG_ DAS_VL_RL_rejectPrediction m50 : 41|1@1+ (1,0) [0|1] "" Vector__XXX
 SG_ DAS_VL_RL_rejectHWExit m50 : 42|1@1+ (1,0) [0|1] "" Vector__XXX
 SG_ DAS_VL_RL_rejectCounter m50 : 43|1@1+ (1,0) [0|1] "" Vector__XXX
 SG_ DAS_VL_HPP_rejectError m50 : 44|1@1+ (1,0) [0|1] "" Vector__XXX
 SG_ DAS_VL_HPP_rejectRange m50 : 45|1@1+ (1,0) [0|1] "" Vector__XXX
 SG_ DAS_VL_HPP_rejectWiper m50 : 46|1@1+ (1,0) [0|1] "" Vector__XXX
 SG_ DAS_VL_HPP_rejectNight m50 : 47|1@1+ (1,0) [0|1] "" Vector__XXX
 SG_ DAS_VL_HPP_rejectCipvClose m50 : 48|1@1+ (1,0) [0|1] "" Vector__XXX
 SG_ DAS_VL_NAV_rejectHealth m50 : 49|1@1+ (1,0) [0|1] "" Vector__XXX
 SG_ DAS_VL_NAV_rejectAge m50 : 50|1@1+ (1,0) [0|1] "" Vector__XXX
 SG_ DAS_VL_NAV_rejectCounter m50 : 51|1@1+ (1,0) [0|1] "" Vector__XXX
 SG_ DAS_VL_V2_quality m50 : 52|1@1+ (1,0) [0|1] "" Vector__XXX
 SG_ DAS_VL_V3_quality m50 : 53|1@1+ (1,0) [0|1] "" Vector__XXX
 SG_ DAS_VL_V4_quality m50 : 54|1@1+ (1,0) [0|1] "" Vector__XXX
 SG_ DAS_VL_V5_quality m50 : 55|1@1+ (1,0) [0|1] "" Vector__XXX
 SG_ DAS_VL_Mode m50 : 56|4@1+ (1,0) [0|15] "" Vector__XXX
 SG_ DAS_VL_LinePreference m50 : 60|3@1+ (1,0) [0|7] "" Vector__XXX
 SG_ DAS_VL_M_LL_crossCheck m51 : 8|1@1+ (1,0) [0|1] "" Vector__XXX
 SG_ DAS_VL_M_RL_crossCheck m51 : 9|1@1+ (1,0) [0|1] "" Vector__XXX
 SG_ DAS_VL_M_HPP_crossCheck m51 : 10|1@1+ (1,0) [0|1] "" Vector__XXX
 SG_ DAS_VL_M_NAV_crossCheck m51 : 11|1@1+ (1,0) [0|1] "" Vector__XXX
 SG_ DAS_VL_M_V1_crossCheck m51 : 12|1@1+ (1,0) [0|1] "" Vector__XXX
 SG_ DAS_VL_M_V2_crossCheck m51 : 13|1@1+ (1,0) [0|1] "" Vector__XXX
 SG_ DAS_VL_M_V3_crossCheck m51 : 14|1@1+ (1,0) [0|1] "" Vector__XXX
 SG_ DAS_VL_M_V4_crossCheck m51 : 15|1@1+ (1,0) [0|1] "" Vector__XXX
 SG_ DAS_VL_M_V5_crossCheck m51 : 16|1@1+ (1,0) [0|1] "" Vector__XXX
 SG_ DAS_VL_LL_RL_crossCheck m51 : 17|1@1+ (1,0) [0|1] "" Vector__XXX
 SG_ DAS_VL_LL_HPP_crossCheck m51 : 18|1@1+ (1,0) [0|1] "" Vector__XXX
 SG_ DAS_VL_LL_NAV_crossCheck m51 : 19|1@1+ (1,0) [0|1] "" Vector__XXX
 SG_ DAS_VL_LL_V1_crossCheck m51 : 20|1@1+ (1,0) [0|1] "" Vector__XXX
 SG_ DAS_VL_LL_V2_crossCheck m51 : 21|1@1+ (1,0) [0|1] "" Vector__XXX
 SG_ DAS_VL_LL_V3_crossCheck m51 : 22|1@1+ (1,0) [0|1] "" Vector__XXX
 SG_ DAS_VL_LL_V4_crossCheck m51 : 23|1@1+ (1,0) [0|1] "" Vector__XXX
 SG_ DAS_VL_LL_V5_crossCheck m51 : 24|1@1+ (1,0) [0|1] "" Vector__XXX
 SG_ DAS_VL_RL_HPP_crossCheck m51 : 25|1@1+ (1,0) [0|1] "" Vector__XXX
 SG_ DAS_VL_RL_NAV_crossCheck m51 : 26|1@1+ (1,0) [0|1] "" Vector__XXX
 SG_ DAS_VL_RL_V1_crossCheck m51 : 27|1@1+ (1,0) [0|1] "" Vector__XXX
 SG_ DAS_VL_RL_V2_crossCheck m51 : 28|1@1+ (1,0) [0|1] "" Vector__XXX
 SG_ DAS_VL_RL_V3_crossCheck m51 : 29|1@1+ (1,0) [0|1] "" Vector__XXX
 SG_ DAS_VL_RL_V4_crossCheck m51 : 30|1@1+ (1,0) [0|1] "" Vector__XXX
 SG_ DAS_VL_RL_V5_crossCheck m51 : 31|1@1+ (1,0) [0|1] "" Vector__XXX
 SG_ DAS_VL_HPP_NAV_crossCheck m51 : 32|1@1+ (1,0) [0|1] "" Vector__XXX
 SG_ DAS_VL_HPP_V1_crossCheck m51 : 33|1@1+ (1,0) [0|1] "" Vector__XXX
 SG_ DAS_VL_HPP_V2_crossCheck m51 : 34|1@1+ (1,0) [0|1] "" Vector__XXX
 SG_ DAS_VL_HPP_V3_crossCheck m51 : 35|1@1+ (1,0) [0|1] "" Vector__XXX
 SG_ DAS_VL_HPP_V4_crossCheck m51 : 36|1@1+ (1,0) [0|1] "" Vector__XXX
 SG_ DAS_VL_HPP_V5_crossCheck m51 : 37|1@1+ (1,0) [0|1] "" Vector__XXX
 SG_ DAS_VL_NAV_V1_crossCheck m51 : 38|1@1+ (1,0) [0|1] "" Vector__XXX
 SG_ DAS_VL_NAV_V2_crossCheck m51 : 39|1@1+ (1,0) [0|1] "" Vector__XXX
 SG_ DAS_VL_NAV_V3_crossCheck m51 : 40|1@1+ (1,0) [0|1] "" Vector__XXX
 SG_ DAS_VL_NAV_V4_crossCheck m51 : 41|1@1+ (1,0) [0|1] "" Vector__XXX
 SG_ DAS_VL_NAV_V5_crossCheck m51 : 42|1@1+ (1,0) [0|1] "" Vector__XXX
 SG_ DAS_VL_V1_V2_crossCheck m51 : 43|1@1+ (1,0) [0|1] "" Vector__XXX
 SG_ DAS_VL_V1_V3_crossCheck m51 : 44|1@1+ (1,0) [0|1] "" Vector__XXX
 SG_ DAS_VL_V1_V4_crossCheck m51 : 45|1@1+ (1,0) [0|1] "" Vector__XXX
 SG_ DAS_VL_V1_V5_crossCheck m51 : 46|1@1+ (1,0) [0|1] "" Vector__XXX
 SG_ DAS_VL_V2_V3_crossCheck m51 : 47|1@1+ (1,0) [0|1] "" Vector__XXX
 SG_ DAS_VL_V2_V4_crossCheck m51 : 48|1@1+ (1,0) [0|1] "" Vector__XXX
 SG_ DAS_VL_V2_V5_crossCheck m51 : 49|1@1+ (1,0) [0|1] "" Vector__XXX
 SG_ DAS_VL_V3_V4_crossCheck m51 : 50|1@1+ (1,0) [0|1] "" Vector__XXX
 SG_ DAS_VL_V3_V5_crossCheck m51 : 51|1@1+ (1,0) [0|1] "" Vector__XXX
 SG_ DAS_VL_V4_V5_crossCheck m51 : 52|1@1+ (1,0) [0|1] "" Vector__XXX
 SG_ DAS_VL_LL_fuse m51 : 53|1@1+ (1,0) [0|1] "" Vector__XXX
 SG_ DAS_VL_RL_fuse m51 : 54|1@1+ (1,0) [0|1] "" Vector__XXX
 SG_ DAS_VL_HPP_fuse m51 : 55|1@1+ (1,0) [0|1] "" Vector__XXX
 SG_ DAS_VL_NAV_fuse m51 : 56|1@1+ (1,0) [0|1] "" Vector__XXX
 SG_ DAS_VL_V1_fuse m51 : 57|1@1+ (1,0) [0|1] "" Vector__XXX
 SG_ DAS_VL_V2_fuse m51 : 58|1@1+ (1,0) [0|1] "" Vector__XXX
 SG_ DAS_VL_V3_fuse m51 : 59|1@1+ (1,0) [0|1] "" Vector__XXX
 SG_ DAS_VL_V4_fuse m51 : 60|1@1+ (1,0) [0|1] "" Vector__XXX
 SG_ DAS_VL_V5_fuse m51 : 61|1@1+ (1,0) [0|1] "" Vector__XXX
 SG_ DAS_VL_egoLaneChange m51 : 62|2@1+ (1,0) [0|2] "" Vector__XXX
 SG_ DAS_VL_exitChecks_EGO_LNE_LEFT m52 : 8|1@1+ (1,0) [0|1] "" Vector__XXX
 SG_ DAS_VL_exitChecks_EGO_LNE_RGHT m52 : 9|1@1+ (1,0) [0|1] "" Vector__XXX
 SG_ DAS_VL_exitChecks_BLINKER_LEFT m52 : 10|1@1+ (1,0) [0|1] "" Vector__XXX
 SG_ DAS_VL_exitChecks_BLINKER_RGHT m52 : 11|1@1+ (1,0) [0|1] "" Vector__XXX
 SG_ DAS_HM_LaneViewRange_ML m60 : 8|8@1+ (1,0) [0|255] "" Vector__XXX
 SG_ DAS_HM_LaneViewRange_ET m60 : 16|16@1+ (1,0) [0|165335] "" Vector__XXX
 SG_ DAS_HM_LaneViewRange_BT m60 : 32|16@1+ (1,0) [0|165335] "" Vector__XXX
 SG_ DAS_HM_LaneViewRange_AL m60 : 48|8@1+ (1,0) [0|255] "" Vector__XXX
 SG_ DAS_HM_LaneViewRange_MS m60 : 56|8@1+ (1,0) [0|255] "" Vector__XXX
 SG_ DAS_HM_VlNoInputs_ML m61 : 8|8@1+ (1,0) [0|255] "" Vector__XXX
 SG_ DAS_HM_VlNoInputs_ET m61 : 16|16@1+ (1,0) [0|165335] "" Vector__XXX
 SG_ DAS_HM_VlNoInputs_BT m61 : 32|16@1+ (1,0) [0|165335] "" Vector__XXX
 SG_ DAS_HM_VlNoInputs_AL m61 : 48|8@1+ (1,0) [0|255] "" Vector__XXX
 SG_ DAS_HM_VlNoInputs_MS m61 : 56|8@1+ (1,0) [0|255] "" Vector__XXX
 SG_ DAS_HM_steeringError_ML m62 : 8|8@1+ (1,0) [0|255] "" Vector__XXX
 SG_ DAS_HM_steeringError_ET m62 : 16|16@1+ (1,0) [0|165335] "" Vector__XXX
 SG_ DAS_HM_steeringError_BT m62 : 32|16@1+ (1,0) [0|165335] "" Vector__XXX
 SG_ DAS_HM_steeringError_AL m62 : 48|8@1+ (1,0) [0|255] "" Vector__XXX
 SG_ DAS_HM_steeringError_MS m62 : 56|8@1+ (1,0) [0|255] "" Vector__XXX
 SG_ DAS_SYNC_EyeQGlobalFrameNum m100 : 15|32@0+ (1,0) [0|4294967296] "" Vector__XXX
 SG_ DAS_SYNC_DASLocalTimeStamp m100 : 47|24@0+ (1,0) [0|16777216] "" Vector__XXX

BO_ 1641 DAS_dtcMatrix: 8 DAS
 SG_ DAS_dtcMultiplex M : 0|8@1+ (1,0) [0|255] "" Vector__XXX
 SG_ DAS_d001_unused m0 : 8|2@1+ (1,0) [0|0] "" Vector__XXX

CM_ SG_ 283 CurrentLevel "ECU height observed.";
CM_ SG_ 1465 DAS_sw019_numFreeBytes "A positive value denotes the number of bytes remaining in the stack before it will overflow. A negative value indicates that the stack has overflown by those many bytes. Any overflow beyond 191 bytes is snapped back and reported as -191 byte overflow.";
CM_ SG_ 1465 DAS_sw019_timeStamp "Time stamp in milliseconds after the ECU health monitor gets initialized.";
CM_ SG_ 1465 DAS_sw027_Clock_Monitor_0_Low "External crystal oscillator, PLL 0 or Internal RC oscillator  under the rated frequency limits.";
CM_ SG_ 1465 DAS_sw027_Clock_Monitor_0_Off "External crystal oscillator, PLL 0 or Internal RC oscillator either over or under the rated frequency limits.";
CM_ SG_ 1465 DAS_sw027_f_PLL_1_Off "PLL 1 frequency over or under allowable limits.";
CM_ SG_ 1465 DAS_sw194_timeInHold "Time in ms since ACC entered HOLD state";
CM_ SG_ 1001 DAS_bodyControlsChecksum "Checksum method for DAS_bodyControls is sum of all bytes in message + originating CAN ID (0x3 + 0xE9) = 0xEC";
CM_ SG_ 697 DAS_accState "State of traffic-aware cruise control (ACC/TACC).";
CM_ SG_ 697 DAS_controlChecksum "Checksum method for DAS_control: sum of all bytes in message + originating CAN ID (0x2 + 0xb9 = 0xbb).";
CM_ SG_ 1824 DAS_SYNC_EyeQGlobalFrameNum "Mobileye global frame number";
CM_ SG_ 1824 DAS_SYNC_DASLocalTimeStamp "DAS time stamp in millisecond";
BA_DEF_  "BusType" STRING ;
BA_DEF_  "DBName" STRING ;
BA_DEF_ SG_  "LogSignal" STRING ;
BA_DEF_ SG_  "GenSigTimeout_PTS" INT 0 65535;
BA_DEF_ SG_  "GenSigTimeout_MPC" INT 0 65535;
BA_DEF_ SG_  "GenSigTimeout_ESP_ABR" INT 0 65535;
BA_DEF_ SG_  "GenSigTimeout_CGW" INT 0 65535;
BA_DEF_ SG_  "GenSigStartValue" INT 0 0;
BA_DEF_ SG_  "GenSigSendType" ENUM  "Cyclic","OnWrite","OnWriteWithRepetition","OnChange","OnChangeWithRepetition","IfActive","IfActiveWithRepetition","NoSigSendType","NotUsed","NotUsed","NotUsed","NotUsed","NotUsed";
BA_DEF_ SG_  "GenSigSNA" STRING ;
BA_DEF_ SG_  "GenSigCycleTimeActive" INT 0 0;
BA_DEF_ SG_  "GenSigCycleTime" INT 0 0;
BA_DEF_ SG_  "FlexKomSigStartValue" STRING ;
BA_DEF_ SG_  "FlexKomSigStartPos" INT 0 63;
BA_DEF_ SG_  "FlexKomSigName" STRING ;
BA_DEF_ SG_  "FlexKomSigLaenge" INT 0 64;
BA_DEF_ SG_  "FlexKomSID" INT 0 2147483647;
BA_DEF_ SG_  "FlexKomIsMotorola" ENUM  "nein","ja";
BA_DEF_ SG_  "FlexKomComment" STRING ;
BA_DEF_ SG_  "FieldType" STRING ;
BA_DEF_ BO_  "UsesChecksum" ENUM  "No","Yes";
BA_DEF_ BO_  "NWMBotschaft" ENUM  "nein","ja";
BA_DEF_ BO_  "MessageIdType" ENUM  "normal","udsRequest","udsResponse","udsReserved","udsFunctionalRequest","networkManagement","bootloader","xcp","dtc","diagnostic","vendorExempt";
BA_DEF_ BO_  "GenMsgTimeOut" INT 0 0;
BA_DEF_ BO_  "GenMsgStartValue" STRING ;
BA_DEF_ BO_  "GenMsgSendType" ENUM  "Cyclic","NotUsed","NotUsed","NotUsed","NotUsed","NotUsed","NotUsed","IfActive","NoMsgSendType","Sporadic";
BA_DEF_ BO_  "GenMsgSaltingFunction" ENUM  "No","Yes";
BA_DEF_ BO_  "GenMsgILSupport" ENUM  "No","Yes";
BA_DEF_ BO_  "GenMsgForceMiaCheck" ENUM  "No","Yes";
BA_DEF_ BO_  "GenMsgDelayTime" INT 0 0;
BA_DEF_ BO_  "GenMsgCycleTimeFast" INT 0 0;
BA_DEF_ BO_  "GenMsgCycleTime" INT 0 0;
BA_DEF_ BO_  "GatewayMessageSendType" ENUM  "UseGenMsgSendType","onWrite","noAutoCode";
BA_DEF_ BO_  "GatewayHandlerEnum" ENUM  "noHandler","uds","alertLog","messageLogOnReception","udsClient";
BA_DEF_ BO_  "ETHId" STRING ;
BA_DEF_ BO_  "DiagResponse" ENUM  "No","Yes";
BA_DEF_ BO_  "DiagRequest" ENUM  "No","Yes";
BA_DEF_ BO_  "AppBotschaft" ENUM  "nein","ja";
BA_DEF_ BO_  "AlertType" INT 0 4;
BA_DEF_ BO_  "AlertLogSubSystemId" INT 0 0;
BA_DEF_DEF_  "BusType" "";
BA_DEF_DEF_  "DBName" "";
BA_DEF_DEF_  "LogSignal" "";
BA_DEF_DEF_  "GenSigTimeout_PTS" 0;
BA_DEF_DEF_  "GenSigTimeout_MPC" 0;
BA_DEF_DEF_  "GenSigTimeout_ESP_ABR" 0;
BA_DEF_DEF_  "GenSigTimeout_CGW" 0;
BA_DEF_DEF_  "GenSigStartValue" 0;
BA_DEF_DEF_  "GenSigSendType" "Cyclic";
BA_DEF_DEF_  "GenSigSNA" "";
BA_DEF_DEF_  "GenSigCycleTimeActive" 0;
BA_DEF_DEF_  "GenSigCycleTime" 0;
BA_DEF_DEF_  "FlexKomSigStartValue" "";
BA_DEF_DEF_  "FlexKomSigStartPos" 0;
BA_DEF_DEF_  "FlexKomSigName" "";
BA_DEF_DEF_  "FlexKomSigLaenge" 0;
BA_DEF_DEF_  "FlexKomSID" 0;
BA_DEF_DEF_  "FlexKomIsMotorola" "";
BA_DEF_DEF_  "FlexKomComment" "";
BA_DEF_DEF_  "FieldType" "";
BA_DEF_DEF_  "UsesChecksum" "No";
BA_DEF_DEF_  "NWMBotschaft" "nein";
BA_DEF_DEF_  "MessageIdType" "normal";
BA_DEF_DEF_  "GenMsgTimeOut" 0;
BA_DEF_DEF_  "GenMsgStartValue" "";
BA_DEF_DEF_  "GenMsgSendType" "Cyclic";
BA_DEF_DEF_  "GenMsgSaltingFunction" "No";
BA_DEF_DEF_  "GenMsgILSupport" "Yes";
BA_DEF_DEF_  "GenMsgForceMiaCheck" "No";
BA_DEF_DEF_  "GenMsgDelayTime" 0;
BA_DEF_DEF_  "GenMsgCycleTimeFast" 0;
BA_DEF_DEF_  "GenMsgCycleTime" 0;
BA_DEF_DEF_  "GatewayMessageSendType" "UseGenMsgSendType";
BA_DEF_DEF_  "GatewayHandlerEnum" "noHandler";
BA_DEF_DEF_  "ETHId" "";
BA_DEF_DEF_  "DiagResponse" "No";
BA_DEF_DEF_  "DiagRequest" "No";
BA_DEF_DEF_  "AppBotschaft" "nein";
BA_DEF_DEF_  "AlertType" 4;
BA_DEF_DEF_  "AlertLogSubSystemId" 0;
BA_ "BusType" "CAN";
BA_ "DBName" "DAS";
BA_ "GenMsgTimeOut" BO_ 283 500;
BA_ "GenMsgDelayTime" BO_ 283 20;
BA_ "GenMsgCycleTimeFast" BO_ 283 100;
BA_ "GenMsgCycleTime" BO_ 283 100;
BA_ "GenMsgCycleTime" BO_ 778 100;
BA_ "GenMsgSendType" BO_ 1465 8;
BA_ "GatewayHandlerEnum" BO_ 1465 2;
BA_ "AlertLogSubSystemId" BO_ 1465 195;
BA_ "GenMsgCycleTime" BO_ 1001 500;
BA_ "GatewayMessageSendType" BO_ 1001 1;
BA_ "GenMsgCycleTime" BO_ 1593 500;
BA_ "GenMsgCycleTime" BO_ 1497 333;
BA_ "GenMsgCycleTime" BO_ 1033 100;
BA_ "GenMsgForceMiaCheck" BO_ 697 1;
BA_ "GenMsgCycleTime" BO_ 697 40;
BA_ "GatewayMessageSendType" BO_ 697 1;
BA_ "GatewayHandlerEnum" BO_ 1529 3;
BA_ "GenMsgCycleTime" BO_ 1641 1000;
BA_ "LogSignal" SG_ 283 CurrentLevel "onChange";
BA_ "GenSigCycleTimeActive" SG_ 283 CurrentLevel 100;
BA_ "GenSigCycleTime" SG_ 283 CurrentLevel 100;
BA_ "GenSigStartValue" SG_ 778 BCFRONT_highBeamLeftStatus 3;
BA_ "GenSigStartValue" SG_ 778 BCFRONT_highBeamRightStatus 3;
BA_ "GenSigStartValue" SG_ 778 RLS_humidity 255;
BA_ "GenSigStartValue" SG_ 778 RLS_windowTemperature 255;
BA_ "FieldType" SG_ 778 BCFDM_exteriorReleaseStatus "exteriorReleaseStatus";
BA_ "FieldType" SG_ 778 BCFPM_exteriorReleaseStatus "exteriorReleaseStatus";
BA_ "FieldType" SG_ 778 BCRDM_exteriorReleaseStatus "exteriorReleaseStatus";
BA_ "FieldType" SG_ 778 BCRPM_exteriorReleaseStatus "exteriorReleaseStatus";
BA_ "FieldType" SG_ 1465 DAS_alertID "DAS_alertID";
BA_ "GenSigStartValue" SG_ 1465 DAS_sw018_maxThreshold 50;
BA_ "GenSigStartValue" SG_ 1465 DAS_sw019_numFreeBytes 191;
BA_ "FieldType" SG_ 1465 DAS_sw024_currentVehicleApp "DAS_vehicleApp";
BA_ "FieldType" SG_ 1465 DAS_sw060_collisionWarningSource "FCM_collisionWarningSource";
BA_ "GenSigStartValue" SG_ 1465 DAS_sw062_HorizontalMisalignment 32767.3084204701;
BA_ "GenSigStartValue" SG_ 1465 DAS_sw062_VerticalMisalignment 511.497323164009;
BA_ "FieldType" SG_ 1465 DAS_sw073_escalateLDWreason "LC_escalateLDWreason";
BA_ "FieldType" SG_ 1465 DAS_sw207_lcUnavailableReason "LC_unavailableReason";
BA_ "LogSignal" SG_ 1001 DAS_headlightRequest "onChange";
BA_ "FieldType" SG_ 1001 DAS_headlightRequest "DAS_headlightRequest";
BA_ "GenSigSNA" SG_ 1001 DAS_hazardLightRequest "3";
BA_ "FieldType" SG_ 1001 DAS_hazardLightRequest "DAS_hazardLightRequest";
BA_ "LogSignal" SG_ 1001 DAS_wiperSpeed "onChange";
BA_ "FieldType" SG_ 1001 DAS_wiperSpeed "DAS_wiperSpeed";
BA_ "FieldType" SG_ 1001 DAS_turnIndicatorRequest "DAS_turnIndicatorRequest";
BA_ "LogSignal" SG_ 1001 DAS_highLowBeamDecision "onChange";
BA_ "FieldType" SG_ 1001 DAS_highLowBeamDecision "DAS_highLowBeamDecision";
BA_ "LogSignal" SG_ 1497 DAS_radarTarget5_dx "periodic ONE_SECOND driveModeModelS";
BA_ "LogSignal" SG_ 1497 DAS_radarTarget1_dx "periodic ONE_SECOND driveModeModelS";
BA_ "LogSignal" SG_ 1497 DAS_radarTarget1_VxRel "periodic ONE_SECOND driveModeModelS";
BA_ "LogSignal" SG_ 1497 DAS_mobileyeVehAebFlag "onChange";
BA_ "LogSignal" SG_ 1497 DAS_mobileyePedAebFlag "onChange";
BA_ "LogSignal" SG_ 1497 DAS_mobileyeIPSOapproved "onChange";
BA_ "LogSignal" SG_ 1497 DAS_fcmSteeringOverride "onChange";
BA_ "LogSignal" SG_ 1497 DAS_fcmCollisionStage3Checks "onChange";
BA_ "LogSignal" SG_ 1497 DAS_fcmThreatAssesmentMode "onChange";
BA_ "LogSignal" SG_ 1497 DAS_constructionArea "onChange";
BA_ "LogSignal" SG_ 1497 DAS_associated_rad_object "onChange";
BA_ "LogSignal" SG_ 1497 DAS_LC_handsOnReason "onChange";
BA_ "FieldType" SG_ 1497 DAS_LC_handsOnReason "LC_handsOnReason";
BA_ "LogSignal" SG_ 1497 DAS_ACC_camStatus "onChange";
BA_ "FieldType" SG_ 1497 DAS_ACC_camStatus "ACC_camStatus";
BA_ "LogSignal" SG_ 1497 DAS_virtualLaneMaxPeriod "periodic ONE_SECOND driveModeModelS";
BA_ "LogSignal" SG_ 1497 DAS_virtualLaneMaxDuration "periodic ONE_SECOND driveModeModelS";
BA_ "LogSignal" SG_ 1497 DAS_radarTarget2_dx "periodic ONE_SECOND driveModeModelS";
BA_ "LogSignal" SG_ 1497 DAS_radarTarget3_dx "periodic ONE_SECOND driveModeModelS";
BA_ "LogSignal" SG_ 1497 DAS_radarTarget4_dx "periodic ONE_SECOND driveModeModelS";
BA_ "FieldType" SG_ 1033 DAS_nmKeepAwakeReason "DAS_NM_keepAwakeReason";
BA_ "LogSignal" SG_ 697 DAS_setSpeed "periodic ONE_SECOND driveModeModelS";
BA_ "GenSigStartValue" SG_ 697 DAS_setSpeed 4095;
BA_ "LogSignal" SG_ 697 DAS_accState "onChange";
BA_ "LogSignal" SG_ 697 DAS_jerkMin "periodic ONE_SECOND driveModeModelS";
BA_ "GenSigStartValue" SG_ 697 DAS_jerkMin 511;
BA_ "LogSignal" SG_ 697 DAS_jerkMax "periodic ONE_SECOND driveModeModelS";
BA_ "GenSigStartValue" SG_ 697 DAS_jerkMax 255;
BA_ "LogSignal" SG_ 697 DAS_accelMin "periodic ONE_SECOND driveModeModelS";
BA_ "GenSigStartValue" SG_ 697 DAS_accelMin 511;
BA_ "LogSignal" SG_ 697 DAS_accelMax "periodic ONE_SECOND driveModeModelS";
BA_ "GenSigStartValue" SG_ 697 DAS_accelMax 511;
BA_ "FieldType" SG_ 1529 DAS_logMltplxr "DAS_logMltplxr";
BA_ "FieldType" SG_ 1529 DAS_fcmReasonToOverride "FCM_OVERRIDE";
BA_ "GenSigStartValue" SG_ 1824 DAS_PF_Navigation_STW 4096;
BA_ "GenSigStartValue" SG_ 1824 DAS_PF_VirtualLane_STW 4096;
VAL_ 283 CurrentLevel 6 "VERY_HIGH_LEVEL" 5 "HIGH_LEVEL" 4 "NORMAL_LEVEL" 3 "LOW_LEVEL" ;
VAL_ 778 BCCEN_wiperSpeed 8 "WIPER_SPEED_SNA" 7 "WIPER_SPEED_HIGH" 6 "WIPER_SPEED_LOW" 5 "WIPER_SPEED_5" 4 "WIPER_SPEED_4" 3 "WIPER_SPEED_3" 2 "WIPER_SPEED_2" 1 "WIPER_SPEED_1" 0 "WIPER_SPEED_OFF" ;
VAL_ 778 BCFRONT_highBeamLeftStatus 3 "LIGHT_SNA" 2 "LIGHT_FAULT" 1 "LIGHT_ON" 0 "LIGHT_OFF" ;
VAL_ 778 BCFRONT_highBeamRightStatus 3 "LIGHT_SNA" 2 "LIGHT_FAULT" 1 "LIGHT_ON" 0 "LIGHT_OFF" ;
VAL_ 778 RLS_active 1 "RLS_ACTIVE" 0 "RLS_INACTIVE" ;
VAL_ 778 RLS_humidity 255 "SNA" ;
VAL_ 778 RLS_windowTemperature 255 "SNA" ;
VAL_ 778 BCFDM_exteriorReleaseStatus 3 "EXTERIOR_RELEASE_SNA" 2 "EXTERIOR_RELEASE_FAULT" 1 "EXTERIOR_RELEASE_PRESSED" 0 "EXTERIOR_RELEASE_NOT_PRESSED" ;
VAL_ 778 BCFPM_exteriorReleaseStatus 3 "EXTERIOR_RELEASE_SNA" 2 "EXTERIOR_RELEASE_FAULT" 1 "EXTERIOR_RELEASE_PRESSED" 0 "EXTERIOR_RELEASE_NOT_PRESSED" ;
VAL_ 778 BCRDM_exteriorReleaseStatus 3 "EXTERIOR_RELEASE_SNA" 2 "EXTERIOR_RELEASE_FAULT" 1 "EXTERIOR_RELEASE_PRESSED" 0 "EXTERIOR_RELEASE_NOT_PRESSED" ;
VAL_ 778 BCRPM_exteriorReleaseStatus 3 "EXTERIOR_RELEASE_SNA" 2 "EXTERIOR_RELEASE_FAULT" 1 "EXTERIOR_RELEASE_PRESSED" 0 "EXTERIOR_RELEASE_NOT_PRESSED" ;
VAL_ 778 BCCEN_keyfobSummonRequest 3 "KEYFOB_SUMMON_REQUEST_REVERSE" 2 "KEYFOB_SUMMON_REQUEST_FORWARD" 1 "KEYFOB_SUMMON_REQUEST_PRIME" 0 "KEYFOB_SUMMON_REQUEST_IDLE" ;
VAL_ 1465 DAS_alertID 226 "DAS_w226_lcCamCalNeededSpeedLmt" 225 "DAS_w225_lcDegradedVisSpeedLmt" 224 "DAS_w224_accCameraCalibration" 223 "DAS_w223_accObjectInPath" 222 "DAS_w222_accCameraBlind" 221 "DAS_w221_accRadarBlind" 220 "DAS_w220_lcTempUnavailableRoad" 219 "DAS_w219_lcTempUnavailableSpeed" 218 "DAS_w218_lcSpeedExceededLimit" 217 "DAS_w217_lcUnavailableSpeeding" 216 "DAS_w216_driverOverriding" 215 "DAS_w215_contDriverNotIntracting" 214 "DAS_w214_driverNotIntracting" 213 "DAS_w213_autosteerStruckOut" 212 "DAS_w212_lcUnavailableStrikeOut" 211 "DAS_w211_accNoSeatBelt" 210 "DAS_w210_camObstrcted" 209 "DAS_w209_autoSummonRequest" 208 "DAS_w208_rackDetected" 207 "DAS_w207_autosteerUnavailable" 206 "DAS_w206_autosteerNotEnabled" 205 "DAS_w205_apcFinalRear" 204 "DAS_w204_apcFinalFront" 203 "DAS_w203_apcActivation" 202 "DAS_w202_scwNoisyEnvironment" 201 "DAS_w201_lcAborting" 200 "DAS_w200_lcSlowdown" 199 "DAS_w199_apcAbort" 198 "DAS_w198_tsrUnavailable" 197 "DAS_w197_redLightWarning" 196 "DAS_w196_stopSignWarning" 195 "DAS_w195_scwUnavailable" 194 "DAS_w194_accDriverResumeRqrd" 193 "DAS_w193_camWindshieldUnclean" 106 "DAS_w106_torsionBarCalibrated" 103 "DAS_w103_robExperimentalAEB" 86 "DAS_w086_robCollision" 85 "DAS_w085_pmmSteering" 84 "DAS_w084_pmmIPSO" 83 "DAS_w083_inPathRADObject" 82 "DAS_w082_inPathFSviolation" 81 "DAS_w081_pmmActiveBraking" 80 "DAS_w080_accFailedActivation" 79 "DAS_w079_edrAvailable" 78 "DAS_w078_pmmActive2" 77 "DAS_w077_pmmActive" 76 "DAS_w076_mobilEyeSetC" 75 "DAS_w075_scMia" 74 "DAS_w074_inPathStationaryObst" 73 "DAS_w073_issueEscalatedLDW" 72 "DAS_w072_selfparkComplete" 71 "DAS_w071_selfparkStarted" 70 "DAS_w070_apcIncompleteCal" 69 "DAS_w069_apcSpaceMasked" 68 "DAS_w068_vlInconsistency" 67 "DAS_w067_steeringAlignment" 66 "DAS_w066_deserializerLockLost" 65 "DAS_w065_deserializerOvercurrent" 64 "DAS_w064_epasMia" 63 "DAS_w063_parkVersionMismatch" 62 "DAS_w062_radcAlignment" 61 "DAS_w061_airSuspensionMia" 60 "DAS_w060_fcw_event" 59 "DAS_w059_parkMia" 58 "DAS_w058_epbMia" 57 "DAS_w057_mcuMia" 56 "DAS_w056_diMia" 55 "DAS_w055_radcVersionMismatch" 54 "DAS_w054_camAutofix" 53 "DAS_w053_radcCommIssue" 52 "DAS_w052_radcSensorIssue" 51 "DAS_w051_radcEcuIssue" 50 "DAS_w050_aeb_event" 49 "DAS_w049_eyeqVersionMismatch" 48 "DAS_w048_DAS_Features_Disabled" 47 "DAS_w047_edrEvent" 46 "DAS_w046_eepromRecordAbsent" 45 "DAS_w045_radMia" 44 "DAS_w044_appMobileyeFailure" 43 "DAS_w043_camLongRunTime" 42 "DAS_w042_autopilotAborting" 41 "DAS_w041_autopilotRateSaturated" 40 "DAS_w040_autopilotAngleSaturated" 39 "DAS_w039_sdm_rcm_Mia" 38 "DAS_w038_camFailure" 37 "DAS_w037_camTacIssue" 36 "DAS_w036_bdyMia" 35 "DAS_w035_espMia" 34 "DAS_w034_sccmMia" 33 "DAS_w033_gtwMia" 32 "DAS_w032_canTxError" 31 "DAS_w031_canRxError" 30 "DAS_w030_Heater_Issue" 29 "DAS_w029_spi_tx_error" 28 "DAS_w028_spi_rx_error" 27 "DAS_w027_ECU_Reset_Fault" 26 "DAS_w026_ECU_timingIssue" 25 "DAS_w025_LC_Steering_Override" 24 "DAS_w024_ECU_Watchdog_Reset" 23 "DAS_w023_ECU_Cam_Statemismatch" 22 "DAS_w022_ECU_EEPROM_Failure" 21 "DAS_w021_ECU_Temperature_Issue" 20 "DAS_w020_ECU_checkstopError" 19 "DAS_w019_ECU_Stack_Overflow" 18 "DAS_w018_ECU_Power_Issue" 17 "DAS_w017_Cam_Msg_MIA" 16 "DAS_w016_aeb_e_event" 15 "DAS_w015_Camera_Failsafes" 14 "DAS_w014_swAssert" 13 "DAS_w013_Cam_Watchdog" 12 "DAS_w012_Cam_BootFailure" 11 "DAS_w011_scaEvent" 10 "DAS_w010_radcCalibIssue" 9 "DAS_w009_aebFault" 8 "DAS_w008_parkDisabled" 7 "DAS_w007_ahlbDisabled" 6 "DAS_w006_aebCancelled" 5 "DAS_w005_fcwCancelled" 4 "DAS_w004_accDisabled" 3 "DAS_w003_isaDisabled" 2 "DAS_w002_ldwDisabled" 0 "DAS_w000_reserved" ;
VAL_ 1465 DAS_sw004_accState 9 "Cancel for Object in Path" 8 "Fault" 7 "Cancel for Radar Blindness" 6 "Cancel for Camera Blindness" 5 "Cancel Generic" 4 "Ready to Resume" 3 "Hold" 2 "Standstill" 1 "Active" 0 "Idle" ;
VAL_ 1465 DAS_sw004_appMobileyeStatus 24 "MOBILEYE_STATUS_UNDEFINED" 23 "MOBILEYE_STATUS_TEARDOWN_FLASH_ACCESS_MODE" 22 "MOBILEYE_STATUS_FLASH_READ_MODE" 21 "MOBILEYE_STATUS_SETUP_FLASH_ACCESS_MODE" 20 "MOBILEYE_STATUS_RUNNING_SPTAC_MODE" 19 "MOBILEYE_STATUS_SPTAC_INIT_SENT" 18 "MOBILEYE_STATUS_WAITING_FOR_SPTAC_INIT" 17 "MOBILEYE_STATUS_BURN_EDR_MODE" 16 "MOBILEYE_STATUS_SPC_INIT_SENT" 15 "MOBILEYE_STATUS_WAITING_FOR_SPC_INIT" 14 "MOBILEYE_STATUS_ERROR" 13 "MOBILEYE_STATUS_LATCHING_FAILURE" 12 "MOBILEYE_STATUS_UPDATING" 11 "MOBILEYE_STATUS_RUNNING_DV_MODE" 10 "MOBILEYE_STATUS_WAITING_FOR_DV" 9 "MOBILEYE_STATUS_RUNNING_TAC_MODE" 8 "MOBILEYE_STATUS_RUNNING_SPC_MODE" 7 "MOBILEYE_STATUS_RUNNING_VISION_MODE" 6 "MOBILEYE_STATUS_TAC_INIT_SENT" 5 "MOBILEYE_STATUS_WAITING_FOR_TAC_INIT" 4 "MOBILEYE_STATUS_VISION_INIT_SENT" 3 "MOBILEYE_STATUS_WAITING_FOR_VISION_INIT" 2 "MOBILEYE_STATUS_WAITING_FOR_BOOT" 1 "MOBILEYE_STATUS_POWER_OFF" 0 "MOBILEYE_STATUS_POWER_CYCLE" ;
VAL_ 1465 DAS_sw006_timeOfDay 2 "TIME_DUSK" 1 "TIME_NIGHT" 0 "TIME_DAY" ;
VAL_ 1465 DAS_sw010_a04calibNotDone 1 "True" 0 "False" ;
VAL_ 1465 DAS_sw010_a05calibReqd 1 "True" 0 "False" ;
VAL_ 1465 DAS_sw010_a06calibNotOK 1 "True" 0 "False" ;
VAL_ 1465 DAS_sw010_a08PlantMode 1 "True" 0 "False" ;
VAL_ 1465 DAS_sw011_scaState 4 "FAULT" 3 "AVOIDANCE" 2 "AVAILABLE" 1 "UNAVAILABLE" 0 "DISABLED" ;
VAL_ 1465 DAS_sw012_bootDDRTempStatus 3 "SDRAM high temperature" 2 "temperature grater than 85 C" 1 "temperature less or equal to 85 C" 0 "SDRAM low temperatue" ;
VAL_ 1465 DAS_sw012_mespDDRTempStatus 7 "Temperature error" 3 "Temperature above 85" 2 "Termperature above spec" 1 "Temperature below spec" 0 "Temperature ok" ;
VAL_ 1465 DAS_sw013_stateBeforeWatchdog 24 "MOBILEYE_STATUS_UNDEFINED" 23 "MOBILEYE_STATUS_TEARDOWN_FLASH_ACCESS_MODE" 22 "MOBILEYE_STATUS_FLASH_READ_MODE" 21 "MOBILEYE_STATUS_SETUP_FLASH_ACCESS_MODE" 20 "MOBILEYE_STATUS_RUNNING_SPTAC_MODE" 19 "MOBILEYE_STATUS_SPTAC_INIT_SENT" 18 "MOBILEYE_STATUS_WAITING_FOR_SPTAC_INIT" 17 "MOBILEYE_STATUS_BURN_EDR_MODE" 16 "MOBILEYE_STATUS_SPC_INIT_SENT" 15 "MOBILEYE_STATUS_WAITING_FOR_SPC_INIT" 14 "MOBILEYE_STATUS_ERROR" 13 "MOBILEYE_STATUS_LATCHING_FAILURE" 12 "MOBILEYE_STATUS_UPDATING" 11 "MOBILEYE_STATUS_RUNNING_DV_MODE" 10 "MOBILEYE_STATUS_WAITING_FOR_DV" 9 "MOBILEYE_STATUS_RUNNING_TAC_MODE" 8 "MOBILEYE_STATUS_RUNNING_SPC_MODE" 7 "MOBILEYE_STATUS_RUNNING_VISION_MODE" 6 "MOBILEYE_STATUS_TAC_INIT_SENT" 5 "MOBILEYE_STATUS_WAITING_FOR_TAC_INIT" 4 "MOBILEYE_STATUS_VISION_INIT_SENT" 3 "MOBILEYE_STATUS_WAITING_FOR_VISION_INIT" 2 "MOBILEYE_STATUS_WAITING_FOR_BOOT" 1 "MOBILEYE_STATUS_POWER_OFF" 0 "MOBILEYE_STATUS_POWER_CYCLE" ;
VAL_ 1465 DAS_sw014_fileNameHash 32617 "HW_GPIO_PAD.c" 32602 "UDS_FlowControl.c" 32601 "ACC_compute.c" 32576 "app_CAN.c" 32563 "IO_RGM.c" 32315 "IQmath.c" 32314 "HW_CGM.c" 32299 "HW_RGM.c" 32074 "trajectory_planner_main.c" 32054 "HW_ADC.c" 32006 "NVM_Manager_component_specific.c" 31862 "IO_queue_component_specific.c" 31831 "fixquat.c" 31790 "IO_ADC.c" 31784 "UDS_TP.c" 31764 "lib_UDS_EEPROM.c" 31604 "HW_GPIO_pad_definitions.c" 31348 "app_mobileye_version_matrix.c" 31343 "HW_ECSM.c" 31291 "UDS_RC.c" 31247 "fixvector2d.c" 31246 "fixvector3d.c" 31032 "IO_radar_alert.c" 31009 "IO_CAN.c" 30055 "UDS_TRD.c" 29810 "app_tsr.c" 29797 "IO_watchdog.c" 29787 "SCA_monitor.c" 29561 "UDS_ctrlDTC.c" 29531 "IO_Mobileye.c" 29280 "AlertManagerCfg.c" 29243 "Interpolate_IQ15.c" 29033 "app_ahb.c" 29024 "UDS_readDTC.c" 28726 "HW_LIN.c" 28722 "HW_SIU.c" 28720 "HW_PIT.c" 28519 "IO_PWMInput.c" 28465 "IO_PWM.c" 28459 "IO_SWT.c" 28211 "HW_SWT.c" 28197 "HW_DAS_SIU.c" 27947 "HW_OTP.c" 27946 "HW_STM.c" 27914 "util_queue.c" 27750 "IO_mutex_component_specific.c" 27699 "IO_OTP.c" 27516 "IO_CAN_data.c" 27451 "UDS_CC.c" 27444 "HW_CRC.c" 27262 "HW_WKPU.c" 27233 "app_vehicle.c" 27179 "HW_MSR.c" 26995 "xcp_par.c" 26981 "app_ldw.c" 26926 "HW_SPI.c" 26232 "ACC_speed_limit.c" 25952 "das_app.c" 25866 "RTOS_interrupt.c" 25713 "ACC_fleet_speed.c" 25691 "ACC_monitor.c" 25190 "UDS_DSC.c" 25164 "road_furniture_main.c" 25154 "app_ECU.c" 24957 "CSA.c" 24907 "lib_HSD.c" 24678 "IO_UART.c" 24636 "HW_RGM_DAS.c" 24145 "fix16_exp.c" 23589 "app_mobileye_country_codes.c" 22573 "utils_math.c" 22548 "IO_Vehicle.c" 22364 "util_codeDescriptor_ghs.c" 22082 "NVM_Manager.c" 21614 "LC_calculate_health.c" 21599 "watchdog_manager_component_specific.c" 21595 "FCM_self_evaluation.c" 21295 "app_heater.c" 21266 "IO_Environment.c" 21063 "lib_mobileye_mesp_utils.c" 20331 "util_ringBuffer.c" 20237 "UDS_SecurityAccess.c" 19731 "LC_follow_path.c" 19318 "fix16.c" 19037 "fix16_str.c" 18253 "Interpolate.c" 17980 "HW_interrupt_componentSpecific.c" 17972 "UDS_SendSM.c" 17933 "IO_quadDecoder.c" 17433 "util_crc_j1850.c" 17419 "UDS_RQ_ULDL_common.c" 17259 "util_codeDescriptor.c" 17168 "ACC_filter.c" 17016 "lib_mobileye_mesp_basic_service.c" 16910 "ACC_output.c" 16194 "UDS_SIDs.c" 16151 "IO_ECU_component_specific.c" 15973 "UDS_RQDL.c" 15965 "app_mobileye_EDR.c" 15928 "UDS_Processor.c" 15733 "UDS_WDBI.c" 15732 "UDS_WMBA.c" 15721 "profiler.c" 15678 "task_mobileye.c" 15616 "lib_mobileye_mesp.c" 15378 "HW_CAN_component_specific.c" 15375 "lib_NVRAM.c" 15211 "HW_EMIOS.c" 15197 "app_mobileye_TAC.c" 15181 "app_watchdog.c" 15121 "lib_mobileye_mesp_calibration_service.c" 14931 "lib_mobileye.c" 14684 "lib_math.c" 14453 "UDS_RDBI.c" 14452 "UDS_RMBA.c" 14448 "SCA_main.c" 14446 "UDS_ECUReset.c" 14425 "IO_reset.c" 14206 "PMM_main.c" 14185 "rijndael.c" 14180 "task_CAN.c" 14118 "util_counters.c" 13912 "utils_DAS_assert.c" 13572 "virtual_wall_main.c" 13383 "IO_timer.c" 13130 "app_vehicle_driving_side.c" 12911 "task_UDS.c" 12645 "IO_Failsafes.c" 12596 "HW_ME.c" 12339 "LC_hands_on_detection.c" 12133 "UDS_RQUL.c" 12091 "IO_EEPROM.c" 11884 "UDS_RQTE.c" 11877 "world_model_main.c" 11811 "HW_EEPROM.c" 11615 "lib_mobileye_mesp_frame_data_service.c" 11568 "RTOS_time.c" 11525 "HW_SPI_component_specific.c" 11277 "virtual_lane_main.c" 11132 "CalcFilt.c" 11089 "lateral_control_angle_tables.c" 10860 "main.c" 10840 "LC_telemetry.c" 10530 "ACC_target_assessment.c" 10524 "app_system_health.c" 10352 "ACC_main.c" 10339 "APC_main.c" 10317 "IO_mutex.c" 10007 "IO_digOut.c" 10004 "lib_mobileye_mesp_edr_service.c" 9784 "UDS_IOCBI.c" 9750 "HW_LIN_processor_specific.c" 9729 "IO_board_test.c" 9546 "app_mobileye.c" 9257 "FCM_threat_assessment.c" 9082 "lib_mobileye_mesp_camera_service.c" 9056 "fixarray.c" 8801 "UDS_ECU_shim.c" 8716 "fract32.c" 8560 "FCM_main.c" 8537 "IO_MobileyeFlash.c" 8493 "UDS_ECU_Hooks.c" 8310 "util_bitManipulation.c" 8286 "IO_MobileyeFlashTestStub.c" 8274 "UDS_MasterSM.c" 8000 "AlertMap.c" 7969 "fixkalman.c" 7477 "TSR_telemetry.c" 7434 "FCM_state_machine.c" 7252 "HW_CAN_processorSpecific.c" 7223 "_xcp_appl.c" 7025 "fix16_trig.c" 6987 "AlertManager.c" 6941 "utils_ttc.c" 6209 "IO_digIn.c" 5924 "tasks.c" 5745 "task_vehicle.c" 5687 "fixmatrix.c" 5677 "IO_Heater.c" 5479 "UDS_ECU_Services.c" 5392 "UDS_ReceiveSM.c" 5158 "LC_health_monitor.c" 5145 "APC_state_machine.c" 5130 "ACC_state_machine.c" 4970 "Selfpark.c" 4950 "AlertManagerHeaderConfig.c" 4656 "SCA_angle.c" 4212 "watchdog_manager.c" 3931 "lib_IQ28QorivvaMathLib.c" 3666 "XcpBasic.c" 3145 "util_CRC32.c" 3113 "ACC_input.c" 2934 "ACC_target_selection.c" 2878 "HW_I2C.c" 2640 "app_mobileye_spi.c" 2632 "IO_ADC_componentSpecific.c" 2598 "IO_I2C.c" 2162 "UDS_clearDTC.c" 1889 "fix16_sqrt.c" 1612 "uint32.c" 1564 "IO_CAN_alerts.c" 1365 "LC_state_machine.c" 1151 "IO_EEPROM_component_specific.c" 1034 "SCA_state_machine.c" 605 "HW_EEPROM_common.c" 297 "CanReceiver_Generated.c" 48 "IO_edgeDetect.c" ;
VAL_ 1465 DAS_sw015_RadarLowVisibility 3 "True_High_Severity" 2 "True_Medium_Severity" 1 "True_Low_Severity" 0 "False" ;
VAL_ 1465 DAS_sw015_RadarMisalignment 3 "True_High_Severity" 2 "True_Medium_Severity" 1 "True_Low_Severity" 0 "False" ;
VAL_ 1465 DAS_sw015_LowSun 3 "True_High_Severity" 2 "True_Medium_Severity" 1 "True_Low_Severity" 0 "False" ;
VAL_ 1465 DAS_sw015_BlurredImage 3 "True_High_Severity" 2 "True_Medium_Severity" 1 "True_Low_Severity" 0 "False" ;
VAL_ 1465 DAS_sw015_FullBlockage 3 "True_High_Severity" 2 "True_Medium_Severity" 1 "True_Low_Severity" 0 "False" ;
VAL_ 1465 DAS_sw015_PartialBlockage 3 "True_High_Severity" 2 "True_Medium_Severity" 1 "True_Low_Severity" 0 "False" ;
VAL_ 1465 DAS_sw015_AutofixOutOfCalib 3 "True_High_Severity" 2 "True_Medium_Severity" 1 "True_Low_Severity" 0 "False" ;
VAL_ 1465 DAS_sw015_AutofixOutOfCalibYaw 3 "True_High_Severity" 2 "True_Medium_Severity" 1 "True_Low_Severity" 0 "False" ;
VAL_ 1465 DAS_sw015_AutofixOOfCalibHorizon 3 "True_High_Severity" 2 "True_Medium_Severity" 1 "True_Low_Severity" 0 "False" ;
VAL_ 1465 DAS_sw015_Splashes 3 "True_High_Severity" 2 "True_Medium_Severity" 1 "True_Low_Severity" 0 "False" ;
VAL_ 1465 DAS_sw015_SmearedSpots 3 "True_High_Severity" 2 "True_Medium_Severity" 1 "True_Low_Severity" 0 "False" ;
VAL_ 1465 DAS_sw015_SmearedHalos 3 "True_High_Severity" 2 "True_Medium_Severity" 1 "True_Low_Severity" 0 "False" ;
VAL_ 1465 DAS_sw015_FoggyLights 3 "True_High_Severity" 2 "True_Medium_Severity" 1 "True_Low_Severity" 0 "False" ;
VAL_ 1465 DAS_sw015_SunRay 3 "True_High_Severity" 2 "True_Medium_Severity" 1 "True_Low_Severity" 0 "False" ;
VAL_ 1465 DAS_sw015_ImpairedVD 3 "True_High_Severity" 2 "True_Medium_Severity" 1 "True_Low_Severity" 0 "False" ;
VAL_ 1465 DAS_sw015_SelfGlare 3 "True_High_Severity" 2 "True_Medium_Severity" 1 "True_Low_Severity" 0 "False" ;
VAL_ 1465 DAS_sw015_OutOfFocusImage 3 "True_High_Severity" 2 "True_Medium_Severity" 1 "True_Low_Severity" 0 "False" ;
VAL_ 1465 DAS_sw015_MainCameraLowLight 3 "True_High_Severity" 2 "True_Medium_Severity" 1 "True_Low_Severity" 0 "False" ;
VAL_ 1465 DAS_sw015_NarrowCameraLowLight 3 "True_High_Severity" 2 "True_Medium_Severity" 1 "True_Low_Severity" 0 "False" ;
VAL_ 1465 DAS_sw015_MainCameraBadAssoc 3 "True_High_Severity" 2 "True_Medium_Severity" 1 "True_Low_Severity" 0 "False" ;
VAL_ 1465 DAS_sw015_NarrowCameraBadAssoc 3 "True_High_Severity" 2 "True_Medium_Severity" 1 "True_Low_Severity" 0 "False" ;
VAL_ 1465 DAS_sw017_Camera_Msg_Lanes_MIA 1 "True" 0 "False" ;
VAL_ 1465 DAS_sw017_Camera_Msg_Objects_MIA 1 "True" 0 "False" ;
VAL_ 1465 DAS_sw017_Camera_Msg_Tsr_MIA 1 "True" 0 "False" ;
VAL_ 1465 DAS_sw017_Camera_Msg_Hlb_MIA 1 "True" 0 "False" ;
VAL_ 1465 DAS_sw017_Camera_Msg_Common_MIA 1 "True" 0 "False" ;
VAL_ 1465 DAS_sw017_Camera_Msg_FCW_PCW_MIA 1 "True" 0 "False" ;
VAL_ 1465 DAS_sw017_Camera_Msg_TFL_MIA 1 "True" 0 "False" ;
VAL_ 1465 DAS_sw017_Any_Lanes_Msg_Recd 1 "True" 0 "False" ;
VAL_ 1465 DAS_sw017_Any_Objects_Msg_Recd 1 "True" 0 "False" ;
VAL_ 1465 DAS_sw017_Any_TFL_Msg_Recd 1 "True" 0 "False" ;
VAL_ 1465 DAS_sw017_Any_Tsr_Msg_Recd 1 "True" 0 "False" ;
VAL_ 1465 DAS_sw017_Any_Hlb_Msg_Recd 1 "True" 0 "False" ;
VAL_ 1465 DAS_sw017_Any_Common_Msg_Recd 1 "True" 0 "False" ;
VAL_ 1465 DAS_sw017_Any_FCW_PCW_Msg_Recd 1 "True" 0 "False" ;
VAL_ 1465 DAS_sw018_railID 3 "1v2_rail" 2 "1v8_rail" 1 "3v3_rail" 0 "5v0_rail" ;
VAL_ 1465 DAS_sw018_powerSequnceError 1 "True" 0 "False" ;
VAL_ 1465 DAS_sw018_railControl 1 "RAIL_ENABLED" 0 "RAIL_DISABLED" ;
VAL_ 1465 DAS_sw021_tempSensorId 4 "DDR_TEMP_SENSOR" 3 "CAMERA_TEMP_SENSOR" 2 "EYE_Q_TEMP_SENSOR_1" 1 "EYE_Q_TEMP_SENSOR_0" 0 "EXTERNAL_TEMP_SENSOR" ;
VAL_ 1465 DAS_sw022_operation 4 "Erase All" 3 "Delete" 2 "Read" 1 "Write" 0 "Initialize" ;
VAL_ 1465 DAS_sw024_currentVehicleApp 160 "DAS_VA_VL_PROFILER" 159 "DAS_VA_VL_GM_VEH_EXIT" 158 "DAS_VA_VL_GM_MISC_END_VEH_ID5" 157 "DAS_VA_VL_GM_MISC_END_VEH_ID4" 156 "DAS_VA_VL_GM_MISC_END_VEH_ID3" 155 "DAS_VA_VL_GM_MISC_END_VEH_ID2" 154 "DAS_VA_VL_GM_MISC_END_VEH_ID1" 153 "DAS_VA_VL_GM_MISC_END_VEH_ID0" 152 "DAS_VA_VL_GM_HEADING_VEH_ID5" 151 "DAS_VA_VL_GM_HEADING_VEH_ID4" 150 "DAS_VA_VL_GM_HEADING_VEH_ID3" 149 "DAS_VA_VL_GM_HEADING_VEH_ID2" 148 "DAS_VA_VL_GM_HEADING_VEH_ID1" 147 "DAS_VA_VL_GM_HEADING_VEH_ID0" 146 "DAS_VA_VL_GM_NODP_LONG_VEH_ID5" 145 "DAS_VA_VL_GM_NODP_LONG_VEH_ID4" 144 "DAS_VA_VL_GM_NODP_LONG_VEH_ID3" 143 "DAS_VA_VL_GM_NODP_LONG_VEH_ID2" 142 "DAS_VA_VL_GM_NODP_LONG_VEH_ID1" 141 "DAS_VA_VL_GM_NODP_LONG_VEH_ID0" 140 "DAS_VA_VL_GM_NODP_LAT_VEH_ID5" 139 "DAS_VA_VL_GM_NODP_LAT_VEH_ID4" 138 "DAS_VA_VL_GM_NODP_LAT_VEH_ID3" 137 "DAS_VA_VL_GM_NODP_LAT_VEH_ID2" 136 "DAS_VA_VL_GM_NODP_LAT_VEH_ID1" 135 "DAS_VA_VL_GM_NODP_LAT_VEH_ID0" 134 "DAS_VA_VL_GM_NODP_FUSE_VEH_ID5" 133 "DAS_VA_VL_GM_NODP_FUSE_VEH_ID4" 132 "DAS_VA_VL_GM_NODP_FUSE_VEH_ID3" 131 "DAS_VA_VL_GM_NODP_FUSE_VEH_ID2" 130 "DAS_VA_VL_GM_NODP_FUSE_VEH_ID1" 129 "DAS_VA_VL_GM_NODP_FUSE_VEH_ID0" 128 "DAS_VA_VL_GM_DP_FUSE_VEH_ID5" 127 "DAS_VA_VL_GM_DP_FUSE_VEH_ID4" 126 "DAS_VA_VL_GM_DP_FUSE_VEH_ID3" 125 "DAS_VA_VL_GM_DP_FUSE_VEH_ID2" 124 "DAS_VA_VL_GM_DP_FUSE_VEH_ID1" 123 "DAS_VA_VL_GM_DP_FUSE_VEH_ID0" 122 "DAS_VA_VL_GM_DP_OLD_VEH_ID5" 121 "DAS_VA_VL_GM_DP_OLD_VEH_ID4" 120 "DAS_VA_VL_GM_DP_OLD_VEH_ID3" 119 "DAS_VA_VL_GM_DP_OLD_VEH_ID2" 118 "DAS_VA_VL_GM_DP_OLD_VEH_ID1" 117 "DAS_VA_VL_GM_DP_OLD_VEH_ID0" 116 "DAS_VA_VL_GM_DP_NEW_VEH_ID5" 115 "DAS_VA_VL_GM_DP_NEW_VEH_ID4" 114 "DAS_VA_VL_GM_DP_NEW_VEH_ID3" 113 "DAS_VA_VL_GM_DP_NEW_VEH_ID2" 112 "DAS_VA_VL_GM_DP_NEW_VEH_ID1" 111 "DAS_VA_VL_GM_DP_NEW_VEH_ID0" 110 "DAS_VA_VL_GM_DP_PRECHK_VEH_ID5" 109 "DAS_VA_VL_GM_DP_PRECHK_VEH_ID4" 108 "DAS_VA_VL_GM_DP_PRECHK_VEH_ID3" 107 "DAS_VA_VL_GM_DP_PRECHK_VEH_ID2" 106 "DAS_VA_VL_GM_DP_PRECHK_VEH_ID1" 105 "DAS_VA_VL_GM_DP_PRECHK_VEH_ID0" 104 "DAS_VA_VL_GM_INV_COV_VEH_ID5" 103 "DAS_VA_VL_GM_INV_COV_VEH_ID4" 102 "DAS_VA_VL_GM_INV_COV_VEH_ID3" 101 "DAS_VA_VL_GM_INV_COV_VEH_ID2" 100 "DAS_VA_VL_GM_INV_COV_VEH_ID1" 99 "DAS_VA_VL_GM_INV_COV_VEH_ID0" 98 "DAS_VA_VL_GM_OBS_XFM_VEH_ID5" 97 "DAS_VA_VL_GM_OBS_XFM_VEH_ID4" 96 "DAS_VA_VL_GM_OBS_XFM_VEH_ID3" 95 "DAS_VA_VL_GM_OBS_XFM_VEH_ID2" 94 "DAS_VA_VL_GM_OBS_XFM_VEH_ID1" 93 "DAS_VA_VL_GM_OBS_XFM_VEH_ID0" 92 "DAS_VA_VL_GM_COV_VEH_ID5" 91 "DAS_VA_VL_GM_COV_VEH_ID4" 90 "DAS_VA_VL_GM_COV_VEH_ID3" 89 "DAS_VA_VL_GM_COV_VEH_ID2" 88 "DAS_VA_VL_GM_COV_VEH_ID1" 87 "DAS_VA_VL_GM_COV_VEH_ID0" 86 "DAS_VA_VL_GM_CHK_LANE_VEH_ID5" 85 "DAS_VA_VL_GM_CHK_LANE_VEH_ID4" 84 "DAS_VA_VL_GM_CHK_LANE_VEH_ID3" 83 "DAS_VA_VL_GM_CHK_LANE_VEH_ID2" 82 "DAS_VA_VL_GM_CHK_LANE_VEH_ID1" 81 "DAS_VA_VL_GM_CHK_LANE_VEH_ID0" 80 "DAS_VA_VL_GM_CHK_ID_VEH_ID5" 79 "DAS_VA_VL_GM_CHK_ID_VEH_ID4" 78 "DAS_VA_VL_GM_CHK_ID_VEH_ID3" 77 "DAS_VA_VL_GM_CHK_ID_VEH_ID2" 76 "DAS_VA_VL_GM_CHK_ID_VEH_ID1" 75 "DAS_VA_VL_GM_CHK_ID_VEH_ID0" 74 "DAS_VA_ROB" 73 "DAS_VA_VL_GM_EVAL_SAVE" 72 "DAS_VA_VL_GM_EVAL_NEW_VEH_5" 71 "DAS_VA_VL_GM_EVAL_NEW_VEH_4" 70 "DAS_VA_VL_GM_EVAL_NEW_VEH_3" 69 "DAS_VA_VL_GM_EVAL_NEW_VEH_2" 68 "DAS_VA_VL_GM_EVAL_NEW_VEH_1" 67 "DAS_VA_VL_GM_EVAL_NEW_VEH_0" 66 "DAS_VA_VL_GM_EVAL_VEH_5" 65 "DAS_VA_VL_GM_EVAL_VEH_4" 64 "DAS_VA_VL_GM_EVAL_VEH_3" 63 "DAS_VA_VL_GM_EVAL_VEH_2" 62 "DAS_VA_VL_GM_EVAL_VEH_1" 61 "DAS_VA_VL_GM_EVAL_VEH_0" 60 "DAS_VA_VL_GM_EVAL_NAV" 59 "DAS_VA_VL_GM_EVAL_HPP" 58 "DAS_VA_VL_GM_EVAL_RL" 57 "DAS_VA_VL_GM_EVAL_LL" 56 "DAS_VA_VL_GM_EVAL_MODEL" 55 "DAS_VA_VL_GM_EVAL_SETUP" 54 "DAS_VA_VL_GM_EVAL" 53 "DAS_VA_VL_GM_VEH_ID5" 52 "DAS_VA_VL_GM_VEH_ID4" 51 "DAS_VA_VL_GM_VEH_ID3" 50 "DAS_VA_VL_GM_VEH_ID2" 49 "DAS_VA_VL_GM_VEH_ID1" 48 "DAS_VA_VL_GM_VEH_ID0" 47 "DAS_VA_VL_GM_VEH_2" 46 "DAS_VA_VL_GM_NAV_2" 45 "DAS_VA_VL_GM_FS_2" 44 "DAS_VA_VL_GM_HPP_2" 43 "DAS_VA_VL_GM_LANE_2" 42 "DAS_VA_VL_GM_NAV_1" 41 "DAS_VA_VL_GM_VEH_1" 40 "DAS_VA_VL_GM_FS_1" 39 "DAS_VA_VL_GM_HPP_1" 38 "DAS_VA_VL_GM_LANE_1" 37 "DAS_VA_VL_GM_SETUP" 36 "DAS_VA_VL_UU" 35 "DAS_VA_VL_CDH" 34 "DAS_VA_VL_MP" 33 "DAS_VA_VL_ETC" 32 "DAS_VA_VL_GM" 31 "DAS_VA_VL_CMC" 30 "DAS_VA_VL_CFELC" 29 "DAS_VA_VL_UELP" 28 "DAS_VA_VL_CCM" 27 "DAS_VA_VL_CDE" 26 "DAS_VA_VL_SM" 25 "DAS_VA_VL_UFC" 24 "DAS_VA_VL_FM" 23 "DAS_VA_VL_UNO" 22 "DAS_VA_VL_ULWE" 21 "DAS_VA_VL_CFKO" 20 "DAS_VA_VL_RLV" 19 "DAS_VA_VL_SO" 18 "DAS_VA_ROAD_FURNITURE" 17 "DAS_VA_VIRTUAL_WALL" 16 "DAS_VA_VIRTUAL_LANE" 15 "DAS_VA_WORLD_MODEL" 14 "DAS_VA_TRAJECTORY_PLANNER" 13 "DAS_VA_CSA" 12 "DAS_VA_TSR" 11 "DAS_VA_LDW" 10 "DAS_VA_ACC" 9 "DAS_VA_FCM" 8 "DAS_VA_LC" 7 "DAS_VA_BSD" 6 "DAS_VA_AHB" 5 "DAS_VA_SCA" 4 "DAS_VA_APC" 3 "DAS_VA_PMM" 2 "DAS_VA_VEHICLE" 1 "DAS_VA_INIT" 0 "DAS_VA_NONE" ;
VAL_ 1465 DAS_sw025_state_before_override 15 "LC_INTERNAL_STATE_PRECANCEL" 14 "LC_INTERNAL_STATE_DRIVER_STEERING_OVERRIDE" 13 "LC_INTERNAL_STATE_PREABORTED" 12 "LC_INTERNAL_STATE_FAULT" 11 "LC_INTERNAL_STATE_ABORTED" 10 "LC_INTERNAL_STATE_ABORTING" 9 "LC_INTERNAL_STATE_CHECK_ACTIVATION_WHILE_UNAVAILABLE" 8 "LC_INTERNAL_STATE_CHECK_ACTIVATION_WHILE_DISABLED" 7 "LC_INTERNAL_STATE_ACTIVE_RESTRICTED" 6 "LC_INTERNAL_STATE_ACTIVE_NOMINAL" 5 "LC_INTERNAL_STATE_PREACTIVATION" 4 "LC_INTERNAL_STATE_CHECK_FOR_ACTIVATION" 3 "LC_INTERNAL_STATE_AVAILABLE" 2 "LC_INTERNAL_STATE_UNAVAILABLE" 1 "LC_INTERNAL_STATE_DISABLED" 0 "LC_INTERNAL_STATE_NO_AUTOPILOT" ;
VAL_ 1465 DAS_sw025_leftLaneUsage 3 "BLACKLISTED" 2 "FUSED" 1 "AVAILABLE" 0 "REJECTED_UNAVAILABLE" ;
VAL_ 1465 DAS_sw025_rightLaneUsage 3 "BLACKLISTED" 2 "FUSED" 1 "AVAILABLE" 0 "REJECTED_UNAVAILABLE" ;
VAL_ 1465 DAS_sw025_vehiclesUsage 3 "BLACKLISTED" 2 "FUSED" 1 "AVAILABLE" 0 "REJECTED_UNAVAILABLE" ;
VAL_ 1465 DAS_sw025_hppUsage 3 "BLACKLISTED" 2 "FUSED" 1 "AVAILABLE" 0 "REJECTED_UNAVAILABLE" ;
VAL_ 1465 DAS_sw025_navigationUsage 3 "BLACKLISTED" 2 "FUSED" 1 "AVAILABLE" 0 "REJECTED_UNAVAILABLE" ;
VAL_ 1465 DAS_sw025_modelUsage 3 "BLACKLISTED" 2 "FUSED" 1 "AVAILABLE" 0 "REJECTED_UNAVAILABLE" ;
VAL_ 1465 DAS_sw025_bottsDotsUsage 3 "BLACKLISTED" 2 "FUSED" 1 "AVAILABLE" 0 "REJECTED_UNAVAILABLE" ;
VAL_ 1465 DAS_sw025_offsetSide 3 "OFFSET_BOTH_OBJECTS" 2 "OFFSET_LEFT_OBJECT" 1 "OFFSET_RIGHT_OBJECT" 0 "NO_OFFSET" ;
VAL_ 1465 DAS_sw026_task_id 3 "Vehicle" 2 "Mobileye" 1 "UDS" 0 "CAN" ;
VAL_ 1465 DAS_sw030_heaterState 2 "SHORT" 1 "OPEN" 0 "NORMAL" ;
VAL_ 1465 DAS_sw031_canBus 7 "Unknown" 1 "RAD0" 0 "CH" ;
VAL_ 1465 DAS_sw031_errorType 8 "Generic" 7 "CAN Bus" 6 "Mailbox" 5 "Overrun" 4 "Invalid Data" 3 "Sequence" 2 "Checksum" 1 "Length" 0 "None" ;
VAL_ 1465 DAS_sw032_canBus 7 "Unknown" 1 "RAD0" 0 "CH" ;
VAL_ 1465 DAS_sw032_errorType 2 "Generic" 1 "Overrun" 0 "None" ;
VAL_ 1465 DAS_sw033_gtwMia 128 "CH_BC_status_MIA" 7 "CH_GTW_gitHash_MIA" 6 "CH_VIP_405HS_MIA" 5 "CH_GTW_time_MIA" 4 "CH_GTW_status_MIA" 3 "CH_GTW_odo_MIA" 2 "CH_GTW_chNm_MIA" 1 "CH_GTW_carConfig_MIA" 0 "Nominal" ;
VAL_ 1465 DAS_sw034_sccmMia 2 "CH_STW_ANGLHP_STAT_MIA" 1 "CH_STW_ACTN_RQ_MIA" 0 "Nominal" ;
VAL_ 1465 DAS_sw035_espMia 9 "ESP_B_MIA" 8 "ESP_wheelSpeeds_MIA" 7 "ESP_115h_MIA" 6 "DISCONTINUED_ESP_E_MIA" 5 "ESP_C_MIA" 4 "DISCONTINUED_ESP_A_MIA" 3 "ESP_145h_MIA" 2 "ESP_135h_MIA" 1 "ESP_125h_MIA" 0 "Nominal" ;
VAL_ 1465 DAS_sw036_bdyMia 130 "CH_BCS2C_restraintStatus_MIA" 129 "CH_BCS2L_restraintStatus_MIA" 128 "CH_BCS2R_restraintStatus_MIA" 1 "BDY_status_MIA" 0 "Nominal" ;
VAL_ 1465 DAS_sw037_issue 1 "Invalid parameters" 0 "Failed to read" ;
VAL_ 1465 DAS_sw038_RadarMisalignment 1 "True" 0 "False" ;
VAL_ 1465 DAS_sw038_OutOfFocusImage 1 "True" 0 "False" ;
VAL_ 1465 DAS_sw038_AutofixOutOfCalib 1 "True" 0 "False" ;
VAL_ 1465 DAS_sw038_AutofixOutOfCalibHorzn 1 "True" 0 "False" ;
VAL_ 1465 DAS_sw038_AutofixOutOfCalibYaw 1 "True" 0 "False" ;
VAL_ 1465 DAS_sw038_FullBlockage 1 "True" 0 "False" ;
VAL_ 1465 DAS_sw039_sdm_rcm_Mia 128 "CH_RCM_STATUS_MIA" 1 "CH_SDM1_MIA" 0 "Nominal" ;
VAL_ 1465 DAS_sw042_health_state 7 "AP_HEALTH_SNA" 6 "AP_HEALTH_UNUSED" 5 "AP_HEALTH_FAULT" 4 "AP_HEALTH_ABORTING" 3 "AP_HEALTH_SEVERELY_DEGRADED" 2 "AP_HEALTH_DEGRADED" 1 "AP_HEALTH_NOMINAL" 0 "AP_HEALTH_UNAVAILABLE" ;
VAL_ 1465 DAS_sw042_abort_reason 18 "LC_ABORT_APP_ME_STATE" 17 "LC_ABORT_ME_MAIN_STATE" 16 "LC_ABORT_CAMERA_MSG_MIA" 15 "LC_ABORT_CAMERA_WATCHDOG" 14 "LC_ABORT_TRAILER_MODE_ACTIVATION" 13 "LC_ABORT_SIDE_COLLISION_IMMINENT" 12 "LC_ABORT_ACC_CANCEL" 11 "LC_ABORT_CAMERA_FAILSAFES" 10 "LC_ABORT_EPAS_ERROR_CODE" 9 "LC_ABORT_PLANNER_OUTPUT_INVALID" 8 "LC_ABORT_FOLLOWER_OUTPUT_INVALID" 7 "LC_ABORT_VEHICLE_SPEED_ABOVE_MAX" 6 "LC_ABORT_HEALTH_MONITOR" 5 "LC_ABORT_DRIVING_OFF_NAV" 4 "LC_ABORT_CID_SWITCH_DISABLED" 3 "LC_ABORT_CRUISE_FAULT" 2 "LC_ABORT_COMPONENT_MIA" 1 "LC_ABORT_EPAS_EAC_DENIED" 0 "LC_ABORT_NONE" ;
VAL_ 1465 DAS_sw042_state_before_abort 15 "LC_INTERNAL_STATE_PRECANCEL" 14 "LC_INTERNAL_STATE_DRIVER_STEERING_OVERRIDE" 13 "LC_INTERNAL_STATE_PREABORTED" 12 "LC_INTERNAL_STATE_FAULT" 11 "LC_INTERNAL_STATE_ABORTED" 10 "LC_INTERNAL_STATE_ABORTING" 9 "LC_INTERNAL_STATE_CHECK_ACTIVATION_WHILE_UNAVAILABLE" 8 "LC_INTERNAL_STATE_CHECK_ACTIVATION_WHILE_DISABLED" 7 "LC_INTERNAL_STATE_ACTIVE_RESTRICTED" 6 "LC_INTERNAL_STATE_ACTIVE_NOMINAL" 5 "LC_INTERNAL_STATE_PREACTIVATION" 4 "LC_INTERNAL_STATE_CHECK_FOR_ACTIVATION" 3 "LC_INTERNAL_STATE_AVAILABLE" 2 "LC_INTERNAL_STATE_UNAVAILABLE" 1 "LC_INTERNAL_STATE_DISABLED" 0 "LC_INTERNAL_STATE_NO_AUTOPILOT" ;
VAL_ 1465 DAS_sw042_epas_error_code 15 "SNA" 13 "EAC_ERROR_PINION_VEL_DIFF" 12 "EAC_ERROR_LOW_ASSIST" 11 "EAC_ERROR_HIGH_TORSION_SAFETY" 10 "EAC_ERROR_HIGH_MMOT_SAFETY" 9 "EAC_ERROR_HIGH_ANGLE_RATE_SAFETY" 8 "EAC_ERROR_HIGH_ANGLE_SAFETY" 7 "EAC_ERROR_HIGH_ANGLE_RATE_REQ" 6 "EAC_ERROR_HIGH_ANGLE_REQ" 5 "EAR_ERROR_MAX_STEER_DELTA" 4 "EAC_ERROR_TMP_FAULT" 3 "EAC_ERROR_HANDS_ON" 2 "EAC_ERROR_MAX_SPEED" 1 "EAC_ERROR_MIN_SPEED" 0 "EAC_ERROR_IDLE" ;
VAL_ 1465 DAS_sw043_mobileye_status 24 "MOBILEYE_STATUS_UNDEFINED" 23 "MOBILEYE_STATUS_TEARDOWN_FLASH_ACCESS_MODE" 22 "MOBILEYE_STATUS_FLASH_READ_MODE" 21 "MOBILEYE_STATUS_SETUP_FLASH_ACCESS_MODE" 20 "MOBILEYE_STATUS_RUNNING_SPTAC_MODE" 19 "MOBILEYE_STATUS_SPTAC_INIT_SENT" 18 "MOBILEYE_STATUS_WAITING_FOR_SPTAC_INIT" 17 "MOBILEYE_STATUS_BURN_EDR_MODE" 16 "MOBILEYE_STATUS_SPC_INIT_SENT" 15 "MOBILEYE_STATUS_WAITING_FOR_SPC_INIT" 14 "MOBILEYE_STATUS_ERROR" 13 "MOBILEYE_STATUS_LATCHING_FAILURE" 12 "MOBILEYE_STATUS_UPDATING" 11 "MOBILEYE_STATUS_RUNNING_DV_MODE" 10 "MOBILEYE_STATUS_WAITING_FOR_DV" 9 "MOBILEYE_STATUS_RUNNING_TAC_MODE" 8 "MOBILEYE_STATUS_RUNNING_SPC_MODE" 7 "MOBILEYE_STATUS_RUNNING_VISION_MODE" 6 "MOBILEYE_STATUS_TAC_INIT_SENT" 5 "MOBILEYE_STATUS_WAITING_FOR_TAC_INIT" 4 "MOBILEYE_STATUS_VISION_INIT_SENT" 3 "MOBILEYE_STATUS_WAITING_FOR_VISION_INIT" 2 "MOBILEYE_STATUS_WAITING_FOR_BOOT" 1 "MOBILEYE_STATUS_POWER_OFF" 0 "MOBILEYE_STATUS_POWER_CYCLE" ;
VAL_ 1465 DAS_sw043_mesp_health_main_state 172 "EYEQ_MESP_MAIN_STATE_TAC2" 170 "EYEQ_MESP_MAIN_STATE_DV" 146 "EYEQ_MESP_MAIN_STATE_VISION_INIT_PENDING" 133 "EYEQ_MESP_MAIN_STATE_TAC2_INIT_PENDING" 130 "EYEQ_MESP_MAIN_STATE_SPC_INIT_PENDING" 129 "EYEQ_MESP_MAIN_STATE_SPTAC_INIT_PENDING" 34 "EYEQ_MESP_MAIN_STATE_SPC" 33 "EYEQ_MESP_MAIN_STATE_SPTAC" 2 "EYEQ_MESP_MAIN_STATE_VISION" ;
VAL_ 1465 DAS_sw044_appStatus 24 "MOBILEYE_STATUS_UNDEFINED" 23 "MOBILEYE_STATUS_TEARDOWN_FLASH_ACCESS_MODE" 22 "MOBILEYE_STATUS_FLASH_READ_MODE" 21 "MOBILEYE_STATUS_SETUP_FLASH_ACCESS_MODE" 20 "MOBILEYE_STATUS_RUNNING_SPTAC_MODE" 19 "MOBILEYE_STATUS_SPTAC_INIT_SENT" 18 "MOBILEYE_STATUS_WAITING_FOR_SPTAC_INIT" 17 "MOBILEYE_STATUS_BURN_EDR_MODE" 16 "MOBILEYE_STATUS_SPC_INIT_SENT" 15 "MOBILEYE_STATUS_WAITING_FOR_SPC_INIT" 14 "MOBILEYE_STATUS_ERROR" 13 "MOBILEYE_STATUS_LATCHING_FAILURE" 12 "MOBILEYE_STATUS_UPDATING" 11 "MOBILEYE_STATUS_RUNNING_DV_MODE" 10 "MOBILEYE_STATUS_WAITING_FOR_DV" 9 "MOBILEYE_STATUS_RUNNING_TAC_MODE" 8 "MOBILEYE_STATUS_RUNNING_SPC_MODE" 7 "MOBILEYE_STATUS_RUNNING_VISION_MODE" 6 "MOBILEYE_STATUS_TAC_INIT_SENT" 5 "MOBILEYE_STATUS_WAITING_FOR_TAC_INIT" 4 "MOBILEYE_STATUS_VISION_INIT_SENT" 3 "MOBILEYE_STATUS_WAITING_FOR_VISION_INIT" 2 "MOBILEYE_STATUS_WAITING_FOR_BOOT" 1 "MOBILEYE_STATUS_POWER_OFF" 0 "MOBILEYE_STATUS_POWER_CYCLE" ;
VAL_ 1465 DAS_sw044_meMainState 8 "ERROR" 7 "DV" 6 "TAC2" 5 "TAC2_INIT_PENDING" 4 "SPC" 3 "SPC_INIT_PENDING" 2 "VISION" 1 "VISION_INIT_PENDING" 0 "NOT_INITIALIZED" ;
VAL_ 1465 DAS_sw045_radMia 21 "RAD0_RADC_TGU_info_MIA" 20 "RAD0_RADC_SGU_info_MIA" 19 "RAD0_RADC_ACCTargObj1_A_MIA" 18 "RAD0_RADC_ACCTargObj1_B_MIA" 17 "RAD0_RADC_ACCTargObj1_C_MIA" 16 "RAD0_RADC_ACCTargObj2_A_MIA" 15 "RAD0_RADC_ACCTargObj2_B_MIA" 14 "RAD0_RADC_ACCTargObj2_C_MIA" 13 "RAD0_RADC_ACCTargObj3_C_MIA" 12 "RAD0_RADC_ACCTargObj4_C_MIA" 11 "RAD0_RADC_ACCTargObj5_A_MIA" 10 "RAD0_RADC_ACCTargObj5_B_MIA" 9 "RAD0_RADC_ACCTargObj5_C_MIA" 8 "RAD0_RADC_FCWTargObj_A_MIA" 7 "RAD0_RADC_FCWTargObj_B_MIA" 6 "RAD0_RADC_FCWTargObj_C_MIA" 5 "RAD0_RADC_Packet_Ender_MIA" 4 "RAD0_RADC_Packet_Starter_MIA" 3 "RAD0_RADC_info_MIA" 2 "RAD0_RADRL_alertMatrix_MIA" 1 "RAD0_RADC_alertMatrix_MIA" 0 "Nominal" ;
VAL_ 1465 DAS_sw047_edrStatus 6 "EVENT_TRIGGER_REJECTED" 5 "EVENT_SAVED_TO_FLASH" 4 "EVENT_SAVED_TO_LB" 3 "EVENT_TRIGGERED" 2 "EVENT_ERASED" 1 "FAULTED" 0 "EMPTY" ;
VAL_ 1465 DAS_sw047_edrType 11 "ROB_TYPE" 10 "FREESPACE_ELDW" 9 "AIRBAG_NEAR_DEPLOY" 8 "PMM" 7 "IN_PATH_STAT_OBJ" 6 "ME_AEB" 5 "UDS" 4 "FCW" 3 "HEAVY_BRAKING" 2 "AEB" 1 "AIRBAG_DEPLOY" 0 "UNDEFINED" ;
VAL_ 1465 DAS_sw047_edrReturn 4000 "ERROR_EDR_MANAGER" 3000 "ERROR_DUMP_FAILED" 2000 "ERROR_LOG_DATA_FAILED" 1027 "ERROR_EDR_MANAGER_INVALID" 1026 "ERROR_POST_TRIGGER_NUM_TOO_LARGE" 1025 "ERROR_BB_NOT_FORMATTED" 1024 "ERROR_BB_VALIDATE_PROBLEM" 1023 "ERROR_FAILED_NO_DESC_AVALIABLE" 1022 "ERROR_NOT_ENOUGH_FRAMES_IN_LB" 1021 "ERROR_FAILED_WRITE_DATA_TO_BB" 1020 "ERROR_FAILED_NO_DATA_AVALIABLE" 1019 "ERROR_LB_CLIP_NOT_AVALIABLE" 1018 "ERROR_LB_ALREADY_CURRENT" 1017 "ERROR_WRONG_STATE" 1016 "ERROR_WRONG_LOGGER_BUFFER" 1015 "ERROR_FAILED_DUMP_LB_TO_BB" 1014 "ERROR_FAILED_FORMAT_BB" 1013 "ERROR_FAILED_TO_BURN_TO_REG_BB" 1012 "ERROR_NOTHING_TO_UPDATE" 1011 "ERROR_WRONG_CURR_TAG" 1010 "ERROR_BB_REG_ERROROR" 1009 "ERROR_DATA_SIZE_MISMATCH" 1008 "ERROR_FUNC_FAILED" 1006 "ERROR_PROCESS_OTHER_TASK" 1005 "ERROR_NO_DATA_TO_SAVE" 1004 "ERROR_FLASH_BB_LOCK" 1003 "ERROR_IMAGE_LOGGER_NOT_FOUND" 1002 "ERROR_BB_NOT_FOUND" 1001 "ERROR_INIT" 1000 "ERROR_UNDEFINED" 107 "ERROR_FUNC_NOT_EXIST" 0 "SUCCESS" ;
VAL_ 1465 DAS_sw047_edrStateMachine 255 "EDR_FATAL_ERROR" 54 "PROCESS_EDR_NB_EXECUTE" 53 "PROCESS_EDR_EXECUTE_PART_2" 52 "PROCESS_EDR_EXECUTE_PART_1" 51 "PROCESS_EDR_MAP_LB_TO_BB" 34 "PROCESS_EDR_BB_CANCEL_FORMAT" 33 "PROCESS_EDR_BB_FORMAT" 32 "PROCESS_EDR_BB_GET_DESC" 30 "PROCESS_EDR_BB_QUERY" 16 "PROCESS_EDR_LB_SWITCH" 14 "PROCESS_EDR_LB_SET_DATA" 13 "PROCESS_EDR_LB_SET_DESC" 12 "PROCESS_EDR_LB_TRIGGER_EVENT" 11 "PROCESS_EDR_LB_QUERY" 10 "PROCESS_EDR_LB_GET_CURR" 4 "EDR_BURN_COMPLETE" 2 "EDR_TRIGGERED" 1 "RUNNING" 0 "IDLE" ;
VAL_ 1465 DAS_sw049_boot_version_msw 65535 "FLASH_SECTION_EMPTY" 24589 "NO_MISMATCH" 0 "FLASH_READ_FAILURE" ;
VAL_ 1465 DAS_sw049_app_version_msw 65535 "FLASH_SECTION_EMPTY" 24589 "NO_MISMATCH" 0 "FLASH_READ_FAILURE" ;
VAL_ 1465 DAS_sw049_ffs_version_msw 65535 "FLASH_SECTION_EMPTY" 24589 "NO_MISMATCH" 0 "FLASH_READ_FAILURE" ;
VAL_ 1465 DAS_sw051_a01ecuInternalPerf 1 "True" 0 "False" ;
VAL_ 1465 DAS_sw051_a02flashPerformance 1 "True" 0 "False" ;
VAL_ 1465 DAS_sw051_a03vBatHigh 1 "True" 0 "False" ;
VAL_ 1465 DAS_sw051_a09configMismatch 1 "True" 0 "False" ;
VAL_ 1465 DAS_sw051_a52radomeHtrInop 1 "True" 0 "False" ;
VAL_ 1465 DAS_sw052_a07sensorBlinded 1 "True" 0 "False" ;
VAL_ 1465 DAS_sw056_diMia 5 "CH_DI_state2_MIA" 4 "CH_DI_espControl_MIA" 3 "CH_DI_torque2_MIA" 2 "CH_DI_torque1_MIA" 1 "CH_DI_state_MIA" 0 "Nominal" ;
VAL_ 1465 DAS_sw057_chCtrlMia 1 "True" 0 "False" ;
VAL_ 1465 DAS_sw057_dasMapDataMia 1 "True" 0 "False" ;
VAL_ 1465 DAS_sw057_locStatusMia 1 "True" 0 "False" ;
VAL_ 1465 DAS_sw057_gpsVehSpeedMia 1 "True" 0 "False" ;
VAL_ 1465 DAS_sw057_dasRoadSignMia 1 "True" 0 "False" ;
VAL_ 1465 DAS_sw057_radarMapDataMia 1 "True" 0 "False" ;
VAL_ 1465 DAS_sw057_csaRoadCurvMia 1 "True" 0 "False" ;
VAL_ 1465 DAS_sw057_csaOfframpCurvMia 1 "True" 0 "False" ;
VAL_ 1465 DAS_sw058_epbMia 1 "CH_EPB_status_MIA" 0 "Nominal" ;
VAL_ 1465 DAS_sw059_parkMia 11 "CH_PARK_pasRearMiddle_MIA" 10 "CH_PARK_sensorStatusRear_MIA" 9 "CH_PARK_oloDict_MIA" 8 "CH_PARK_status2_MIA" 7 "CH_PARK_pasFrontMiddle_MIA" 6 "CH_PARK_sensorStatusFront_MIA" 5 "CH_PARK_status_MIA" 4 "CH_PARK_oocStatus_MIA" 3 "CH_PARK_sdiRear_MIA" 2 "CH_PARK_pscStatus_MIA" 1 "CH_PARK_sdiFront_MIA" 0 "Nominal" ;
VAL_ 1465 DAS_sw060_collisionWarningSource 7 "SOURCE_BCW_PEDESTRIAN" 6 "SOURCE_BCW_MCVLR" 5 "SOURCE_BCW_CIPV2" 4 "SOURCE_BCW_CIPV" 3 "SOURCE_BCW_CUTIN" 2 "SOURCE_STOPLINE" 1 "SOURCE_FCW_VEHICLE" 0 "SOURCE_FCW_PEDESTRIAN" ;
VAL_ 1465 DAS_sw061_airSuspensionMia 128 "CH_TAS_STATES_MIA" 1 "CH_ASD_A2_MIA" 0 "Nominal" ;
VAL_ 1465 DAS_sw064_epasMia 1 "CH_EPAS_sysStatus_MIA" 0 "Nominal" ;
VAL_ 1465 DAS_sw065_app_mobileye_status 24 "MOBILEYE_STATUS_UNDEFINED" 23 "MOBILEYE_STATUS_TEARDOWN_FLASH_ACCESS_MODE" 22 "MOBILEYE_STATUS_FLASH_READ_MODE" 21 "MOBILEYE_STATUS_SETUP_FLASH_ACCESS_MODE" 20 "MOBILEYE_STATUS_RUNNING_SPTAC_MODE" 19 "MOBILEYE_STATUS_SPTAC_INIT_SENT" 18 "MOBILEYE_STATUS_WAITING_FOR_SPTAC_INIT" 17 "MOBILEYE_STATUS_BURN_EDR_MODE" 16 "MOBILEYE_STATUS_SPC_INIT_SENT" 15 "MOBILEYE_STATUS_WAITING_FOR_SPC_INIT" 14 "MOBILEYE_STATUS_ERROR" 13 "MOBILEYE_STATUS_LATCHING_FAILURE" 12 "MOBILEYE_STATUS_UPDATING" 11 "MOBILEYE_STATUS_RUNNING_DV_MODE" 10 "MOBILEYE_STATUS_WAITING_FOR_DV" 9 "MOBILEYE_STATUS_RUNNING_TAC_MODE" 8 "MOBILEYE_STATUS_RUNNING_SPC_MODE" 7 "MOBILEYE_STATUS_RUNNING_VISION_MODE" 6 "MOBILEYE_STATUS_TAC_INIT_SENT" 5 "MOBILEYE_STATUS_WAITING_FOR_TAC_INIT" 4 "MOBILEYE_STATUS_VISION_INIT_SENT" 3 "MOBILEYE_STATUS_WAITING_FOR_VISION_INIT" 2 "MOBILEYE_STATUS_WAITING_FOR_BOOT" 1 "MOBILEYE_STATUS_POWER_OFF" 0 "MOBILEYE_STATUS_POWER_CYCLE" ;
VAL_ 1465 DAS_sw065_mobileye_main_state 255 "EYEQ_MESP_MAIN_STATE_UNDEFINED" 172 "EYEQ_MESP_MAIN_STATE_TAC2" 170 "EYEQ_MESP_MAIN_STATE_DV" 146 "EYEQ_MESP_MAIN_STATE_VISION_INIT_PENDING" 133 "EYEQ_MESP_MAIN_STATE_TAC2_INIT_PENDING" 130 "EYEQ_MESP_MAIN_STATE_SPC_INIT_PENDING" 129 "EYEQ_MESP_MAIN_STATE_SPTAC_INIT_PENDING" 34 "EYEQ_MESP_MAIN_STATE_SPC" 33 "EYEQ_MESP_MAIN_STATE_SPTAC" 2 "EYEQ_MESP_MAIN_STATE_VISION" ;
VAL_ 1465 DAS_sw066_app_mobileye_status 24 "MOBILEYE_STATUS_UNDEFINED" 23 "MOBILEYE_STATUS_TEARDOWN_FLASH_ACCESS_MODE" 22 "MOBILEYE_STATUS_FLASH_READ_MODE" 21 "MOBILEYE_STATUS_SETUP_FLASH_ACCESS_MODE" 20 "MOBILEYE_STATUS_RUNNING_SPTAC_MODE" 19 "MOBILEYE_STATUS_SPTAC_INIT_SENT" 18 "MOBILEYE_STATUS_WAITING_FOR_SPTAC_INIT" 17 "MOBILEYE_STATUS_BURN_EDR_MODE" 16 "MOBILEYE_STATUS_SPC_INIT_SENT" 15 "MOBILEYE_STATUS_WAITING_FOR_SPC_INIT" 14 "MOBILEYE_STATUS_ERROR" 13 "MOBILEYE_STATUS_LATCHING_FAILURE" 12 "MOBILEYE_STATUS_UPDATING" 11 "MOBILEYE_STATUS_RUNNING_DV_MODE" 10 "MOBILEYE_STATUS_WAITING_FOR_DV" 9 "MOBILEYE_STATUS_RUNNING_TAC_MODE" 8 "MOBILEYE_STATUS_RUNNING_SPC_MODE" 7 "MOBILEYE_STATUS_RUNNING_VISION_MODE" 6 "MOBILEYE_STATUS_TAC_INIT_SENT" 5 "MOBILEYE_STATUS_WAITING_FOR_TAC_INIT" 4 "MOBILEYE_STATUS_VISION_INIT_SENT" 3 "MOBILEYE_STATUS_WAITING_FOR_VISION_INIT" 2 "MOBILEYE_STATUS_WAITING_FOR_BOOT" 1 "MOBILEYE_STATUS_POWER_OFF" 0 "MOBILEYE_STATUS_POWER_CYCLE" ;
VAL_ 1465 DAS_sw066_mobileye_main_state 255 "EYEQ_MESP_MAIN_STATE_UNDEFINED" 172 "EYEQ_MESP_MAIN_STATE_TAC2" 170 "EYEQ_MESP_MAIN_STATE_DV" 146 "EYEQ_MESP_MAIN_STATE_VISION_INIT_PENDING" 133 "EYEQ_MESP_MAIN_STATE_TAC2_INIT_PENDING" 130 "EYEQ_MESP_MAIN_STATE_SPC_INIT_PENDING" 129 "EYEQ_MESP_MAIN_STATE_SPTAC_INIT_PENDING" 34 "EYEQ_MESP_MAIN_STATE_SPC" 33 "EYEQ_MESP_MAIN_STATE_SPTAC" 2 "EYEQ_MESP_MAIN_STATE_VISION" ;
VAL_ 1465 DAS_sw069_epasMia 1 "EPAS_MIA" 0 "NO_EPAS_MIA" ;
VAL_ 1465 DAS_sw069_espMia 1 "ESP_MIA" 0 "NO_ESP_MIA" ;
VAL_ 1465 DAS_sw069_parkMia 1 "PARK_MIA" 0 "NO_PARK_MIA" ;
VAL_ 1465 DAS_sw069_sccmMia 1 "SCCM_MIA" 0 "NO_SCCM_MIA" ;
VAL_ 1465 DAS_sw069_parkMismatch 1 "PARK_VERSION_MISMATCH" 0 "NO_PARK_VERSION_MISMATCH" ;
VAL_ 1465 DAS_sw069_eacStatus 4 "SNA" 3 "EAC_FAULT" 2 "EAC_ACTIVE" 1 "EAC_AVAILABLE" 0 "EAC_INHIBITED" ;
VAL_ 1465 DAS_sw069_diAPState 15 "DI_APC_SNA" 8 "DI_APC_UNPARK_COMPLETE" 7 "DI_APC_RESUMED" 6 "DI_APC_ABORTED" 5 "DI_APC_PAUSED" 4 "DI_APC_COMPLETE" 3 "DI_APC_ACTIVE" 2 "DI_APC_STARTED" 1 "DI_APC_STANDBY" 0 "DI_APC_UNAVAILABLE" ;
VAL_ 1465 DAS_sw069_parkCal 1 "COMPLETE" 0 "INCOMPLETE" ;
VAL_ 1465 DAS_sw070_currTireFitment 3 "SNA" 1 "STAGGERED" 0 "SQUARE" ;
VAL_ 1465 DAS_sw070_lastTireFitment 3 "SNA" 1 "STAGGERED" 0 "SQUARE" ;
VAL_ 1465 DAS_sw070_diGear 7 "DI_GEAR_SNA" 4 "DI_GEAR_D" 3 "DI_GEAR_N" 2 "DI_GEAR_R" 1 "DI_GEAR_P" 0 "DI_GEAR_INVALID" ;
VAL_ 1465 DAS_sw071_selfParkType 7 "SNA" 6 "SP_GUIDANCE_UNAVAILABLE" 5 "SP_GUIDANCE_FAULT" 4 "SP_GUIDANCE_ABORT" 3 "SP_GUIDANCE_COMPLETE" 2 "SP_GUIDANCE_UNPARK_ACTIVE" 1 "SP_GUIDANCE_PARK_ACTIVE" 0 "SP_GUIDANCE_STANDBY" ;
VAL_ 1465 DAS_sw071_roadClass 6 "CLASS_6_MINOR" 5 "CLASS_5" 4 "CLASS_4" 3 "CLASS_3" 2 "CLASS_2" 1 "CLASS_1_MAJOR" 0 "UNKNOWN_INVALID_SNA" ;
VAL_ 1465 DAS_sw071_driverPresent 1 "TRUE" 0 "FALSE" ;
VAL_ 1465 DAS_sw071_airSuspension 6 "VERY_HIGH_LEVEL" 5 "HIGH_LEVEL" 4 "NORMAL_LEVEL" 3 "LOW_LEVEL" ;
VAL_ 1465 DAS_sw071_activationType 2 "AUTOSUMMON" 1 "KEYFOB" 0 "CELL_PHONE" ;
VAL_ 1465 DAS_sw073_escalateLDWreason 3 "LC_ELDW_REASON_STW_TAKEOVER" 2 "LC_ELDW_REASON_DOUBLE_PULL" 1 "LC_ELDW_REASON_SINGLE_PULL" 0 "LC_ELDW_REASON_NONE" ;
VAL_ 1465 DAS_sw073_rawMobileyeLDW 3 "RESERVED" 2 "LDW_RIGHT" 1 "LDW_LEFT" 0 "NO_WARNING" ;
VAL_ 1465 DAS_sw073_freespaceLDW 3 "RESERVED" 2 "LDW_RIGHT" 1 "LDW_LEFT" 0 "NO_WARNING" ;
VAL_ 1465 DAS_sw074_roadClass 6 "CLASS_6_MINOR" 5 "CLASS_5" 4 "CLASS_4" 3 "CLASS_3" 2 "CLASS_2" 1 "CLASS_1_MAJOR" 0 "UNKNOWN_INVALID_SNA" ;
VAL_ 1465 DAS_sw074_cruiseActive 1 "CRUISE_ACTIVE" 0 "CRUISE_INACTIVE" ;
VAL_ 1465 DAS_sw074_autopilotActive 1 "AUTOPILOT_ACTIVE" 0 "AUTOPILOT_INACTIVE" ;
VAL_ 1465 DAS_sw075_scMia 1 "CH_SC_Status_MIA" 0 "Nominal" ;
VAL_ 1465 DAS_sw193_outOfFocusImage 1 "True" 0 "False" ;
VAL_ 1465 DAS_sw193_impairedVD 1 "True" 0 "False" ;
VAL_ 1465 DAS_sw193_blurredImage 1 "True" 0 "False" ;
VAL_ 1465 DAS_sw193_smearedSpots 1 "True" 0 "False" ;
VAL_ 1465 DAS_sw193_partialBlockage 1 "True" 0 "False" ;
VAL_ 1465 DAS_sw193_fullBlockage 1 "True" 0 "False" ;
VAL_ 1465 DAS_sw193_smearedHalos 1 "True" 0 "False" ;
VAL_ 1465 DAS_sw194_leadDx 255 "SNA" ;
VAL_ 1465 DAS_sw194_leadVx 31 "SNA" ;
VAL_ 1465 DAS_sw194_leadAx 31 "SNA" ;
VAL_ 1465 DAS_sw194_reasonForHold 15 "SNA" 8 "MCP_CONTROL" 7 "DRIVER_SEATBELT" 6 "TRAFFIC_LIGHT" 5 "STOP_SIGN" 4 "CAM_STOP_AND_GO" 3 "TARGET_LOSS" 2 "ULTRASONIC_OBSTACLE" 1 "CAM_PEDESTRIAN" 0 "TIMEOUT" ;
VAL_ 1465 DAS_sw199_internalState 14 "APC_INT_STATE_CENTER_STW" 13 "APC_INT_STATE_GEAR_CHANGE" 12 "APC_INT_STATE_PARKED" 11 "APC_INT_STATE_COMPLETE_UNPARKED" 10 "APC_INT_STATE_COMPLETE" 9 "APC_INT_STATE_ABORT" 8 "APC_INT_STATE_RESTART" 7 "APC_INT_STATE_PAUSE_USER_CONTROL" 6 "APC_INT_STATE_PAUSE_OBSTACLE_CONTROL" 5 "APC_INT_STATE_REVERSE_CONTROL" 4 "APC_INT_STATE_FORWARD_CONTROL" 3 "APC_INT_STATE_PREGUIDANCE" 2 "APC_INT_STATE_PRECRUISE" 1 "APC_INT_STATE_SEARCHING" 0 "APC_INT_STATE_DISABLED" ;
VAL_ 1465 DAS_sw199_abortCodePARK 31 "SNA" 17 "ERROR" 16 "SYSTEM_FAULT" 15 "SYSTEM_SERVICE" 14 "DAS_ABORT" 13 "EPAS_FAULT" 12 "VEHICLE_DYNAMICS_INTERVENTION" 11 "HANDS_ON_DETECTED" 10 "FULL_WARNING_ON_BOTH_SIDES" 9 "PARK_SPACE_TOO_SMALL" 8 "OBSTACLE_ON_PATH" 7 "MAX_YAW_ANGLE_REACHED" 6 "MAX_SWA_DEV_EXCEEDED" 5 "OFF_TRACK" 4 "UNCONTROLLED_TRAVEL_DIST_REACHED" 3 "NO_VALID_PATH" 2 "MAX_NUM_OF_MOVES" 1 "VELOCITY_TOO_HIGH" 0 "NONE" ;
VAL_ 1465 DAS_sw199_abortCodeDAS 23 "APC_ABORT_PAUSE_CYCLES" 22 "APC_ABORT_EPAS_INHIBITED" 21 "APC_ABORT_USER_KEYFOB" 20 "APC_ABORT_SC_MIA" 19 "APC_ABORT_SENSOR_FAILURE" 18 "APC_ABORT_PRECRUISE_TIMEOUT" 17 "APC_ABORT_UI_REQUEST" 16 "APC_ABORT_LOST_DI_CONTROL" 15 "APC_ABORT_PARK_GEAR" 14 "APC_ABORT_RESTART_TIMEOUT" 13 "APC_ABORT_PAUSE_USER_TIMEOUT" 12 "APC_ABORT_PAUSE_OBSTACLE_TIMEOUT" 11 "APC_ABORT_ESP_MIA" 10 "APC_ABORT_SCCM_MIA" 9 "APC_ABORT_MCU_MIA" 8 "APC_ABORT_DI_MIA" 7 "APC_ABORT_EPAS_MIA" 6 "APC_ABORT_PARK_MIA" 5 "APC_ABORT_PREGUIDANCE_TIMEOUT" 4 "APC_ABORT_INVALID_SPACE" 3 "APC_ABORT_MCU_REQUEST_MISMATCH" 2 "APC_ABORT_PARK_GUIDANCE_ENDED" 1 "APC_ABORT_LOST_ANGLE_CONTROL" 0 "APC_ABORT_NONE" ;
VAL_ 1465 DAS_sw200_autopilotIntState 15 "PRECANCEL" 14 "DRIVER_STEERING_OVERRIDE" 13 "PREABORTED" 12 "FAULT" 11 "ABORTED" 10 "ABORTING" 9 "CHECK_ACTIVATION_WHILE_UNAVAILABLE" 8 "CHECK_ACTIVATION_WHILE_DISABLED" 7 "ACTIVE_RESTRICTED" 6 "ACTIVE_NOMINAL" 5 "PREACTIVATION" 4 "CHECK_FOR_ACTIVATION" 3 "AVAILABLE" 2 "UNAVAILABLE" 1 "DISABLED" 0 "NO_AUTOPILOT" ;
VAL_ 1465 DAS_sw201_viewRangeOAL 5 "ANOMALY_LEVEL_5" 4 "ANOMALY_LEVEL_4" 3 "ANOMALY_LEVEL_3" 2 "ANOMALY_LEVEL_2" 1 "ANOMALY_LEVEL_1" 0 "ANOMALY_LEVEL_0" ;
VAL_ 1465 DAS_sw201_steeringErrorOAL 5 "ANOMALY_LEVEL_5" 4 "ANOMALY_LEVEL_4" 3 "ANOMALY_LEVEL_3" 2 "ANOMALY_LEVEL_2" 1 "ANOMALY_LEVEL_1" 0 "ANOMALY_LEVEL_0" ;
VAL_ 1465 DAS_sw201_virtualLaneInputOAL 5 "ANOMALY_LEVEL_5" 4 "ANOMALY_LEVEL_4" 3 "ANOMALY_LEVEL_3" 2 "ANOMALY_LEVEL_2" 1 "ANOMALY_LEVEL_1" 0 "ANOMALY_LEVEL_0" ;
VAL_ 1465 DAS_sw203_roadClass 6 "CLASS_6_MINOR" 5 "CLASS_5" 4 "CLASS_4" 3 "CLASS_3" 2 "CLASS_2" 1 "CLASS_1_MAJOR" 0 "UNKNOWN_INVALID_SNA" ;
VAL_ 1465 DAS_sw203_curbType 2 "HIGH_CURB" 1 "LOW_CURB" 0 "VIRTUAL_CURB" ;
VAL_ 1465 DAS_sw203_controlType 15 "SNA" 10 "PAUSE" 9 "SEARCH" 8 "COMPLETE" 7 "ABORT" 6 "PARALLEL_PULL_OUT_TO_RIGHT" 5 "PARALLEL_PULL_OUT_TO_LEFT" 4 "PARK_RIGHT_CROSS" 3 "PARK_RIGHT_PARALLEL" 2 "PARK_LEFT_CROSS" 1 "PARK_LEFT_PARALLEL" 0 "NONE" ;
VAL_ 1465 DAS_sw204_frLeftMiddle 255 "SNA" ;
VAL_ 1465 DAS_sw204_frRightMiddle 255 "SNA" ;
VAL_ 1465 DAS_sw204_frRight 255 "SNA" ;
VAL_ 1465 DAS_sw204_frLeft 255 "SNA" ;
VAL_ 1465 DAS_sw204_frMiddle 255 "SNA" ;
VAL_ 1465 DAS_sw205_rrRightMiddle 255 "SNA" ;
VAL_ 1465 DAS_sw205_rrLeftMiddle 255 "SNA" ;
VAL_ 1465 DAS_sw205_rrRight 255 "SNA" ;
VAL_ 1465 DAS_sw205_rrLeft 255 "SNA" ;
VAL_ 1465 DAS_sw205_rrMiddle 255 "SNA" ;
VAL_ 1465 DAS_sw205_oocDistance 255 "SNA" ;
VAL_ 1465 DAS_sw207_lcUnavailableReason 255 "LC_UNAVAILABLE_UNKNOWN" 19 "LC_UNAVAILABLE_VEHICLE_SPEED_ABOVE_MAX_HYST" 18 "LC_UNAVAILABLE_NOT_ON_HIGHWAY" 17 "LC_UNAVAILABLE_SPEED_LIMIT_EXCEEDED" 16 "LC_UNAVAILABLE_APP_ME_STATE_NOT_VISION" 15 "LC_UNAVAILABLE_ME_MAIN_STATE_NOT_VISION" 14 "LC_UNAVAILABLE_USER_STRIKEOUT" 13 "LC_UNAVAILABLE_EAC_REQUEST_TIMEOUT" 12 "LC_UNAVAILABLE_CAM_MSG_MIA" 11 "LC_UNAVAILABLE_HK_RESTRICTED" 10 "LC_UNAVAILABLE_CAM_WATCHDOG" 9 "LC_UNAVAILABLE_TRAILER_MODE_ACTIVE" 8 "LC_UNAVAILABLE_CAMERA_FAILSAFES" 7 "LC_UNAVAILABLE_STEERING_LIMITS_EXCEEDED" 6 "LC_UNAVAILABLE_VEHICLE_SPEED_ABOVE_MAX" 5 "LC_UNAVAILABLE_VEHICLE_NOT_IN_DRIVE" 4 "LC_UNAVAILABLE_CRUISE_FAULT" 3 "LC_UNAVAILABLE_COMPONENT_NOT_READY" 2 "LC_UNAVAILABLE_COMPONENT_MIA" 1 "LC_UNAVAILABLE_EPAS_EAC_DENIED" 0 "LC_UNAVAILABLE_NONE" ;
VAL_ 1465 DAS_sw207_appMobileyeStatus 24 "MOBILEYE_STATUS_UNDEFINED" 23 "MOBILEYE_STATUS_TEARDOWN_FLASH_ACCESS_MODE" 22 "MOBILEYE_STATUS_FLASH_READ_MODE" 21 "MOBILEYE_STATUS_SETUP_FLASH_ACCESS_MODE" 20 "MOBILEYE_STATUS_RUNNING_SPTAC_MODE" 19 "MOBILEYE_STATUS_SPTAC_INIT_SENT" 18 "MOBILEYE_STATUS_WAITING_FOR_SPTAC_INIT" 17 "MOBILEYE_STATUS_BURN_EDR_MODE" 16 "MOBILEYE_STATUS_SPC_INIT_SENT" 15 "MOBILEYE_STATUS_WAITING_FOR_SPC_INIT" 14 "MOBILEYE_STATUS_ERROR" 13 "MOBILEYE_STATUS_LATCHING_FAILURE" 12 "MOBILEYE_STATUS_UPDATING" 11 "MOBILEYE_STATUS_RUNNING_DV_MODE" 10 "MOBILEYE_STATUS_WAITING_FOR_DV" 9 "MOBILEYE_STATUS_RUNNING_TAC_MODE" 8 "MOBILEYE_STATUS_RUNNING_SPC_MODE" 7 "MOBILEYE_STATUS_RUNNING_VISION_MODE" 6 "MOBILEYE_STATUS_TAC_INIT_SENT" 5 "MOBILEYE_STATUS_WAITING_FOR_TAC_INIT" 4 "MOBILEYE_STATUS_VISION_INIT_SENT" 3 "MOBILEYE_STATUS_WAITING_FOR_VISION_INIT" 2 "MOBILEYE_STATUS_WAITING_FOR_BOOT" 1 "MOBILEYE_STATUS_POWER_OFF" 0 "MOBILEYE_STATUS_POWER_CYCLE" ;
VAL_ 1465 DAS_sw207_eyeq3MainState 172 "EYEQ_MESP_MAIN_STATE_TAC2" 170 "EYEQ_MESP_MAIN_STATE_DV" 146 "EYEQ_MESP_MAIN_STATE_VISION_INIT_PENDING" 133 "EYEQ_MESP_MAIN_STATE_TAC2_INIT_PENDING" 130 "EYEQ_MESP_MAIN_STATE_SPC_INIT_PENDING" 129 "EYEQ_MESP_MAIN_STATE_SPTAC_INIT_PENDING" 34 "EYEQ_MESP_MAIN_STATE_SPC" 33 "EYEQ_MESP_MAIN_STATE_SPTAC" 2 "EYEQ_MESP_MAIN_STATE_VISION" ;
VAL_ 1465 DAS_sw218_handsOnState 15 "LC_HANDS_ON_SNA" 7 "LC_HANDS_ON_REQD_STRUCK_OUT" 5 "LC_HANDS_ON_REQD_CHIME_2" 4 "LC_HANDS_ON_REQD_CHIME_1" 3 "LC_HANDS_ON_REQD_VISUAL" 2 "LC_HANDS_ON_REQD_NOT_DETECTED" 1 "LC_HANDS_ON_REQD_DETECTED" 0 "LC_HANDS_ON_NOT_REQD" ;
VAL_ 1001 DAS_headlightRequest 3 "DAS_HEADLIGHT_REQUEST_INVALID" 1 "DAS_HEADLIGHT_REQUEST_ON" 0 "DAS_HEADLIGHT_REQUEST_OFF" ;
VAL_ 1001 DAS_hazardLightRequest 3 "DAS_REQUEST_HAZARDS_SNA" 2 "DAS_REQUEST_HAZARDS_UNUSED" 1 "DAS_REQUEST_HAZARDS_ON" 0 "DAS_REQUEST_HAZARDS_OFF" ;
VAL_ 1001 DAS_wiperSpeed 15 "DAS_WIPER_SPEED_INVALID" 14 "DAS_WIPER_SPEED_14" 13 "DAS_WIPER_SPEED_13" 12 "DAS_WIPER_SPEED_12" 11 "DAS_WIPER_SPEED_11" 10 "DAS_WIPER_SPEED_10" 9 "DAS_WIPER_SPEED_9" 8 "DAS_WIPER_SPEED_8" 7 "DAS_WIPER_SPEED_7" 6 "DAS_WIPER_SPEED_6" 5 "DAS_WIPER_SPEED_5" 4 "DAS_WIPER_SPEED_4" 3 "DAS_WIPER_SPEED_3" 2 "DAS_WIPER_SPEED_2" 1 "DAS_WIPER_SPEED_1" 0 "DAS_WIPER_SPEED_OFF" ;
VAL_ 1001 DAS_turnIndicatorRequest 3 "DAS_TURN_INDICATOR_SNA" 2 "DAS_TURN_INDICATOR_RIGHT" 1 "DAS_TURN_INDICATOR_LEFT" 0 "DAS_TURN_INDICATOR_NONE" ;
VAL_ 1001 DAS_highLowBeamDecision 3 "DAS_HIGH_BEAM_SNA" 2 "DAS_HIGH_BEAM_ON" 1 "DAS_HIGH_BEAM_OFF" 0 "DAS_HIGH_BEAM_UNDECIDED" ;
VAL_ 1497 DAS_carLogMultiplexer 3 "PROFILER" 2 "FCM" 1 "RADAR" ;
VAL_ 1497 DAS_radarTarget5_dx 0 "NO_TARGET" ;
VAL_ 1497 DAS_radarTarget1_dx 0 "NO_TARGET" ;
VAL_ 1497 DAS_radarTarget1_VxRel 0 "NO_TARGET" ;
VAL_ 1497 DAS_fcmThreatAssesmentMode 2 "FCM_STOPLINE_MODE" 1 "FCM_VEHICLE_MODE" 0 "FCM_PEDS_MODE" ;
VAL_ 1497 DAS_constructionArea 3 "BOTH" 2 "RIGHT" 1 "LEFT" 0 "NONE" ;
VAL_ 1497 DAS_associated_rad_object 3 "ACC1" 2 "ACC5" 1 "OTHER" 0 "NONE" ;
VAL_ 1497 DAS_LC_handsOnReason 17 "VISUAL_ALC" 16 "VISUAL_LATERAL_ACCELERATION" 15 "VISUAL_TIMEOUT_THROTTLE" 14 "VISUAL_TIMEOUT_RESTRICTED" 13 "VISUAL_TIMEOUT_NO_CIPV" 12 "VISUAL_TIMEOUT_CIPV" 11 "VISUAL_TIMEOUT_CUTOUT_CIPV" 10 "VISUAL_TIMEOUT_CONSTRUCTION" 9 "VISUAL_TIMEOUT_LOW_SPEED" 8 "VISUAL_TIMEOUT_MED_SPEED" 7 "VISUAL_TIMEOUT_HI_SPEED" 6 "VISUAL_TIMEOUT_LONG_TERM" 5 "VISUAL_DRIVER_NOT_PRESENT" 4 "VISUAL_FUSION_MODEL" 3 "VISUAL_FUSION_NAV" 2 "CHIME1_CONSTRUCTION" 1 "CHIME1_ANGLE_SATURATION" 0 "LC_HANDS_ON_REASON_NONE" ;
VAL_ 1497 DAS_ACC_camStatus 3 "ACC_CAM_STATUS_FAULT" 2 "ACC_CAM_STATUS_SQUINTING" 1 "ACC_CAM_STATUS_BLIND" 0 "ACC_CAM_STATUS_HEALTHY" ;
VAL_ 1497 DAS_radarTarget2_dx 0 "NO_TARGET" ;
VAL_ 1497 DAS_radarTarget3_dx 0 "NO_TARGET" ;
VAL_ 1497 DAS_radarTarget4_dx 0 "NO_TARGET" ;
VAL_ 1033 DAS_nmKeepAwakeReason 2 "DAS_KEEPAWAKE_REASON_TELEMETRY" 1 "DAS_KEEPAWAKE_REASON_PRECONDITIONING" 0 "DAS_KEEPAWAKE_REASON_NONE_SNA" ;
VAL_ 697 DAS_setSpeed 4095 "SNA" ;
VAL_ 697 DAS_accState 15 "FAULT_SNA" 14 "ACC_CANCEL_OUT_OF_CALIBRATION" 13 "ACC_CANCEL_GENERIC_SILENT" 12 "ACC_CANCEL_PATH_NOT_CLEAR" 11 "APC_SELFPARK_START" 10 "APC_UNPARK_COMPLETE" 9 "APC_PAUSE" 8 "APC_ABORT" 7 "APC_COMPLETE" 6 "APC_FORWARD" 5 "APC_BACKWARD" 4 "ACC_ON" 3 "ACC_HOLD" 2 "ACC_CANCEL_RADAR_BLIND" 1 "ACC_CANCEL_CAMERA_BLIND" 0 "ACC_CANCEL_GENERIC" ;
VAL_ 697 DAS_aebEvent 3 "AEB_SNA" 2 "AEB_FAULT" 1 "AEB_ACTIVE" 0 "AEB_NOT_ACTIVE" ;
VAL_ 697 DAS_jerkMin 511 "SNA" ;
VAL_ 697 DAS_jerkMax 255 "SNA" ;
VAL_ 697 DAS_accelMin 511 "SNA" ;
VAL_ 697 DAS_accelMax 511 "SNA" ;
VAL_ 1529 DAS_logMltplxr 23 "DAS_L023_PMM_EVENT" 22 "DAS_L022_SCA_EVENT" 21 "DAS_L021_ME_Boot_Msg3" 20 "DAS_L020_ME_Boot_Msg2" 19 "DAS_L019_ME_Boot_Msg1" 18 "DAS_L018_ME_Boot_Msg0" 17 "DAS_L017_MESP_Health_Data" 16 "DAS_L016_Calibration_Reply" 15 "DAS_L015_Vision_Init_Msg_5" 14 "DAS_L014_Vision_Init_Msg_4" 13 "DAS_L013_Vision_Init_Msg_3" 12 "DAS_L012_Vision_Init_Msg_2" 11 "DAS_L011_Vision_Init_Msg_1" 10 "DAS_L010_Vision_Init_Msg_0" 9 "DAS_L009_FCM_EVENT4" 8 "DAS_L008_FCM_EVENT3" 7 "DAS_L007_FCM_POST_ALERT2" 6 "DAS_L006_FCM_POST_ALERT1" 5 "DAS_L005_FCM_EVENT2" 4 "DAS_L004_FCM_EVENT1" 3 "DAS_L003_BRAKING_EVENT" 2 "DAS_L002_AEB_ALERT" 1 "DAS_L001_FCW_ALERT" ;
VAL_ 1529 DAS_sender4 3 "BRAKING_EVENT" 2 "AEB_EVENT" 1 "FCW_EVENT" 0 "ME_AEB_FLAG_D" ;
VAL_ 1529 DAS_fcmMode 2 "FCM_STOPLINE_MODE" 1 "FCM_VEHICLE_MODE" 0 "FCM_PEDS_MODE" ;
VAL_ 1529 DAS_sender5 3 "BRAKING_EVENT" 2 "AEB_EVENT" 1 "FCW_EVENT" 0 "ME_AEB_FLAG_D" ;
VAL_ 1529 DAS_accUserSetting 7 "SNA" 6 "ACC_DIST_7" 5 "ACC_DIST_6" 4 "ACC_DIST_5" 3 "ACC_DIST_4" 2 "ACC_DIST_3" 1 "ACC_DIST_2" 0 "ACC_DIST_1" ;
VAL_ 1529 DAS_fcmReasonToOverride 4 "FCM_SE_BRAKE_OVERRIDE" 3 "FCM_SE_ACCEL_OVERRIDE" 2 "FCM_SE_STEER_OVERRIDE" 1 "FCM_SE_SPEED_OVERRIDE" 0 "FCM_SE_NO_OVERRIDE" ;
VAL_ 1529 DAS_sender8 3 "BRAKING_EVENT" 2 "AEB_EVENT" 1 "FCW_EVENT" 0 "ME_AEB_FLAG_D" ;
VAL_ 1529 DAS_sender9 3 "BRAKING_EVENT" 2 "AEB_EVENT" 1 "FCW_EVENT" 0 "ME_AEB_FLAG_D" ;
VAL_ 1824 DAS_debugMultiplexer 100 "DAS CH Time Sync" 68 "HM VL Degraded Inputs" 67 "HM Steering Angle Saturated" 66 "HM Steering Rate Saturated" 65 "HM Lateral Control" 64 "HM VL No Inputs" 63 "HM ME Lane Departure" 62 "HM Minimum Lane Width" 61 "HM Lane View Range" 60 "HM Path Alignment" 54 "Virtual Lane Debug5" 53 "Virtual Lane Debug4" 52 "Virtual Lane Debug3" 51 "Virtual Lane Debug2" 50 "Virtual Lane Debug1" 49 "Path_Planner" 48 "TP_LaneChange" 47 "LC_HandsOnDetector" 46 "LC_Planner_Debug" 45 "SCA" 44 "VIRTUAL_WALL_RIGHT" 43 "VIRTUAL_WALL_LEFT" 42 "HEALTH_MONITOR_2" 41 "HEALTH_MONITOR_1" 40 "Lateral Debug1" 33 "FCM Debug4" 32 "FCM Debug3" 31 "FCM Debug2" 30 "FCM Debug1" 29 "ACC Control2" 28 "ACC Control1" 27 "ACC Target6" 26 "ACC Target5" 25 "ACC Target4" 24 "ACC Target3" 23 "ACC Target2" 22 "ACC Target1" 21 "ACC Camera" 20 "ACC State" 12 "I2C debug" 11 "PMM debug" 10 "EyeQ Image Dump" 5 "Road Furniture Debug" 4 "TFL/TSR Debug" 3 "Cam Watchdog Debug" 2 "LDW Debug" 1 "EyeQ Calibrations" 0 "EyeQ Status" ;
VAL_ 1824 DAS_appMobileyeStatus 24 "MOBILEYE_STATUS_UNDEFINED" 23 "MOBILEYE_STATUS_TEARDOWN_FLASH_ACCESS_MODE" 22 "MOBILEYE_STATUS_FLASH_READ_MODE" 21 "MOBILEYE_STATUS_SETUP_FLASH_ACCESS_MODE" 20 "MOBILEYE_STATUS_RUNNING_SPTAC_MODE" 19 "MOBILEYE_STATUS_SPTAC_INIT_SENT" 18 "MOBILEYE_STATUS_WAITING_FOR_SPTAC_INIT" 17 "MOBILEYE_STATUS_BURN_EDR_MODE" 16 "MOBILEYE_STATUS_SPC_INIT_SENT" 15 "MOBILEYE_STATUS_WAITING_FOR_SPC_INIT" 14 "MOBILEYE_STATUS_ERROR" 13 "MOBILEYE_STATUS_LATCHING_FAILURE" 12 "MOBILEYE_STATUS_UPDATING" 11 "MOBILEYE_STATUS_RUNNING_DV_MODE" 10 "MOBILEYE_STATUS_WAITING_FOR_DV" 9 "MOBILEYE_STATUS_RUNNING_TAC_MODE" 8 "MOBILEYE_STATUS_RUNNING_SPC_MODE" 7 "MOBILEYE_STATUS_RUNNING_VISION_MODE" 6 "MOBILEYE_STATUS_TAC_INIT_SENT" 5 "MOBILEYE_STATUS_WAITING_FOR_TAC_INIT" 4 "MOBILEYE_STATUS_VISION_INIT_SENT" 3 "MOBILEYE_STATUS_WAITING_FOR_VISION_INIT" 2 "MOBILEYE_STATUS_WAITING_FOR_BOOT" 1 "MOBILEYE_STATUS_POWER_OFF" 0 "MOBILEYE_STATUS_POWER_CYCLE" ;
VAL_ 1824 DAS_calType 3 "SP-TAC" 2 "SPC" 1 "TAC" 0 "No Cal" ;
VAL_ 1824 DAS_laneMerge 3 "Reserved" 2 "Right Merge" 1 "Left Merge" 0 "No Merge" ;
VAL_ 1824 DAS_Stop_Sign_detected 1 "True" 0 "False" ;
VAL_ 1824 DAS_Stop_Sign_warning 1 "True" 0 "False" ;
VAL_ 1824 DAS_TFL_jnc_status 7 "Reserved_3" 6 "Green" 5 "Yellow" 4 "Red_Yellow" 3 "Red" 2 "Unknown" 1 "Reserved_1" 0 "None" ;
VAL_ 1824 DAS_apcIntState 14 "APC_INT_STATE_CENTER_STW" 13 "APC_INT_STATE_GEAR_CHANGE" 12 "APC_INT_STATE_PARKED" 11 "APC_INT_STATE_COMPLETE_UNPARKED" 10 "APC_INT_STATE_COMPLETE" 9 "APC_INT_STATE_ABORT" 8 "APC_INT_STATE_RESTART" 7 "APC_INT_STATE_PAUSE_USER_CONTROL" 6 "APC_INT_STATE_PAUSE_OBSTACLE_CONTROL" 5 "APC_INT_STATE_REVERSE_CONTROL" 4 "APC_INT_STATE_FORWARD_CONTROL" 3 "APC_INT_STATE_PREGUIDANCE" 2 "APC_INT_STATE_PRECRUISE" 1 "APC_INT_STATE_SEARCHING" 0 "APC_INT_STATE_DISABLED" ;
VAL_ 1824 DAS_SP_instruction 15 "PSC_INSTRUCTION_SNA" 4 "PSC_ABORTED" 3 "PSC_DRIVE_BACKWARD" 2 "PSC_DRIVE_FORWARD" 1 "PSC_STOP" 0 "PSC_NO_INSTRUCTION" ;
VAL_ 1824 DAS_SP_status 6 "SP_GUIDANCE_UNAVAILABLE" 5 "SP_GUIDANCE_FAULT" 4 "SP_GUIDANCE_ABORT" 3 "SP_GUIDANCE_COMPLETE" 2 "SP_GUIDANCE_UNPARK_ACTIVE" 1 "SP_GUIDANCE_PARK_ACTIVE" 0 "SP_GUIDANCE_STANDBY" ;
VAL_ 1824 DAS_estimatedSpeedLimitType 6 "SPEED_LIMIT_TYPE_INVALID" 5 "SPEED_LIMIT_TYPE_RESTRICTED" 4 "SPEED_LIMIT_TYPE_RESUME" 3 "SPEED_LIMIT_TYPE_EGO_VELOCITY" 2 "SPEED_LIMIT_TYPE_FLEET_MEDIAN" 1 "SPEED_LIMIT_TYPE_NAV_MPP" 0 "SPEED_LIMIT_TYPE_VISION" ;
VAL_ 1824 DAS_rampType 2 "RAMP_TYPE_NONE" 1 "RAMP_TYPE_ENTRACE" 0 "RAMP_TYPE_EXIT" ;
VAL_ 1824 DAS_ACC_intState 10 "Cancel Cameras Not Calibrated" 9 "Cancel for Object in Path" 8 "Fault" 7 "Cancel for Radar Blindness" 6 "Cancel for Camera Blindness" 5 "Cancel Generic" 4 "Ready to Resume" 3 "Hold" 2 "Standstill" 1 "Active" 0 "Idle" ;
VAL_ 1824 DAS_ACC_camCIPVStatus 4 "Fault" 3 "CIPV_matches_rad_CIPV" 2 "CIPV_not_rad_CIPV" 1 "CIPV_not_in_rad_list" 0 "CIPV_not_detected" ;
VAL_ 1824 DAS_ACC_radCIPVStatus 3 "Fault" 2 "CIPV_in_cam_list" 1 "CIPV_not_in_cam_list" 0 "CIPV_not_detected" ;
VAL_ 1824 DAS_ACC_pedestrianStatus 2 "Ultrasonic object" 1 "Cam free space" 0 "None" ;
VAL_ 1824 DAS_ACC_drivingOnHighway 1 "Yes" 0 "No" ;
VAL_ 1824 DAS_ACC_leftLaneExists 1 "Yes" 0 "No" ;
VAL_ 1824 DAS_ACC_rightLaneExists 1 "Yes" 0 "No" ;
VAL_ 1824 DAS_ACC_controlType 4 "ACC_CONTROL_TYPE_MIXED_LC_AND_TARGET" 3 "ACC_CONTROL_TYPE_LC" 2 "ACC_CONTROL_TYPE_TARGET" 1 "ACC_CONTROL_TYPE_CRUISE" 0 "ACC_CONTROL_TYPE_NONE" ;
VAL_ 1824 DAS_ACC_overtakeMode 2 "ACC_OVERTAKE_AUTO_ACTIVE" 1 "ACC_OVERTAKE_AUTO_PENDING" 0 "ACC_OVERTAKE_AUTO_MANUAL" ;
VAL_ 1824 DAS_ACC_camCIPVClass 5 "Pedestrian" 4 "Bicycle" 3 "Motorcycle" 2 "Car" 1 "Truck" 0 "Undecided" ;
VAL_ 1824 DAS_ACC_camCIPVRelevancy 4 "Dangerous" 3 "Cut-in" 2 "Following" 1 "Irrelevant" 0 "Unknown" ;
VAL_ 1824 DAS_ACC_camCIPVLane 5 "Next Next Right" 4 "Next Next Left" 3 "Next Right" 2 "Next Left" 1 "Ego" 0 "Not Assigned" ;
VAL_ 1824 DAS_ACC_camCIPVLaneStatus 4 "Cutting out" 3 "Cutting in" 2 "Not in ego lane" 1 "In ego lane" 0 "Unknown" ;
VAL_ 1824 DAS_ACC_camCIPVBrakeLight 2 "Off" 1 "On" 0 "Not available" ;
VAL_ 1824 DAS_ACC_camCIPVMotionStatus 8 "Oncoming moving" 7 "Oncoming unknown" 6 "Oncoming stopped" 5 "Movable moving" 4 "Movable unknown" 3 "Movable stopped" 2 "Parked" 1 "Standing" 0 "Not defined" ;
VAL_ 1824 DAS_ACC_camCIPVLost 2 "CIPV Lost" 1 "CIPV moved out of range" 0 "No loss" ;
VAL_ 1824 DAS_ACC_camCIPVFreeSpace 3 "Invalid" 2 "Unknown" 1 "Pedestrian" 0 "No Pedestrian" ;
VAL_ 1824 DAS_ACC_camStopAndGoStatus 3 "Not calculated" 2 "Undecided" 1 "Resume from stop" 0 "Do not resume from stop" ;
VAL_ 1824 DAS_ACC_camLeftCloseCutin 1 "Yes" 0 "No" ;
VAL_ 1824 DAS_ACC_camRightCloseCutin 1 "Yes" 0 "No" ;
VAL_ 1824 DAS_ACC_camPedestriansPresent 1 "Yes" 0 "No" ;
VAL_ 1824 DAS_ACC_tgt_cipv_camID 0 "SNA" ;
VAL_ 1824 DAS_ACC_tgt_cipv_radID 63 "SNA" ;
VAL_ 1824 DAS_ACC_tgt_cipv_controlState 10 "mcvr in-path" 9 "mcvr dpp" 8 "Cut in" 7 "Cut out" 6 "Overtake" 5 "Pre-Overtake" 4 "Steady state" 3 "Undertake" 2 "Default" 1 "Evaluate" 0 "Irrelevant" ;
VAL_ 1824 DAS_ACC_tgt_cipv_type 10 "Fault" 9 "Pedestrian" 8 "IPSO" 7 "Traffic Light" 6 "Stop Sign" 5 "Camera Cutin" 4 "Fused Radar" 3 "Fused Camera" 2 "Radar" 1 "Camera" 0 "None" ;
VAL_ 1824 DAS_ACC_tgt_cipv2_camID 0 "SNA" ;
VAL_ 1824 DAS_ACC_tgt_cipv2_radID 63 "SNA" ;
VAL_ 1824 DAS_ACC_tgt_cipv2_controlState 10 "mcvr in-path" 9 "mcvr dpp" 8 "Cut in" 7 "Cut out" 6 "Overtake" 5 "Pre-Overtake" 4 "Steady state" 3 "Undertake" 2 "Default" 1 "Evaluate" 0 "Irrelevant" ;
VAL_ 1824 DAS_ACC_tgt_cipv2_type 10 "Fault" 9 "Pedestrian" 8 "IPSO" 7 "Traffic Light" 6 "Stop Sign" 5 "Camera Cutin" 4 "Fused Radar" 3 "Fused Camera" 2 "Radar" 1 "Camera" 0 "None" ;
VAL_ 1824 DAS_ACC_tgt_mcvl_camID 0 "SNA" ;
VAL_ 1824 DAS_ACC_tgt_mcvl_radID 63 "SNA" ;
VAL_ 1824 DAS_ACC_tgt_mcvl_controlState 10 "mcvr in-path" 9 "mcvr dpp" 8 "Cut in" 7 "Cut out" 6 "Overtake" 5 "Pre-Overtake" 4 "Steady state" 3 "Undertake" 2 "Default" 1 "Evaluate" 0 "Irrelevant" ;
VAL_ 1824 DAS_ACC_tgt_mcvl_type 10 "Fault" 9 "Pedestrian" 8 "IPSO" 7 "Traffic Light" 6 "Stop Sign" 5 "Camera Cutin" 4 "Fused Radar" 3 "Fused Camera" 2 "Radar" 1 "Camera" 0 "None" ;
VAL_ 1824 DAS_ACC_tgt_mcvr_camID 0 "SNA" ;
VAL_ 1824 DAS_ACC_tgt_mcvr_radID 63 "SNA" ;
VAL_ 1824 DAS_ACC_tgt_mcvr_controlState 10 "mcvr in-path" 9 "mcvr dpp" 8 "Cut in" 7 "Cut out" 6 "Overtake" 5 "Pre-Overtake" 4 "Steady state" 3 "Undertake" 2 "Default" 1 "Evaluate" 0 "Irrelevant" ;
VAL_ 1824 DAS_ACC_tgt_mcvr_type 10 "Fault" 9 "Pedestrian" 8 "IPSO" 7 "Traffic Light" 6 "Stop Sign" 5 "Camera Cutin" 4 "Fused Radar" 3 "Fused Camera" 2 "Radar" 1 "Camera" 0 "None" ;
VAL_ 1824 DAS_ACC_tgt_cutin_camID 0 "SNA" ;
VAL_ 1824 DAS_ACC_tgt_cutin_radID 63 "SNA" ;
VAL_ 1824 DAS_ACC_tgt_cutin_controlState 10 "mcvr in-path" 9 "mcvr dpp" 8 "Cut in" 7 "Cut out" 6 "Overtake" 5 "Pre-Overtake" 4 "Steady state" 3 "Undertake" 2 "Default" 1 "Evaluate" 0 "Irrelevant" ;
VAL_ 1824 DAS_ACC_tgt_cutin_type 10 "Fault" 9 "Pedestrian" 8 "IPSO" 7 "Traffic Light" 6 "Stop Sign" 5 "Camera Cutin" 4 "Fused Radar" 3 "Fused Camera" 2 "Radar" 1 "Camera" 0 "None" ;
VAL_ 1824 DAS_ACC_Target6_camID 0 "SNA" ;
VAL_ 1824 DAS_ACC_Target6_radID 63 "SNA" ;
VAL_ 1824 DAS_ACC_Target6_controlState 10 "mcvr in-path" 9 "mcvr dpp" 8 "Cut in" 7 "Cut out" 6 "Overtake" 5 "Pre-Overtake" 4 "Steady state" 3 "Undertake" 2 "Default" 1 "Evaluate" 0 "Irrelevant" ;
VAL_ 1824 DAS_ACC_Target6_type 10 "Fault" 9 "Pedestrian" 8 "IPSO" 7 "Traffic Light" 6 "Stop Sign" 5 "Camera Cutin" 4 "Fused Radar" 3 "Fused Camera" 2 "Radar" 1 "Camera" 0 "None" ;
VAL_ 1824 DAS_ACC_Control_targetID 5 "Stop Sign_Traffic Light" 4 "Cut in or pedestrian" 3 "MCVR" 2 "MCVL" 1 "In front of CIPV" 0 "CIPV" ;
VAL_ 1824 DAS_ACC_Restrict_targetID 5 "Stop Sign_Traffic Light" 4 "Cut in or pedestrian" 3 "MCVR" 2 "MCVL" 1 "In front of CIPV" 0 "CIPV" ;
VAL_ 1824 DAS_IDF_objectClass 5 "PEDESTRIAN" 4 "BICYCLE" 3 "MOTORCYCLE" 2 "CAR" 1 "TRUCK" 0 "UNKNOWN" ;
VAL_ 1824 DAS_LC_AutopilotInternalState 15 "LC_INTERNAL_STATE_PRECANCEL" 14 "LC_INTERNAL_STATE_DRIVER_STEERING_OVERRIDE" 13 "LC_INTERNAL_STATE_PREABORTED" 12 "LC_INTERNAL_STATE_FAULT" 11 "LC_INTERNAL_STATE_ABORTED" 10 "LC_INTERNAL_STATE_ABORTING" 9 "LC_INTERNAL_STATE_CHECK_ACTIVATION_WHILE_UNAVAILABLE" 8 "LC_INTERNAL_STATE_CHECK_ACTIVATION_WHILE_DISABLED" 7 "LC_INTERNAL_STATE_ACTIVE_RESTRICTED" 6 "LC_INTERNAL_STATE_ACTIVE_NOMINAL" 5 "LC_INTERNAL_STATE_PREACTIVATION" 4 "LC_INTERNAL_STATE_CHECK_FOR_ACTIVATION" 3 "LC_INTERNAL_STATE_AVAILABLE" 2 "LC_INTERNAL_STATE_UNAVAILABLE" 1 "LC_INTERNAL_STATE_DISABLED" 0 "LC_INTERNAL_STATE_NO_AUTOPILOT" ;
VAL_ 1824 DAS_HmLaneViewRangeOAL 5 "ANOMALY_LEVEL_5" 4 "ANOMALY_LEVEL_4" 3 "ANOMALY_LEVEL_3" 2 "ANOMALY_LEVEL_2" 1 "ANOMALY_LEVEL_1" 0 "ANOMALY_LEVEL_0" ;
VAL_ 1824 DAS_HmVlNoInputsOAL 5 "ANOMALY_LEVEL_5" 4 "ANOMALY_LEVEL_4" 3 "ANOMALY_LEVEL_3" 2 "ANOMALY_LEVEL_2" 1 "ANOMALY_LEVEL_1" 0 "ANOMALY_LEVEL_0" ;
VAL_ 1824 DAS_VWall_Left_ultra_dist 500 "NO_OBJECT_DETECTED" ;
VAL_ 1824 DAS_VWall_Right_ultra_dist 500 "NO_OBJECT_DETECTED" ;
VAL_ 1824 DAS_SCA_state 4 "FAULT" 3 "AVOIDANCE" 2 "AVAILABLE" 1 "UNAVAILABLE" 0 "DISABLED" ;
VAL_ 1824 DAS_hands_on_detected 1 "True" 0 "False" ;
VAL_ 1824 DAS_Planner_internalstate 9 "TP_INTSTATE_LANECHANGE_COMPLETE" 8 "TP_INTSTATE_LANECHANGE_JOIN_DEST_LANE" 7 "TP_INTSTATE_LANECHANGE_ABORT" 6 "TP_INTSTATE_LANECHANGE_LEAVE_EGO_LANE" 5 "TP_INTSTATE_LANECHANGE_WAIT_FOR_FWD_OBSTACLE" 4 "TP_INTSTATE_LANECHANGE_WAIT_FOR_SIDE_OBSTACLE" 3 "TP_INTSTATE_LANECHANGE_REQUESTED" 2 "TP_INTSTATE_FOLLOW" 1 "TP_INTSTATE_VL" 0 "TP_INTSTATE_DISABLED" ;
VAL_ 1824 DAS_Planner_externalstate 7 "TP_EXTSTATE_LANECHANGE_ABORT" 6 "TP_EXTSTATE_LANECHANGE_WAIT_FOR_FWD_OBSTACLE" 5 "TP_EXTSTATE_LANECHANGE_WAIT_FOR_SIDE_OBSTACLE" 4 "TP_EXTSTATE_LANECHANGE_IN_PROGRESS" 3 "TP_EXTSTATE_LANECHANGE_REQUESTED" 2 "TP_EXTSTATE_FOLLOW" 1 "TP_EXTSTATE_VL" 0 "TP_EXTSTATE_DISABLED" ;
VAL_ 1824 DAS_csa_internal_state 4 "CSA_INTERNAL_STATE_ENABLE_HOLD" 3 "CSA_INTERNAL_STATE_ENABLE_ACCELEROMETER" 2 "CSA_INTERNAL_STATE_ENABLE_PREDICTED" 1 "CSA_INTERNAL_STATE_AVAILABLE" 0 "CSA_INTERNAL_STATE_UNAVAILABLE" ;
VAL_ 1824 DAS_pp_lanechange_side 2 "NONE" 1 "RIGHT" 0 "LEFT" ;
VAL_ 1824 DAS_VL_WidthMeasType 7 "ONE_LINE_AND_HPP" 6 "NO_MEAS_LOW_SPEED" 5 "HOLDING" 4 "DECAY_TO_NOMINAL" 3 "BOTH_FREESPACE" 2 "RIGHT_LANE_LEFT_FREESPACE" 1 "LEFT_LANE_RIGHT_FREESPACE" 0 "BOTH_LANES" ;
VAL_ 1824 DAS_VL_Mode 9 "FUSED" 8 "NAV" 7 "SUPERNAV" 6 "HPP" 5 "CIPV" 4 "BOTH_LANES" 3 "RIGHT_LANE" 2 "LEFT_LANE" 1 "MODEL" 0 "INIT_SNA" ;
VAL_ 1824 DAS_VL_LinePreference 5 "DRIVING_SIDE" 4 "AVOID_ONCOMING" 3 "NEXT_LANE_EXISTENCE" 2 "NEXT_LANE_LINE_DETECTION" 1 "NEXT_LANE_DEVIATION" 0 "PREFERENCE_NOT_REQUIRED" ;
